VERSION ""

NS_ :

BS_:

BU_: IDC Delete_FDCA Delete_APA Delete_CMRR_FL Delete_CMRR_FR CMRR_RL CMRR_RR MRR CGW

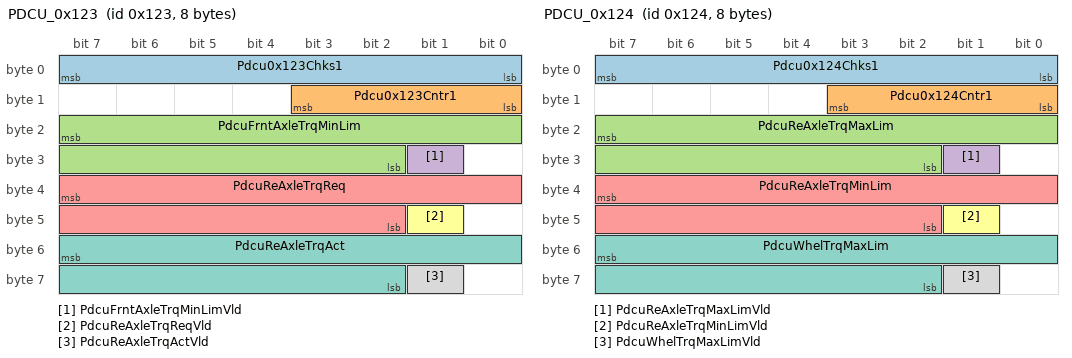
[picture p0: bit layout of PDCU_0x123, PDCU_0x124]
BO_ 291 PDCU_0x123: 8 CGW
 SG_ Pdcu0x123Chks1 : 7|8@0+ (1,0) [0|255] "" IDC,Delete_FDCA
 SG_ Pdcu0x123Cntr1 : 11|4@0+ (1,0) [0|14] "" IDC,Delete_FDCA
 SG_ PdcuFrntAxleTrqMinLim : 23|14@0+ (1,-6000) [-6000|10000] "Nm" IDC,Delete_FDCA
 SG_ PdcuFrntAxleTrqMinLimVld : 25|1@0+ (1,0) [0|1] "" IDC,Delete_FDCA
 SG_ PdcuReAxleTrqReq : 39|14@0+ (1,-6000) [-6000|10000] "Nm" IDC,Delete_FDCA
 SG_ PdcuReAxleTrqReqVld : 41|1@0+ (1,0) [0|1] "" IDC,Delete_FDCA
 SG_ PdcuReAxleTrqAct : 55|14@0+ (1,-6000) [-6000|10000] "Nm" IDC,Delete_FDCA
 SG_ PdcuReAxleTrqActVld : 57|1@0+ (1,0) [0|1] "" IDC,Delete_FDCA

BO_ 292 PDCU_0x124: 8 CGW
 SG_ Pdcu0x124Chks1 : 7|8@0+ (1,0) [0|255] "" IDC,Delete_FDCA
 SG_ Pdcu0x124Cntr1 : 11|4@0+ (1,0) [0|14] "" IDC,Delete_FDCA
 SG_ PdcuReAxleTrqMaxLim : 23|14@0+ (1,-6000) [-6000|10000] "Nm" IDC,Delete_FDCA
 SG_ PdcuReAxleTrqMaxLimVld : 25|1@0+ (1,0) [0|1] "" IDC,Delete_FDCA
 SG_ PdcuReAxleTrqMinLim : 39|14@0+ (1,-6000) [-6000|10000] "Nm" IDC,Delete_FDCA
 SG_ PdcuReAxleTrqMinLimVld : 41|1@0+ (1,0) [0|1] "" IDC,Delete_FDCA
 SG_ PdcuWhelTrqMaxLim : 55|14@0+ (1,-6000) [-6000|10000] "Nm" IDC,Delete_FDCA
 SG_ PdcuWhelTrqMaxLimVld : 57|1@0+ (1,0) [0|1] "" IDC,Delete_FDCA

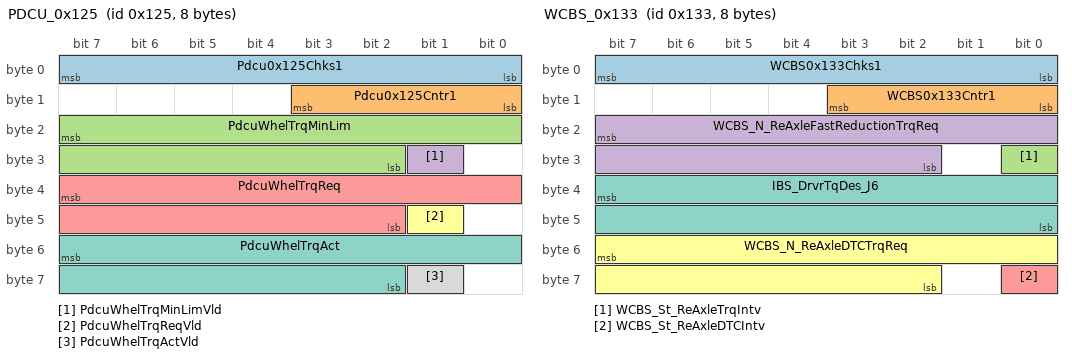
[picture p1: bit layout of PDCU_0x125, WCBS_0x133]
BO_ 293 PDCU_0x125: 8 CGW
 SG_ Pdcu0x125Chks1 : 7|8@0+ (1,0) [0|255] "" IDC,Delete_FDCA
 SG_ Pdcu0x125Cntr1 : 11|4@0+ (1,0) [0|14] "" IDC,Delete_FDCA
 SG_ PdcuWhelTrqMinLim : 23|14@0+ (1,-6000) [-6000|10000] "Nm" IDC,Delete_FDCA
 SG_ PdcuWhelTrqMinLimVld : 25|1@0+ (1,0) [0|1] "" IDC,Delete_FDCA
 SG_ PdcuWhelTrqReq : 39|14@0+ (1,-6000) [-6000|10000] "Nm" IDC,Delete_FDCA
 SG_ PdcuWhelTrqReqVld : 41|1@0+ (1,0) [0|1] "" IDC,Delete_FDCA
 SG_ PdcuWhelTrqAct : 55|14@0+ (1,-6000) [-6000|10000] "Nm" IDC,Delete_FDCA
 SG_ PdcuWhelTrqActVld : 57|1@0+ (1,0) [0|1] "" IDC,Delete_FDCA

BO_ 306 WCBS_0x132: 8 CGW
 SG_ WCBS0x132Chks1 : 7|8@0+ (1,0) [0|255] "" IDC,Delete_FDCA
 SG_ WCBS0x132Cntr1 : 11|4@0+ (1,0) [0|14] "" IDC,Delete_FDCA
 SG_ WCBS_St_FrntAxleTrqIntv : 24|1@0+ (1,0) [0|1] "" IDC,Delete_FDCA
 SG_ WCBS_N_FrntAxleFastReductionTrqReq : 23|14@0+ (1,-6000) [-6000|10000] "Nm" IDC,Delete_FDCA
 SG_ WCBS_St_FrntAxleDTCIntv : 56|1@0+ (1,0) [0|1] "" IDC,Delete_FDCA
 SG_ WCBS_N_FrntAxleDTCTrqReq : 55|14@0+ (1,-6000) [-6000|10000] "Nm" IDC,Delete_FDCA
 SG_ WCBS_RPAavailable : 32|1@0+ (1,0) [0|1] "" IDC
 SG_ WCBS_MEBavailable : 36|1@0+ (1,0) [0|1] "" IDC
 SG_ WCBS_APLCSts : 35|3@0+ (1,0) [0|7] "" IDC
 SG_ WCBS_ActvIndcn_MEB : 40|1@0+ (1,0) [0|1] "" IDC
 SG_ WCBS_APLCFailureSts : 39|3@0+ (1,0) [0|7] "" IDC
 SG_ WCBS_BrakeHld : 41|1@0+ (1,0) [0|1] "" IDC
 SG_ WCBS_ADASL12AvlSts : 44|1@0+ (1,0) [0|1] "" IDC
 SG_ WCBS_LgtReqModeACtiveSts : 43|2@0+ (1,0) [0|3] "" IDC
 SG_ WCBS_ADLCFailureSts : 47|3@0+ (1,0) [0|7] "" IDC
 SG_ WCBS_APAavailable : 25|1@0+ (1,0) [0|1] "" IDC
 SG_ WCBS_OMPavailable : 57|1@0+ (1,0) [0|1] "" IDC

BO_ 307 WCBS_0x133: 8 CGW
 SG_ WCBS0x133Chks1 : 7|8@0+ (1,0) [0|255] "" IDC,Delete_FDCA
 SG_ WCBS0x133Cntr1 : 11|4@0+ (1,0) [0|14] "" IDC,Delete_FDCA
 SG_ WCBS_St_ReAxleTrqIntv : 24|1@0+ (1,0) [0|1] "" IDC,Delete_FDCA
 SG_ WCBS_N_ReAxleFastReductionTrqReq : 23|14@0+ (1,-6000) [-6000|10000] "Nm" IDC,Delete_FDCA
 SG_ WCBS_St_ReAxleDTCIntv : 56|1@0+ (1,0) [0|1] "" IDC,Delete_FDCA
 SG_ WCBS_N_ReAxleDTCTrqReq : 55|14@0+ (1,-6000) [-6000|10000] "Nm" IDC,Delete_FDCA
 SG_ IBS_DrvrTqDes_J6 : 39|16@0+ (1,-65535) [-65535|0] "Nm" IDC

BO_ 337 MCUR0x151: 16 CGW
 SG_ TM2CrtTqVld : 15|2@0+ (1,0) [0|3] "" IDC,Delete_FDCA
 SG_ TM2CrtRotDir : 13|2@0+ (1,0) [0|3] "" IDC,Delete_FDCA
 SG_ TM2CrtSpd : 23|16@0+ (1,-32768) [-32768|32767] "rpm" IDC,Delete_FDCA
 SG_ TM2CrtTq : 39|16@0+ (0.1,-3276.8) [-3276.8|3276.7] "N·m" IDC,Delete_FDCA
 SG_ TM2CrtSpdSigVld : 50|2@0+ (1,0) [0|3] "" IDC,Delete_FDCA
 SG_ TM2ElockSt : 85|4@0+ (1,0) [0|6] "" IDC,Delete_FDCA,Delete_APA
 SG_ TM2ELockMod : 103|4@0+ (1,0) [0|8] "" IDC,Delete_FDCA,Delete_APA

BO_ 545 MCUR0x221: 32 CGW
 SG_ TM2MaxTqPeak : 87|16@0+ (0.1,-3276.8) [-3276.8|3276.7] "N·m" IDC,Delete_FDCA
 SG_ TM2MinTqPeak : 103|16@0+ (0.1,-3276.8) [-3276.8|3276.7] "N·m" IDC,Delete_FDCA
 SG_ TM2MaxTqCon : 151|16@0+ (0.1,-3276.8) [-3276.8|3276.7] "N·m" IDC,Delete_FDCA
 SG_ TM2MinTqCon : 167|16@0+ (0.1,-3276.8) [-3276.8|3276.7] "N·m" IDC,Delete_FDCA

BO_ 336 MCUF0x150: 16 CGW
 SG_ TM1CrtTqVld : 13|2@0+ (1,0) [0|3] "" IDC,Delete_FDCA
 SG_ TM1CrtRotDir : 15|2@0+ (1,0) [0|3] "" IDC,Delete_FDCA
 SG_ TM1CrtSpd : 23|16@0+ (1,-32768) [-32768|32767] "rpm" IDC,Delete_FDCA
 SG_ TM1CrtTq : 39|16@0+ (0.1,-3276.8) [-3276.8|3276.7] "N·m" IDC,Delete_FDCA
 SG_ TM1CrtSpdSigVld : 54|2@0+ (1,0) [0|3] "" IDC,Delete_FDCA

BO_ 551 MCUF0x227: 32 CGW
 SG_ TM1MaxTqPeak : 87|16@0+ (0.1,-3276.8) [-3276.8|3276.7] "N·m" IDC,Delete_FDCA
 SG_ TM1MinTqPeak : 103|16@0+ (0.1,-3276.8) [-3276.8|3276.7] "N·m" IDC,Delete_FDCA
 SG_ TM1MaxTqCon : 151|16@0+ (0.1,-3276.8) [-3276.8|3276.7] "N·m" IDC,Delete_FDCA
 SG_ TM1MinTqCon : 167|16@0+ (0.1,-3276.8) [-3276.8|3276.7] "N·m" IDC,Delete_FDCA

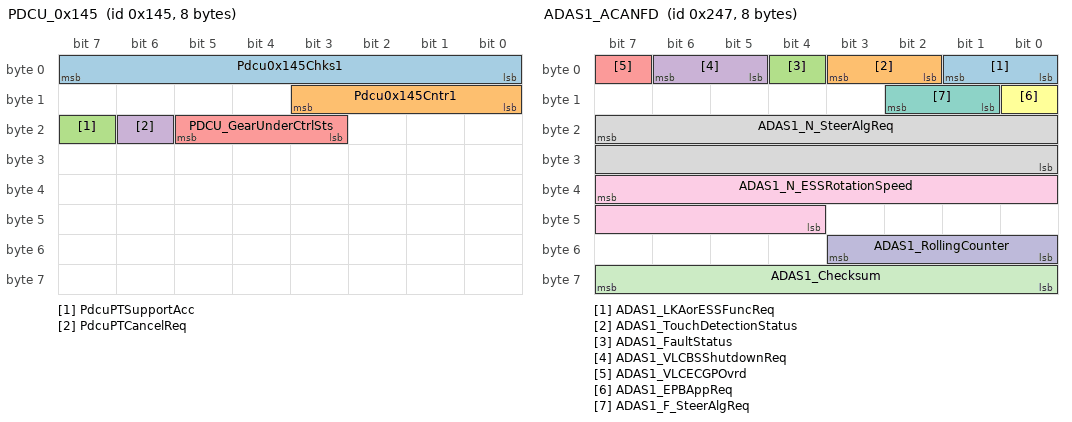
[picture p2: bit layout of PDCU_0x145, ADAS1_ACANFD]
BO_ 325 PDCU_0x145: 8 CGW
 SG_ Pdcu0x145Chks1 : 7|8@0+ (1,0) [0|255] "" IDC,Delete_FDCA,Delete_APA
 SG_ Pdcu0x145Cntr1 : 11|4@0+ (1,0) [0|14] "" IDC,Delete_FDCA,Delete_APA
 SG_ PdcuPTSupportAcc : 23|1@0+ (1,0) [0|1] "" IDC,Delete_FDCA
 SG_ PdcuPTCancelReq : 22|1@0+ (1,0) [0|1] "" IDC,Delete_FDCA
 SG_ PDCU_GearUnderCtrlSts : 21|3@0+ (1,0) [0|7] "" IDC,Delete_APA

BO_ 583 ADAS1_ACANFD: 8 IDC
 SG_ ADAS1_LKAorESSFuncReq : 1|2@0+ (1,0) [0|3] "" CGW
 SG_ ADAS1_TouchDetectionStatus : 3|2@0+ (1,0) [0|3] "" Vector__XXX
 SG_ ADAS1_FaultStatus : 4|1@0+ (1,0) [0|1] "" Vector__XXX
 SG_ ADAS1_VLCBSShutdownReq : 6|2@0+ (1,0) [0|3] "" Vector__XXX
 SG_ ADAS1_VLCECGPOvrd : 7|1@0+ (1,0) [0|1] "" Vector__XXX
 SG_ ADAS1_EPBAppReq : 8|1@0+ (1,0) [0|1] "" Vector__XXX
 SG_ ADAS1_F_SteerAlgReq : 10|2@0+ (1,0) [0|3] "" CGW
 SG_ ADAS1_N_SteerAlgReq : 23|16@0+ (0.1,-780) [-780|780] "°" CGW
 SG_ ADAS1_N_ESSRotationSpeed : 39|12@0+ (1,-2048) [-2048|2046] "degree/ sec" CGW
 SG_ ADAS1_RollingCounter : 51|4@0+ (1,0) [0|15] "" CGW
 SG_ ADAS1_Checksum : 63|8@0+ (1,0) [0|255] "" CGW

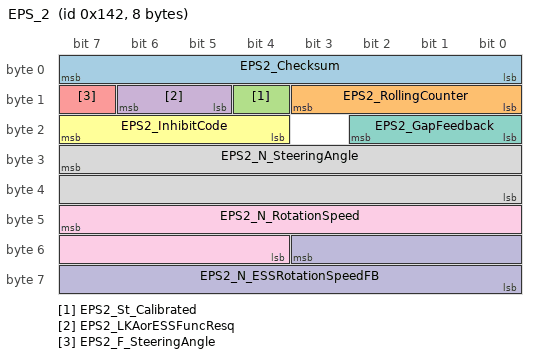
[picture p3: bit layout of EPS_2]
BO_ 322 EPS_2: 8 CGW
 SG_ EPS2_Checksum : 7|8@0+ (1,0) [0|15] "" IDC,Delete_FDCA,Delete_APA
 SG_ EPS2_RollingCounter : 11|4@0+ (1,0) [0|15] "" IDC,Delete_FDCA,Delete_APA
 SG_ EPS2_St_Calibrated : 12|1@0+ (1,0) [0|1] "" IDC,Delete_FDCA,Delete_APA
 SG_ EPS2_LKAorESSFuncResq : 14|2@0+ (1,0) [0|3] "" IDC,Delete_FDCA,Delete_APA
 SG_ EPS2_F_SteeringAngle : 15|1@0+ (1,0) [0|1] "" IDC,Delete_FDCA,Delete_APA
 SG_ EPS2_InhibitCode : 23|4@0+ (1,0) [0|15] "" IDC,Delete_FDCA,Delete_APA
 SG_ EPS2_GapFeedback : 18|3@0+ (1,0) [0|7] "" IDC,Delete_FDCA,Delete_APA
 SG_ EPS2_N_SteeringAngle : 31|16@0+ (0.1,-780) [-780|780] "degree" IDC,Delete_FDCA,Delete_APA
 SG_ EPS2_N_RotationSpeed : 47|12@0+ (4,-1016) [-1016|1016] "degree/ sec" IDC,Delete_FDCA,Delete_APA
 SG_ EPS2_N_ESSRotationSpeedFB : 51|12@0+ (1,-2048) [-2048|2046] "degree/ sec" IDC,Delete_FDCA,Delete_APA

BO_ 1508 FDCA_1: 8 IDC
 SG_ FDCA1_St_SLASpdlimit : 7|8@0+ (1,0) [0|255] "" CGW
 SG_ FDCA1_St_SLAWarning : 15|2@0+ (1,0) [0|3] "" CGW
 SG_ ADAS_FDCA1_St_SLASpeedLimitUnit : 13|2@0+ (1,0) [0|3] "" CGW
 SG_ FDCA1_St_LDWMode : 11|3@0+ (1,0) [0|7] "" CGW
 SG_ ADAS_FDCA1_ESS_SwitchSts : 8|1@0+ (1,0) [0|1] "" CGW
 SG_ FDCA1_St_AEBMode : 23|2@0+ (1,0) [0|3] "" CGW
 SG_ FDCA1_St_LKA : 21|3@0+ (1,0) [0|7] "" CGW
 SG_ FDCA1_St_TSRMode : 18|3@0+ (1,0) [0|7] "" CGW
 SG_ FDCA1_W_Handsoff : 31|2@0+ (1,0) [0|3] "" CGW
 SG_ ADAS_FDCA1_AdasSafestopAppdReq : 29|2@0+ (1,0) [0|3] "" CGW
 SG_ ADAS_FDCA1_Sts_ESS : 27|4@0+ (1,0) [0|7] "" CGW
 SG_ ADAS_FDCA1_St_FCWMode : 39|3@0+ (1,0) [0|7] "" CGW
 SG_ ADAS_FDCA1_St_TSRwarning : 35|1@0+ (1,0) [0|1] "" CGW
 SG_ ADAS_FDCA1_LDW_meter_Warning : 34|2@0+ (1,0) [0|3] "" CGW
 SG_ ADC_PrivacyAgreementSts : 42|2@0+ (1,0) [0|1] "" CGW
 SG_ FDCA1_St_VehicleMode : 40|3@0+ (1,0) [0|7] "" CGW
 SG_ ADAS_FDCA1_ESSTraj : 53|2@0+ (1,0) [0|3] "" CGW
 SG_ FDCA1_RollingCounter : 51|4@0+ (1,0) [0|15] "" CGW
 SG_ FDCA1_CheckSum : 63|8@0+ (1,0) [0|255] "" CGW

BO_ 1351 FDCA_2: 8 IDC
 SG_ FDCA2_N_vSetDisp : 7|8@0+ (1,0) [0|255] "KPH" CGW
 SG_ FDCA2_St_dxTarObj : 15|3@0+ (1,0) [0|7] "" CGW
 SG_ FDCA2_St_TauGapSet : 12|3@0+ (1,0) [0|7] "" CGW
 SG_ FDCA2_St_LateralTakeoverReq : 9|1@0+ (1,0) [0|1] "" CGW
 SG_ FDCA2_St_HighbeamReq : 8|1@0+ (1,0) [0|1] "" CGW
 SG_ FDCA2_St_HMA : 23|3@0+ (1,0) [0|7] "" CGW
 SG_ FDCA2_St_ACCMode_HMI : 20|4@0+ (1,0) [0|15] "" CGW
 SG_ ADAS_SafeStopHazardLlightReq : 16|1@0+ (1,0) [0|1] "" CGW
 SG_ FDCA2_St_TakeOverReq : 31|1@0+ (1,0) [0|1] "" CGW
 SG_ FDCA2_St_LeftVisualization : 30|2@0+ (1,0) [0|3] "" CGW
 SG_ ADAS_FDCA2_St_TauGapWinRequest : 28|1@0+ (1,0) [0|1] "" CGW
 SG_ ADAS_NOA_Right_turn_light_Req : 27|1@0+ (1,0) [0|1] "" CGW
 SG_ ADAS_NOA_left_turn_light_Req : 26|1@0+ (1,0) [0|1] "" CGW
 SG_ FDCA2_St_RightVisualization : 25|2@0+ (1,0) [0|3] "" CGW
 SG_ FDCA2_St_TJA_ICA_mode : 39|3@0+ (1,0) [0|7] "" CGW
 SG_ ADAS_FDCA2_AccObjDetd : 36|1@0+ (1,0) [0|1] "" Vector__XXX
 SG_ FDCA2_AccTxtInfo : 35|4@0+ (1,0) [0|15] "" CGW
 SG_ FDCA2_St_Camera : 47|2@0+ (1,0) [0|3] "" CGW
 SG_ FDCA2_W_Distance : 45|1@0+ (1,0) [0|1] "" CGW
 SG_ FDCA2_St_FCWSensitivity : 44|2@0+ (1,0) [0|3] "" CGW
 SG_ ADAS_SafeStopDoorUnlockReq : 42|1@0+ (1,0) [0|1] "" CGW
 SG_ FDCA2_W_FCWpreWarning : 41|2@0+ (1,0) [0|3] "" CGW
 SG_ ADAS_St_LowbeamReq : 54|1@0+ (1,0) [0|1] "" CGW
 SG_ FDCA2_St_TSR : 53|2@0+ (1,0) [0|3] "" CGW
 SG_ FDCA2_RollingCounter : 51|4@0+ (1,0) [0|15] "" CGW
 SG_ FDCA2_Checksum : 63|8@0+ (1,0) [0|255] "" CGW

BO_ 915 ADAS2_ACANFD: 64 IDC
 SG_ ADAS2_Checksum1 : 7|8@0+ (1,0) [0|255] "" CGW
 SG_ ADAS2_RollingCounter1 : 11|4@0+ (1,0) [0|15] "" CGW
 SG_ ADAS2_Radar_TextInfo : 39|4@0+ (1,0) [0|15] "" CGW
 SG_ ADAS2_AccfobjDrvAwayinfo : 40|1@0+ (1,0) [0|1] "" CGW
 SG_ ADAS2_TLA_WarnSign : 43|2@0+ (1,0) [0|3] "" CGW
 SG_ ADAS2_St_MRR : 45|2@0+ (1,0) [0|3] "" CGW
 SG_ ADAS2_Accdrivemode : 47|2@0+ (1,0) [0|3] "" CGW
 SG_ ADAS2_ASLSts : 50|3@0+ (1,0) [0|7] "" CGW
 SG_ ADAS2_ASLSpdlim : 55|5@0+ (1,0) [0|31] "" CGW
 SG_ ADAS2_St_TJA_ICA_Textinfo : 59|4@0+ (1,0) [0|15] "" CGW
 SG_ ADAS2_ASLSwtfb : 60|1@0+ (1,0) [0|1] "" CGW
 SG_ ADAS2_ALCSts : 63|3@0+ (1,0) [0|3] "" CGW
 SG_ ADAS2_Checksum2 : 71|8@0+ (1,0) [0|255] "" CGW
 SG_ ADAS1_RollingCounter2 : 75|4@0+ (1,0) [0|15] "" CGW
 SG_ ADAS2_NOASts : 79|4@0+ (1,0) [0|15] "" CGW
 SG_ ADAS2_HwaAlcSwtFb : 80|1@0+ (1,0) [0|1] "" CGW
 SG_ ADAS2_TJA_ICA__EnbSwtFb : 81|1@0+ (1,0) [0|1] "" CGW
 SG_ ADAS2_NOA_ALC_TYPE_SwtFb : 83|2@0+ (1,0) [0|3] "" CGW
 SG_ ADAS2_NOA_ALCRequest_confirm_Fb : 84|1@0+ (1,0) [0|1] "" CGW
 SG_ ADAS2_NOA_ALCSoundnotification_SwtFb : 85|1@0+ (1,0) [0|1] "" CGW
 SG_ ADAS2_IntelligentCornering_EnbSw_SwtFb : 86|1@0+ (1,0) [0|1] "" CGW
 SG_ ADAS2_NOASwtFb : 87|1@0+ (1,0) [0|1] "" CGW
 SG_ ADAS2_DrvrHandsoffRmn : 95|8@0+ (0.5,0) [0|127] "" CGW
 SG_ ADAS2_DriverHandsoff : 96|1@0+ (1,0) [0|1] "" CGW
 SG_ ADAS2_ICATJATakeoverReq : 99|3@0+ (1,0) [0|7] "" CGW
 SG_ ADAS2_ALCHmiEgoLaneChg : 103|4@0+ (1,0) [0|15] "" CGW
 SG_ ADAS2_ALCActvToTakeover : 107|4@0+ (1,0) [0|15] "" CGW
 SG_ ADAS2_NLP_FctActvRmm : 111|4@0+ (1,0) [0|15] "" CGW
 SG_ ADAS2_NLPTakeoverReq : 114|3@0+ (1,0) [0|7] "" CGW
 SG_ ADAS2_TJAICA_LINE_SOURCE : 116|2@0+ (1,0) [0|3] "" CGW
 SG_ ADAS2_ALCNotAvlReas : 119|3@0+ (1,0) [0|7] "" CGW
 SG_ ADAS2_NOAHmiDispdTxtMsgId : 125|6@0+ (1,0) [0|63] "" CGW
 SG_ ADAS2_TLA_SwitchSts : 127|2@0+ (1,0) [0|3] "" CGW
 SG_ ADAS2_Checksum3 : 135|8@0+ (1,0) [0|255] "" CGW
 SG_ ADAS2_RollingCounter3 : 139|4@0+ (1,0) [0|15] "" CGW
 SG_ ADAS2_NOAODDTyp : 143|4@0+ (1,0) [0|15] "" CGW
 SG_ ADAS2_NOADstToODD : 148|5@0+ (1,0) [0|31] "" CGW
 SG_ ADAS2_TextinfoForIntelligentCornering : 151|2@0+ (1,0) [0|3] "" CGW
 SG_ ADAS2_NotAvlReas : 155|4@0+ (1,0) [0|15] "" CGW
 SG_ ADAS2_HmiAudioNotifId : 159|4@0+ (1,0) [0|15] "" CGW
 SG_ ADAS2_ADASQuitReas : 164|5@0+ (1,0) [0|31] "" CGW
 SG_ ADAS2_Set_TJA_ICA_ACC : 166|2@0+ (1,0) [0|3] "" CGW
 SG_ ADAS2_St_left_front_Camera : 169|2@0+ (1,0) [0|3] "" CGW
 SG_ ADAS2_St_right_front_Camera : 171|2@0+ (1,0) [0|3] "" CGW
 SG_ ADAS2_St_LDWLKALCKSenFb : 173|2@0+ (1,0) [0|3] "" CGW
 SG_ ADAS2_Sw_LDWLKALCKFb : 175|2@0+ (1,0) [0|3] "" CGW
 SG_ ADAS2_St_LDWLKALCKSetFb : 178|3@0+ (1,0) [0|7] "" CGW
 SG_ ADAS2_SwFb_ELK : 180|2@0+ (1,0) [0|3] "" CGW
 SG_ ADAS2_St_LDWLKALCK : 183|3@0+ (1,0) [0|7] "" CGW
 SG_ ADAS2_St_ELK : 185|2@0+ (1,0) [0|3] "" CGW
 SG_ ADAS2_St_ELKIntvMod : 188|3@0+ (1,0) [0|7] "" CGW
 SG_ ADAS2_SwFb_HMA : 191|2@0+ (1,0) [0|3] "" CGW
 SG_ ADAS2_Checksum4 : 199|8@0+ (1,0) [0|255] "" CGW
 SG_ ADAS2_RollingCounter4 : 203|4@0+ (1,0) [0|15] "" CGW
 SG_ ADAS2_SDASts : 206|3@0+ (1,0) [0|7] "" CGW
 SG_ ADAS2_DodgeDirection_SDA : 207|1@0+ (1,0) [0|1] "" CGW
 SG_ ADAS2_TgtVehicleID_SDA : 211|4@0+ (1,0) [0|15] "" CGW
 SG_ ADAS2_ALC_HMIlaneBlock : 213|2@0+ (1,0) [0|3] "" CGW
 SG_ ADAS2_TSR_SwtFb : 215|2@0+ (1,0) [0|3] "" CGW
 SG_ ADAS2_SwFb_SDA : 217|2@0+ (1,0) [0|3] "" CGW
 SG_ ADAS_FDCA1_SLA_SwitchSts : 219|2@0+ (1,0) [0|3] "" CGW
 SG_ ADAS_FDCA1_SLA_SpdLimOffs : 223|4@0+ (1,0) [0|15] "KPH" CGW
 SG_ ADAS2_AEBTxtInfo : 227|4@0+ (1,0) [0|15] "" CGW
 SG_ ADAS2_FcwTxtInfo : 231|4@0+ (1,0) [0|15] "" CGW
 SG_ ADAS2_TsrSignMisc : 236|5@0+ (1,0) [0|32] "" CGW
 SG_ ADAS2_St_SLAMode : 239|3@0+ (1,0) [0|7] "" CGW
 SG_ ADAS2_St_SLAFault : 241|2@0+ (1,0) [0|3] "" CGW
 SG_ ADAS2_FcwSwtFb : 243|2@0+ (1,0) [0|3] "" CGW
 SG_ ADAS2_AebSwtFb : 245|2@0+ (1,0) [0|3] "" CGW
 SG_ ADAS_FDCA1_SLAWarn_SwitchSts : 247|2@0+ (1,0) [0|3] "" CGW
 SG_ ADAS2_AebReq : 250|3@0+ (1,0) [0|7] "" CGW
 SG_ ADAS2_HWASts : 255|4@0+ (1,0) [0|15] "" CGW
 SG_ ADAS2_Checksum5 : 263|8@0+ (1,0) [0|255] "" CGW
 SG_ ADAS2_RollingCounter5 : 267|4@0+ (1,0) [0|15] "" CGW
 SG_ ADAS2_BvmSetFb : 269|2@0+ (1,0) [0|3] "" CGW
 SG_ ADAS2_BvmDispReq : 271|2@0+ (1,0) [0|3] "" CGW
 SG_ ADAS2_St_left_rear_Camera : 273|2@0+ (1,0) [0|3] "" CGW
 SG_ ADAS2_St_right_rear_Camera : 275|2@0+ (1,0) [0|3] "" CGW
 SG_ ADAS2_BvmViewMod : 276|1@0+ (1,0) [0|1] "" CGW
 SG_ ADAS2_St_ELKSenFeedback : 278|2@0+ (1,0) [0|3] "" CGW
 SG_ ADC_ADASYSSTS : 279|1@0+ (1,0) [0|1] "" Vector__XXX
 SG_ ADC_enum_PrkgBuzAlrmLvlReq : 282|3@0+ (1,0) [0|7] "" Vector__XXX
 SG_ ADC_SysStartupInPro : 283|1@0+ (1,0) [0|1] "" Vector__XXX
 SG_ ADC_IMUSentiWarningSts : 286|3@0+ (1,0) [0|7] "" Vector__XXX
 SG_ MPC_SOCOffSwtFb : 295|2@0+ (1,0) [0|3] "" Vector__XXX

BO_ 547 ADAS3_ACANFD: 64 IDC
 SG_ AdasHmiNeighboringObj1ObjTyp : 7|3@0+ (1,0) [0|7] "" CGW
 SG_ Obj1Ttc : 4|5@0+ (0.1,0) [0|3.1] "" CGW
 SG_ AdasHmiNeighboringObj1XOut : 15|8@0+ (1.2,-50) [-50|250] "m" CGW
 SG_ AdasHmiNeighboringObj1YOut : 23|8@0+ (0.06,-7.5) [-7.5|7.5] "m" CGW
 SG_ Obj1VX : 31|13@0+ (0.0312,-128) [-128|126.9976] "m/s" CGW
 SG_ Obj1ObjExistProb : 47|5@0+ (0.03125,0) [0|0.96875] "" CGW
 SG_ Obj1Hei : 42|9@0+ (0.01,0) [0|5.11] "m" CGW
 SG_ Obj1Width : 49|9@0+ (0.01,0) [0|5.11] "m" CGW
 SG_ AdasHmiNeighboringObj2ObjTyp : 71|3@0+ (1,0) [0|7] "" CGW
 SG_ Obj2ObjExistProb : 68|5@0+ (0.03125,0) [0|0.96875] "" CGW
 SG_ AdasHmiNeighboringObj2XOut : 79|8@0+ (1.2,-50) [-50|250] "m" CGW
 SG_ AdasHmiNeighboringObj2YOut : 87|8@0+ (0.06,-7.5) [-7.5|7.5] "m" CGW
 SG_ Obj2VelX : 95|13@0+ (0.0312,-128) [-128|126.9976] "m/s" CGW
 SG_ AdasHmiNeighboringObj3ObjTyp : 111|3@0+ (1,0) [0|7] "-" CGW
 SG_ Obj3ObjExistProb : 108|5@0+ (0.03125,0) [0|0.96875] "" CGW
 SG_ AdasHmiNeighboringObj3XOut : 119|8@0+ (1.2,-50) [-50|250] "m" CGW

BO_TX_BU_ 583 : IDC,Delete_FDCA;

BO_TX_BU_ 1508 : IDC,Delete_FDCA;

BO_TX_BU_ 1351 : IDC,Delete_FDCA;

BO_TX_BU_ 915 : IDC,Delete_FDCA;

BO_TX_BU_ 547 : IDC,Delete_FDCA;
CM_ BO_ 583 "控制，ADAS1_F_SteerAlgReq与B41不一致";
CM_ BO_ 1508 "显示";
CM_ BO_ 1351 "显示";
CM_ BO_ 915 "显示";
CM_ BO_ 547 "HMI 目标车辆信息，12个";
CM_ SG_ 583 ADAS1_LKAorESSFuncReq "ADAS系统EPS请求类型，表示是LKA还是ESS";
CM_ SG_ 583 ADAS1_TouchDetectionStatus "驾驶员的手是否放在方向盘上";
CM_ SG_ 583 ADAS1_FaultStatus "系统失效状态，此信号表示自动ADAS系统失效状态";
CM_ SG_ 583 ADAS1_VLCBSShutdownReq "ADAS 退出VLC";
CM_ SG_ 583 ADAS1_VLCECGPOvrd "ADAS 功能是否由驾驶员踩油门接管车辆扭矩状态";
CM_ SG_ 583 ADAS1_EPBAppReq "表示请求拉起EPB 信号";
CM_ SG_ 583 ADAS1_F_SteerAlgReq "转角请求状态ADAS对EPS的补偿角度请求状态";
CM_ SG_ 583 ADAS1_N_SteerAlgReq "转角请求ADAS对EPS的补偿角度请求";
CM_ SG_ 583 ADAS1_N_ESSRotationSpeed "ESS功能请求方向盘转速";
CM_ SG_ 583 ADAS1_RollingCounter "Message counter for each message transmittedThe transmitter shall update the value of the Message Counter signal every time a frame is transmitted (even if no other data in the frame has changed value). The counter value shall be updated in the sequence 0, 1, 2, 3......15, 0, 1, 2, 3......15, etc. Upon startup,the initial value of the Message Counter signal shall be 0.";
CM_ SG_ 583 ADAS1_Checksum "Checksum = (byte0+byte1+…+byte 6）and 0xFF";
CM_ SG_ 1508 FDCA1_St_SLASpdlimit "Speed Limit速度限制；最高车速";
CM_ SG_ 1508 FDCA1_St_SLAWarning "SLA Warning";
CM_ SG_ 1508 ADAS_FDCA1_St_SLASpeedLimitUnit "SLA Speed Limit UnitSLA限速单位";
CM_ SG_ 1508 FDCA1_St_LDWMode "LDW Mode";
CM_ SG_ 1508 ADAS_FDCA1_ESS_SwitchSts "ESS开关状态反馈信号";
CM_ SG_ 1508 FDCA1_St_AEBMode "AEB Mode（预留），删除";
CM_ SG_ 1508 FDCA1_St_LKA "LKA Mode";
CM_ SG_ 1508 FDCA1_St_TSRMode "TSR Mode";
CM_ SG_ 1508 FDCA1_W_Handsoff "脱手检测报警信号";
CM_ SG_ 1508 ADAS_FDCA1_AdasSafestopAppdReq "Safe stop: Brake actuator shall be able to secure the vehicle by activating the ESP/EPB. ECALL shall be connecting by T-box";
CM_ SG_ 1508 ADAS_FDCA1_Sts_ESS "ESS功能状态，状态机";
CM_ SG_ 1508 ADAS_FDCA1_St_FCWMode "FCW Mode";
CM_ SG_ 1508 ADAS_FDCA1_St_TSRwarning "TSR失效状态";
CM_ SG_ 1508 ADAS_FDCA1_LDW_meter_Warning "LDW报警";
CM_ SG_ 1508 ADC_PrivacyAgreementSts "查询整车隐私协议开关";
CM_ SG_ 1508 FDCA1_St_VehicleMode "FDCA接收到车辆模式信号后返回的状态信号";
CM_ SG_ 1508 ADAS_FDCA1_ESSTraj "ESS规划路径状态";
CM_ SG_ 1508 FDCA1_RollingCounter "Message counter for each message transmittedThe transmitter shall update the value of the Message Counter signal every time a frame is transmitted (even if no other data in theframe has changed value). The counter value shall be updated in the sequence 0, 1, 2, 3......15, 0, 1, 2, 3......15, etc. Upon startup,theinitial value of the Message Counter signal shall be 0.";
CM_ SG_ 1508 FDCA1_CheckSum "Checksum = (byte0+byte1+…+byte 6）and 0xFF";
CM_ SG_ 1351 FDCA2_N_vSetDisp "the set speed from driver, should be available as long as ACC is active.";
CM_ SG_ 1351 FDCA2_St_dxTarObj "distance to the ahead target object in case of 'mid-end' HMI.";
CM_ SG_ 1351 FDCA2_St_TauGapSet "the set time Gap from driver, should be displayed to driver and if the set value changes.";
CM_ SG_ 1351 FDCA2_St_LateralTakeoverReq "Horizontal function takeover request";
CM_ SG_ 1351 FDCA2_St_HighbeamReq "High beam Request";
CM_ SG_ 1351 FDCA2_St_HMA "HMA Mode (light switching function) HMA状态机（远近灯光切换功能）";
CM_ SG_ 1351 FDCA2_St_ACCMode_HMI "The status of the ACC control unit.The ACC mode should be contained in every message sent by ACC.";
CM_ SG_ 1351 ADAS_SafeStopHazardLlightReq "Safe stop: need turn on the hazard light";
CM_ SG_ 1351 FDCA2_St_TakeOverReq "the limits of the ACC control reaches, driver should take over.";
CM_ SG_ 1351 FDCA2_St_LeftVisualization "LDW/LKA Left Side InterventionLDW/LKA左侧介入";
CM_ SG_ 1351 ADAS_FDCA2_St_TauGapWinRequest "TauGap Windows Request ";
CM_ SG_ 1351 ADAS_NOA_Right_turn_light_Req "NOA右变道灯请求";
CM_ SG_ 1351 ADAS_NOA_left_turn_light_Req "NOA左变道灯请求";
CM_ SG_ 1351 FDCA2_St_RightVisualization "LDW/LKA Right Side InterventionLDW/LKA右侧介入";
CM_ SG_ 1351 FDCA2_St_TJA_ICA_mode "TJA ModeTJA状态机";
CM_ SG_ 1351 ADAS_FDCA2_AccObjDetd "an ahead target object detected by ACC, to inform the driver 一般会与ACC_DIS_TO_TAROBJECT同时显示，但是当只打开ACC的主开关，但是没有激活ACC功能的话，ACC_DIS_TO_TAROBJECT不会显示，但这个信号会显示。";
CM_ SG_ 1351 FDCA2_AccTxtInfo "Textinfo for Driver which is displayed in Dashboard";
CM_ SG_ 1351 FDCA2_St_Camera "Camera status information摄像头状态信息";
CM_ SG_ 1351 FDCA2_W_Distance "DistanceWarning";
CM_ SG_ 1351 FDCA2_St_FCWSensitivity "FCW灵敏度设置反馈信号";
CM_ SG_ 1351 ADAS_SafeStopDoorUnlockReq "Safe stop: need tunlock the door when the vehicle is standstill ";
CM_ SG_ 1351 FDCA2_W_FCWpreWarning "acoustic pre warning.Used with FCW_Enable signal.";
CM_ SG_ 1351 ADAS_St_LowbeamReq "近光灯信号请求";
CM_ SG_ 1351 FDCA2_St_TSR "TSR报警模式选择";
CM_ SG_ 1351 FDCA2_RollingCounter "Message counter for each message transmittedThe transmitter shall update the value of the Message Counter signal every time a frame is transmitted (even if no other data in theframe has changed value). The counter value shall be updated in the sequence 0, 1, 2, 3......15, 0, 1, 2, 3......15, etc. Upon startup,theinitial value of the Message Counter signal shall be 0.";
CM_ SG_ 1351 FDCA2_Checksum "Checksum = (byte0+byte1+…+byte 6）and 0xFF";
CM_ SG_ 915 ADAS2_Checksum1 "Checksum = (byte1+byte2+…+byte 7）and 0xFF";
CM_ SG_ 915 ADAS2_RollingCounter1 "Message counter for each message transmittedThe transmitter shall update the value of the Message Counter signal every time a frame is transmitted (even if no other data in the frame has changed value). The counter value shall be updated in the sequence 0, 1, 2, 3......15, 0, 1, 2, 3......15, etc. Upon startup,the initial value of the Message Counter signal shall be 0.";
CM_ SG_ 915 ADAS2_Radar_TextInfo "雷达文字弹窗提醒";
CM_ SG_ 915 ADAS2_AccfobjDrvAwayinfo "Indacating front vehicle drive away or not, used for ICM reminder. When front vehicle drives away, the signal will be set to 0x1.前车驶离提示。";
CM_ SG_ 915 ADAS2_TLA_WarnSign "TLA交通灯识别信号";
CM_ SG_ 915 ADAS2_St_MRR "Mrr status information雷达状态信息";
CM_ SG_ 915 ADAS2_Accdrivemode "indicate the Status of ACC acceleration calibration line。";
CM_ SG_ 915 ADAS2_ASLSts "Adaptive Speed Limiter StatusStatus of ASL function";
CM_ SG_ 915 ADAS2_ASLSpdlim "Speed limit values for ASL function";
CM_ SG_ 915 ADAS2_St_TJA_ICA_Textinfo "TJA Status text infomationTJA状态文字";
CM_ SG_ 915 ADAS2_ASLSwtfb "ASL开关状态反馈";
CM_ SG_ 915 ADAS2_ALCSts "State Machine for ALC for HMI";
CM_ SG_ 915 ADAS2_Checksum2 "Checksum = (byte9+byte10+…+byte 15）and 0xFF";
CM_ SG_ 915 ADAS1_RollingCounter2 "Message counter for each message transmittedThe transmitter shall update the value of the Message Counter signal every time a frame is transmitted (even if no other data in the frame has changed value). The counter value shall be updated in the sequence 0, 1, 2, 3......15, 0, 1, 2, 3......15, etc. Upon startup,the initial value of the Message Counter signal shall be 0.";
CM_ SG_ 915 ADAS2_NOASts "NOA状态";
CM_ SG_ 915 ADAS2_HwaAlcSwtFb "HWA ALC switch feedback";
CM_ SG_ 915 ADAS2_TJA_ICA__EnbSwtFb "tja/ica  switch feedback";
CM_ SG_ 915 ADAS2_NOA_ALC_TYPE_SwtFb "NOA_ALC_TYPE switch feedback";
CM_ SG_ 915 ADAS2_NOA_ALCRequest_confirm_Fb "NOA_ALCRequest_confirm switch feedback";
CM_ SG_ 915 ADAS2_NOA_ALCSoundnotification_SwtFb "NOA_ALC_soundnotification switch feedback";
CM_ SG_ 915 ADAS2_IntelligentCornering_EnbSw_SwtFb "Intelligent cornering_EnbSw switch feedback";
CM_ SG_ 915 ADAS2_NOASwtFb "HWA HF switch feedback.Reserved.";
CM_ SG_ 915 ADAS2_DrvrHandsoffRmn "Instruct the driver hands off to drop the count";
CM_ SG_ 915 ADAS2_DriverHandsoff "Indicates whether the driver's hands are on the steering wheel";
CM_ SG_ 915 ADAS2_ICATJATakeoverReq "脱手报警TJA or ICA Take over request to driver";
CM_ SG_ 915 ADAS2_ALCHmiEgoLaneChg "Indicates when the ego vehicle plans or performs a lane change";
CM_ SG_ 915 ADAS2_ALCActvToTakeover "ALC active to takeover reason";
CM_ SG_ 915 ADAS2_NLP_FctActvRmm "NLP Function Active reminder";
CM_ SG_ 915 ADAS2_NLPTakeoverReq "NLP Take over request to driver";
CM_ SG_ 915 ADAS2_TJAICA_LINE_SOURCE "The line source of TJA ICA.video 视觉模式，基于video识别的车道线进行控制;DOP Drive Object Path，基于目标车辆进行控制; TIPL Traffic in Parallel Line ，基于车流轨迹算法给出的车道线进行控制.";
CM_ SG_ 915 ADAS2_ALCNotAvlReas "ADAS ALC  function not available Reason";
CM_ SG_ 915 ADAS2_NOAHmiDispdTxtMsgId "Displays visual text notfications on the cockpit ";
CM_ SG_ 915 ADAS2_TLA_SwitchSts "TLA开关状态反馈信号";
CM_ SG_ 915 ADAS2_Checksum3 "Checksum = (byte17+byte18+…+byte 23）and 0xFF";
CM_ SG_ 915 ADAS2_RollingCounter3 "Message counter for each message transmittedThe transmitter shall update the value of the Message Counter signal every time a frame is transmitted (even if no other data in the frame has changed value). The counter value shall be updated in the sequence 0, 1, 2, 3......15, 0, 1, 2, 3......15, etc. Upon startup,the initial value of the Message Counter signal shall be 0.";
CM_ SG_ 915 ADAS2_NOAODDTyp "the next ODD‘s type";
CM_ SG_ 915 ADAS2_NOADstToODD "The distance to ODD area when NOA is on";
CM_ SG_ 915 ADAS2_TextinfoForIntelligentCornering "智能过弯文字提示";
CM_ SG_ 915 ADAS2_NotAvlReas "ADAS function not available Reason";
CM_ SG_ 915 ADAS2_HmiAudioNotifId "Plays back an auditory sound notification, e.g. warning sound or speech message.";
CM_ SG_ 915 ADAS2_ADASQuitReas "ADAS function exit Reason";
CM_ SG_ 915 ADAS2_Set_TJA_ICA_ACC "TJAICA、ACC巡航状态反馈";
CM_ SG_ 915 ADAS2_St_left_front_Camera "左前侧视摄像头状态";
CM_ SG_ 915 ADAS2_St_right_front_Camera "右前侧视摄像头状态";
CM_ SG_ 915 ADAS2_St_LDWLKALCKSenFb "LDW/LKA/LCK灵敏度设置反馈信号";
CM_ SG_ 915 ADAS2_Sw_LDWLKALCKFb "LDW/LKA/LCK系统上层软开关反馈信号";
CM_ SG_ 915 ADAS2_St_LDWLKALCKSetFb "辅助类型选择开关反馈信号";
CM_ SG_ 915 ADAS2_SwFb_ELK "ELK开启关闭反馈状态信号";
CM_ SG_ 915 ADAS2_St_LDWLKALCK "LDW/LKA/LCK系统工作状态信号";
CM_ SG_ 915 ADAS2_St_ELK "ELK功能状态信号";
CM_ SG_ 915 ADAS2_St_ELKIntvMod "ELK仪表提醒信息";
CM_ SG_ 915 ADAS2_SwFb_HMA "HMA开启关闭反馈状态信号";
CM_ SG_ 915 ADAS2_Checksum4 "Checksum = (byte25+byte26+…+byte 31）and 0xFF";
CM_ SG_ 915 ADAS2_RollingCounter4 "Message counter for each message transmittedThe transmitter shall update the value of the Message Counter signal every time a frame is transmitted (even if no other data in the frame has changed value). The counter value shall be updated in the sequence 0, 1, 2, 3......15, 0, 1, 2, 3......15, etc. Upon startup,the initial value of the Message Counter signal shall be 0.";
CM_ SG_ 915 ADAS2_SDASts "智慧躲闪状态信号";
CM_ SG_ 915 ADAS2_DodgeDirection_SDA "躲闪方向信号，用于车机显示";
CM_ SG_ 915 ADAS2_TgtVehicleID_SDA "关键目标ID, 用于在SDA激活状态下，使仪表显示时将目标车高亮显示";
CM_ SG_ 915 ADAS2_ALC_HMIlaneBlock "HWA与仪表交互提示";
CM_ SG_ 915 ADAS2_TSR_SwtFb "TSR开关反馈信号";
CM_ SG_ 915 ADAS2_SwFb_SDA "智慧躲闪开关状态反馈信号";
CM_ SG_ 915 ADAS_FDCA1_SLA_SwitchSts "SLA速度限制提醒开关状态反馈信号";
CM_ SG_ 915 ADAS_FDCA1_SLA_SpdLimOffs "SLA偏差值反馈信号";
CM_ SG_ 915 ADAS2_AEBTxtInfo "Textinfo for Driver which is displayed in Dashboard";
CM_ SG_ 915 ADAS2_FcwTxtInfo "Textinfo for Driver which is displayed in Dashboard";
CM_ SG_ 915 ADAS2_TsrSignMisc "识别出的交通标志";
CM_ SG_ 915 ADAS2_St_SLAMode "SLA Mode";
CM_ SG_ 915 ADAS2_St_SLAFault "SLA Fault";
CM_ SG_ 915 ADAS2_FcwSwtFb "FCW swtich feedback, indicating FCW function is enabled or not. ";
CM_ SG_ 915 ADAS2_AebSwtFb "AEB swtich feedback, indicating AEB function is enabled or not.";
CM_ SG_ 915 ADAS_FDCA1_SLAWarn_SwitchSts "SLA超速报警开关状态反馈信号";
CM_ SG_ 915 ADAS2_AebReq "Request of the AEB/EBA/AEB-VRU deceleration control.";
CM_ SG_ 915 ADAS2_HWASts "HWA状态信号";
CM_ SG_ 915 ADAS2_Checksum5 "Checksum = (byte33+byte34+…+byte 39）and 0xFF";
CM_ SG_ 915 ADAS2_RollingCounter5 "Message counter for each message transmittedThe transmitter shall update the value of the Message Counter signal every time a frame is transmitted (even if no other data in the frame has changed value). The counter value shall be updated in the sequence 0, 1, 2, 3......15, 0, 1, 2, 3......15, etc. Upon startup,the initial value of the Message Counter signal shall be 0.";
CM_ SG_ 915 ADAS2_BvmSetFb "盲区影像开关反馈信号";
CM_ SG_ 915 ADAS2_BvmDispReq "盲区影像功能请求显示";
CM_ SG_ 915 ADAS2_St_left_rear_Camera "左后侧视摄像头故障";
CM_ SG_ 915 ADAS2_St_right_rear_Camera "右后侧视摄像头故障";
CM_ SG_ 915 ADAS2_BvmViewMod "盲区影像视图";
CM_ SG_ 915 ADAS2_St_ELKSenFeedback "ELK灵敏度设置反馈信号";
CM_ SG_ 915 ADC_ADASYSSTS "ADC行车系统故障状态";
CM_ SG_ 915 ADC_enum_PrkgBuzAlrmLvlReq "雷达报警提示音";
CM_ SG_ 915 ADC_SysStartupInPro "System startup in progress系统启动状态标志位";
CM_ SG_ 915 ADC_IMUSentiWarningSts "IMU报警信号";
CM_ SG_ 915 MPC_SOCOffSwtFb "智驾节能模式开关反馈";
CM_ SG_ 547 AdasHmiNeighboringObj1ObjTyp "Provides the type of the neihboring Object no. 1";
CM_ SG_ 547 Obj1Ttc "Time to Collision with target Object";
CM_ SG_ 547 AdasHmiNeighboringObj1XOut "Provides the location of the neighboring Object no.1 as a longitudinal distance from ego center";
CM_ SG_ 547 AdasHmiNeighboringObj1YOut "Provides the location of the neighboring Object no.1 as a lateral distance from ego center";
CM_ SG_ 547 Obj1VX "Relative target object velocity in x-direction";
CM_ SG_ 547 Obj1ObjExistProb "The probability of an object to exist in reality";
CM_ SG_ 547 Obj1Hei "Height of the object";
CM_ SG_ 547 Obj1Width "Width of the object";
CM_ SG_ 547 AdasHmiNeighboringObj2ObjTyp "Provides the type of the neihboring Object no. 2";
CM_ SG_ 547 Obj2ObjExistProb "The probability of an object to exist in reality";
CM_ SG_ 547 AdasHmiNeighboringObj2XOut "Provides the location of the neighboring Object no.1 as a longitudinal distance from ego center";
CM_ SG_ 547 AdasHmiNeighboringObj2YOut "Provides the location of the neighboring Object no.1 as a lateral distance from ego center";
CM_ SG_ 547 Obj2VelX "Relative target object velocity in x-direction";
CM_ SG_ 547 AdasHmiNeighboringObj3ObjTyp "Provides the type of the neihboring Object no. 3";
CM_ SG_ 547 Obj3ObjExistProb "The probability of an object to exist in reality";
CM_ SG_ 547 AdasHmiNeighboringObj3XOut "Provides the location of the neighboring Object no.1 as a longitudinal distance from ego center";
CM_ SG_ 291 Pdcu0x123Chks1 "CRC checksum. DataID and the following 7 bytes are included in CRC checksum calculation. Refer to E2E Spec.（Profile：1A，DataID=0x002C）";
CM_ SG_ 291 Pdcu0x123Cntr1 "Rolling counter. Refer to E2E Spec.";
CM_ SG_ 291 PdcuFrntAxleTrqMinLim "前轴最小可用扭矩";
CM_ SG_ 291 PdcuFrntAxleTrqMinLimVld "前轴最小可用扭矩有效位";
CM_ SG_ 291 PdcuReAxleTrqReq "后轴需求扭矩";
CM_ SG_ 291 PdcuReAxleTrqReqVld "后轴需求扭矩有效位";
CM_ SG_ 291 PdcuReAxleTrqAct "后轴实际扭矩";
CM_ SG_ 291 PdcuReAxleTrqActVld "后轴实际扭矩有效位";
CM_ SG_ 292 Pdcu0x124Chks1 "CRC checksum. DataID and the following 7 bytes are included in CRC checksum calculation. Refer to E2E Spec.（Profile：1A，DataID=0x002D）";
CM_ SG_ 292 Pdcu0x124Cntr1 "Rolling counter. Refer to E2E Spec.";
CM_ SG_ 292 PdcuReAxleTrqMaxLim "后轴最大可用扭矩";
CM_ SG_ 292 PdcuReAxleTrqMaxLimVld "后轴最大可用扭矩有效位";
CM_ SG_ 292 PdcuReAxleTrqMinLim "后轴最小可用扭矩";
CM_ SG_ 292 PdcuReAxleTrqMinLimVld "后轴最小可用扭矩有效位";
CM_ SG_ 292 PdcuWhelTrqMaxLim "轮端最大可用扭矩";
CM_ SG_ 292 PdcuWhelTrqMaxLimVld "轮端最大可用扭矩有效位";
CM_ SG_ 293 Pdcu0x125Chks1 "CRC checksum. DataID and the following 7 bytes are included in CRC checksum calculation. Refer to E2E Spec.（Profile：1A，DataID=0x002E）";
CM_ SG_ 293 Pdcu0x125Cntr1 "Rolling counter. Refer to E2E Spec.";
CM_ SG_ 293 PdcuWhelTrqMinLim "轮端最小可用扭矩";
CM_ SG_ 293 PdcuWhelTrqMinLimVld "轮端最小可用扭矩有效位";
CM_ SG_ 293 PdcuWhelTrqReq "轮端驾驶员需求扭矩";
CM_ SG_ 293 PdcuWhelTrqReqVld "轮端驾驶员需求扭矩有效位";
CM_ SG_ 293 PdcuWhelTrqAct "轮端实际扭矩";
CM_ SG_ 293 PdcuWhelTrqActVld "轮端实际扭矩有效位";
CM_ SG_ 306 WCBS0x132Chks1 "CRC checksum. DataID and the following 7 bytes are included in CRC checksum calculation. Refer to E2E Spec.（Profile：1A，DataID=0x002F）";
CM_ SG_ 306 WCBS0x132Cntr1 "Rolling counter. Refer to E2E Spec.";
CM_ SG_ 306 WCBS_St_FrntAxleTrqIntv "前轴扭矩降扭干预请求";
CM_ SG_ 306 WCBS_N_FrntAxleFastReductionTrqReq "前轴快扭降扭干预";
CM_ SG_ 306 WCBS_St_FrntAxleDTCIntv "前轴升扭矩请求标志位";
CM_ SG_ 306 WCBS_N_FrntAxleDTCTrqReq "前轴升扭矩请求";
CM_ SG_ 306 WCBS_RPAavailable "RPA可用";
CM_ SG_ 306 WCBS_MEBavailable "MEB可用";
CM_ SG_ 306 WCBS_APLCSts "WCBS响应APA状态";
CM_ SG_ 306 WCBS_ActvIndcn_MEB "MEB是否激活";
CM_ SG_ 306 WCBS_APLCFailureSts "WCBS退出APA握手原因";
CM_ SG_ 306 WCBS_BrakeHld "WCBS保压标志位";
CM_ SG_ 306 WCBS_ADASL12AvlSts "WCBS纵向控制可用状态";
CM_ SG_ 306 WCBS_LgtReqModeACtiveSts "WCBS纵向控制请求模式激活状态";
CM_ SG_ 306 WCBS_ADLCFailureSts "WCBS退出握手的原因信号";
CM_ SG_ 306 WCBS_APAavailable "APA可用";
CM_ SG_ 306 WCBS_OMPavailable "WCBS是否支持APA功能信号";
CM_ SG_ 307 WCBS0x133Chks1 "CRC checksum. DataID and the following 7 bytes are included in CRC checksum calculation. Refer to E2E Spec.（Profile：1A，DataID=0x0030）";
CM_ SG_ 307 WCBS0x133Cntr1 "Rolling counter. Refer to E2E Spec.";
CM_ SG_ 307 WCBS_St_ReAxleTrqIntv "后轴扭矩降扭干预请求";
CM_ SG_ 307 WCBS_N_ReAxleFastReductionTrqReq "后轴快扭降扭干预";
CM_ SG_ 307 WCBS_St_ReAxleDTCIntv "后轴升扭矩请求标志位";
CM_ SG_ 307 WCBS_N_ReAxleDTCTrqReq "后轴升扭矩请求";
CM_ SG_ 307 IBS_DrvrTqDes_J6 "驾驶员需求制动力矩";
CM_ SG_ 337 TM2CrtTqVld "后驱动电机当前转矩有效位";
CM_ SG_ 337 TM2CrtRotDir "后驱动电机当前旋转方向";
CM_ SG_ 337 TM2CrtSpd "后驱动电机当前转速";
CM_ SG_ 337 TM2CrtTq "后驱动电机当前转矩";
CM_ SG_ 337 TM2CrtSpdSigVld "后驱动电机当前转速信号有效位";
CM_ SG_ 337 TM2ElockSt "e-Lock执行状态";
CM_ SG_ 337 TM2ELockMod "e-Lock工作状态";
CM_ SG_ 545 TM2MaxTqPeak "后电机最大峰值扭矩";
CM_ SG_ 545 TM2MinTqPeak "后电机最小峰值扭矩";
CM_ SG_ 545 TM2MaxTqCon "后电机最大持续扭矩";
CM_ SG_ 545 TM2MinTqCon "后电机最小持续扭矩";
CM_ SG_ 336 TM1CrtTqVld "前驱动电机当前转矩有效位（默认发0x1）";
CM_ SG_ 336 TM1CrtRotDir "前驱动电机当前旋转方向";
CM_ SG_ 336 TM1CrtSpd "前驱动电机当前转速";
CM_ SG_ 336 TM1CrtTq "前驱动电机当前转矩";
CM_ SG_ 336 TM1CrtSpdSigVld "前驱动电机当前转速信号有效位（发默认值0x1）";
CM_ SG_ 551 TM1MaxTqPeak "前电机最大峰值扭矩";
CM_ SG_ 551 TM1MinTqPeak "前电机最小峰值扭矩";
CM_ SG_ 551 TM1MaxTqCon "前电机最大持续扭矩（按峰值扭矩的一半反馈）";
CM_ SG_ 551 TM1MinTqCon "前电机最小持续扭矩（按峰值扭矩的一半反馈）";
CM_ SG_ 325 Pdcu0x145Chks1 "CRC checksum. DataID and the following 7 bytes are included in CRC checksum calculation. Refer to E2E Spec.（Profile：1A，DataID=0x0036）";
CM_ SG_ 325 Pdcu0x145Cntr1 "Rolling counter. Refer to E2E Spec.";
CM_ SG_ 325 PdcuPTSupportAcc "Indicate the error state of electronic engine control 动力系统故障不支持标志";
CM_ SG_ 325 PdcuPTCancelReq "请求退出ACC功能标志位";
CM_ SG_ 325 PDCU_GearUnderCtrlSts "PDCU状态";
CM_ SG_ 322 EPS2_Checksum "Checksum = (byte1+byte2+…+byte 7）and 0xFF";
CM_ SG_ 322 EPS2_RollingCounter "Information for the ECU to know if messages are lost between the reception of two messages.(E=N) ";
CM_ SG_ 322 EPS2_St_Calibrated "The SAS has been Calibrated or not（预留）";
CM_ SG_ 322 EPS2_LKAorESSFuncResq "Response LKA Or ESS";
CM_ SG_ 322 EPS2_F_SteeringAngle "The valid of steeringangle（预留）";
CM_ SG_ 322 EPS2_InhibitCode "EPS反馈泊车控制或行车控制中断原因（预留）L2.9使用";
CM_ SG_ 322 EPS2_GapFeedback "EPS判断角度请求的帧间差值状态（预留）L2.9使用";
CM_ SG_ 322 EPS2_N_SteeringAngle "The value of steeringangle（预留）";
CM_ SG_ 322 EPS2_N_RotationSpeed "The value of rotationspeed（预留）";
CM_ SG_ 322 EPS2_N_ESSRotationSpeedFB "方向盘转角速度反馈";

BA_DEF_ BO_  "NmMessage" ENUM "No","Yes";
BA_DEF_ BO_  "DiagState" ENUM  "No","Yes";
BA_DEF_ BO_  "DiagResponse" ENUM  "No","Yes";
BA_DEF_ BO_  "GenMsgSendType" ENUM  "cyclic","NoMsgSendType","IfActive","Event","CA","CE";
BA_DEF_ BO_  "GenMsgCycleTime" INT 0 0;
BA_DEF_ SG_  "GenSigSendType" ENUM  "cyclic","OnChange","OnWrite","IfActive","OnChangeWithRepetition","OnWriteWithRepetition","IfActiveWithRepetition","CA","CE","Event";
BA_DEF_ SG_  "GenSigStartValue" INT 0 0;
BA_DEF_ BO_  "GenMsgCycleTimeFast" INT 0 0;
BA_DEF_ BO_  "GenMsgNrOfRepetition" INT 0 0;
BA_DEF_ BO_  "CANFD_BRS" ENUM  "0","1";
BA_DEF_ BO_  "VFrameFormat" ENUM  "StandardCAN","ExtendedCAN","reserved","reserved","reserved","reserved","reserved","reserved","reserved","reserved","reserved","reserved","reserved","reserved","StandardCAN_FD","ExtendedCAN_FD";
BA_DEF_ BO_  "GenMsgILSupport" ENUM  "No","Yes";
BA_DEF_ SG_ "sigDespEng" STRING;
BA_DEF_ SG_ "sigSecLevel" STRING;
BA_DEF_ SG_ "sigConfig" STRING;
BA_DEF_ SG_ "sigExplanation" STRING;

BA_DEF_DEF_  "NmMessage" "No";
BA_DEF_DEF_  "DiagState" "No";
BA_DEF_DEF_  "DiagResponse" "No";
BA_DEF_DEF_  "GenMsgSendType" "cyclic";
BA_DEF_DEF_  "GenMsgCycleTime" 0;
BA_DEF_DEF_  "GenSigSendType" "cyclic";
BA_DEF_DEF_  "GenSigStartValue" 0;
BA_DEF_DEF_  "GenMsgCycleTimeFast" 0;
BA_DEF_DEF_  "GenMsgNrOfRepetition" 0;
BA_DEF_DEF_  "CANFD_BRS" "1";
BA_DEF_DEF_  "VFrameFormat" "StandardCAN";
BA_DEF_DEF_  "GenMsgILSupport" "Yes";
BA_DEF_DEF_ "sigDespEng" "" ;
BA_DEF_DEF_ "sigSecLevel" "QM" ;
BA_DEF_DEF_ "sigConfig" "" ;
BA_DEF_DEF_ "sigExplanation" "" ;
BA_ "GenMsgCycleTime" BO_ 291 10;
BA_ "VFrameFormat" BO_ 291 14;
BA_ "sigSecLevel"  SG_ 291 Pdcu0x123Chks1 "";
BA_ "sigConfig"  SG_ 291 Pdcu0x123Chks1 "B60VS";
BA_ "sigExplanation"  SG_ 291 Pdcu0x123Chks1 "wcbs";
BA_ "sigSecLevel"  SG_ 291 Pdcu0x123Cntr1 "";
BA_ "sigConfig"  SG_ 291 Pdcu0x123Cntr1 "B60VS";
BA_ "sigExplanation"  SG_ 291 Pdcu0x123Cntr1 "wcbs";
BA_ "sigSecLevel"  SG_ 291 PdcuFrntAxleTrqMinLim "";
BA_ "sigConfig"  SG_ 291 PdcuFrntAxleTrqMinLim "B60VS";
BA_ "sigExplanation"  SG_ 291 PdcuFrntAxleTrqMinLim "wcbs";
BA_ "sigSecLevel"  SG_ 291 PdcuFrntAxleTrqMinLimVld "";
BA_ "sigConfig"  SG_ 291 PdcuFrntAxleTrqMinLimVld "B60VS";
BA_ "sigExplanation"  SG_ 291 PdcuFrntAxleTrqMinLimVld "wcbs";
BA_ "sigSecLevel"  SG_ 291 PdcuReAxleTrqReq "";
BA_ "sigConfig"  SG_ 291 PdcuReAxleTrqReq "B60VS";
BA_ "sigExplanation"  SG_ 291 PdcuReAxleTrqReq "wcbs";
BA_ "sigSecLevel"  SG_ 291 PdcuReAxleTrqReqVld "";
BA_ "sigConfig"  SG_ 291 PdcuReAxleTrqReqVld "B60VS";
BA_ "sigExplanation"  SG_ 291 PdcuReAxleTrqReqVld "wcbs";
BA_ "sigSecLevel"  SG_ 291 PdcuReAxleTrqAct "";
BA_ "sigConfig"  SG_ 291 PdcuReAxleTrqAct "B60VS";
BA_ "sigExplanation"  SG_ 291 PdcuReAxleTrqAct "wcbs";
BA_ "sigSecLevel"  SG_ 291 PdcuReAxleTrqActVld "";
BA_ "sigConfig"  SG_ 291 PdcuReAxleTrqActVld "B60VS";
BA_ "sigExplanation"  SG_ 291 PdcuReAxleTrqActVld "wcbs";
BA_ "GenMsgCycleTime" BO_ 292 10;
BA_ "VFrameFormat" BO_ 292 14;
BA_ "sigSecLevel"  SG_ 292 Pdcu0x124Chks1 "";
BA_ "sigConfig"  SG_ 292 Pdcu0x124Chks1 "B60VS";
BA_ "sigExplanation"  SG_ 292 Pdcu0x124Chks1 "wcbs";
BA_ "sigSecLevel"  SG_ 292 Pdcu0x124Cntr1 "";
BA_ "sigConfig"  SG_ 292 Pdcu0x124Cntr1 "B60VS";
BA_ "sigExplanation"  SG_ 292 Pdcu0x124Cntr1 "wcbs";
BA_ "sigSecLevel"  SG_ 292 PdcuReAxleTrqMaxLim "";
BA_ "sigConfig"  SG_ 292 PdcuReAxleTrqMaxLim "B60VS";
BA_ "sigExplanation"  SG_ 292 PdcuReAxleTrqMaxLim "wcbs";
BA_ "sigSecLevel"  SG_ 292 PdcuReAxleTrqMaxLimVld "";
BA_ "sigConfig"  SG_ 292 PdcuReAxleTrqMaxLimVld "B60VS";
BA_ "sigExplanation"  SG_ 292 PdcuReAxleTrqMaxLimVld "wcbs";
BA_ "sigSecLevel"  SG_ 292 PdcuReAxleTrqMinLim "";
BA_ "sigConfig"  SG_ 292 PdcuReAxleTrqMinLim "B60VS";
BA_ "sigExplanation"  SG_ 292 PdcuReAxleTrqMinLim "wcbs";
BA_ "sigSecLevel"  SG_ 292 PdcuReAxleTrqMinLimVld "";
BA_ "sigConfig"  SG_ 292 PdcuReAxleTrqMinLimVld "B60VS";
BA_ "sigExplanation"  SG_ 292 PdcuReAxleTrqMinLimVld "wcbs";
BA_ "sigSecLevel"  SG_ 292 PdcuWhelTrqMaxLim "";
BA_ "sigConfig"  SG_ 292 PdcuWhelTrqMaxLim "B60VS";
BA_ "sigExplanation"  SG_ 292 PdcuWhelTrqMaxLim "wcbs";
BA_ "sigSecLevel"  SG_ 292 PdcuWhelTrqMaxLimVld "";
BA_ "sigConfig"  SG_ 292 PdcuWhelTrqMaxLimVld "B60VS";
BA_ "sigExplanation"  SG_ 292 PdcuWhelTrqMaxLimVld "wcbs";
BA_ "GenMsgCycleTime" BO_ 293 10;
BA_ "VFrameFormat" BO_ 293 14;
BA_ "sigSecLevel"  SG_ 293 Pdcu0x125Chks1 "";
BA_ "sigConfig"  SG_ 293 Pdcu0x125Chks1 "B60VS";
BA_ "sigExplanation"  SG_ 293 Pdcu0x125Chks1 "wcbs";
BA_ "sigSecLevel"  SG_ 293 Pdcu0x125Cntr1 "";
BA_ "sigConfig"  SG_ 293 Pdcu0x125Cntr1 "B60VS";
BA_ "sigExplanation"  SG_ 293 Pdcu0x125Cntr1 "wcbs";
BA_ "sigSecLevel"  SG_ 293 PdcuWhelTrqMinLim "";
BA_ "sigConfig"  SG_ 293 PdcuWhelTrqMinLim "B60VS";
BA_ "sigExplanation"  SG_ 293 PdcuWhelTrqMinLim "wcbs";
BA_ "sigSecLevel"  SG_ 293 PdcuWhelTrqMinLimVld "";
BA_ "sigConfig"  SG_ 293 PdcuWhelTrqMinLimVld "B60VS";
BA_ "sigExplanation"  SG_ 293 PdcuWhelTrqMinLimVld "wcbs";
BA_ "sigSecLevel"  SG_ 293 PdcuWhelTrqReq "";
BA_ "sigConfig"  SG_ 293 PdcuWhelTrqReq "B60VS";
BA_ "sigExplanation"  SG_ 293 PdcuWhelTrqReq "wcbs";
BA_ "sigSecLevel"  SG_ 293 PdcuWhelTrqReqVld "";
BA_ "sigConfig"  SG_ 293 PdcuWhelTrqReqVld "B60VS";
BA_ "sigExplanation"  SG_ 293 PdcuWhelTrqReqVld "wcbs";
BA_ "sigSecLevel"  SG_ 293 PdcuWhelTrqAct "";
BA_ "sigConfig"  SG_ 293 PdcuWhelTrqAct "B60VS";
BA_ "sigExplanation"  SG_ 293 PdcuWhelTrqAct "wcbs";
BA_ "sigSecLevel"  SG_ 293 PdcuWhelTrqActVld "";
BA_ "sigConfig"  SG_ 293 PdcuWhelTrqActVld "B60VS";
BA_ "sigExplanation"  SG_ 293 PdcuWhelTrqActVld "wcbs";
BA_ "GenMsgCycleTime" BO_ 306 10;
BA_ "VFrameFormat" BO_ 306 14;
BA_ "sigSecLevel"  SG_ 306 WCBS0x132Chks1 "";
BA_ "sigConfig"  SG_ 306 WCBS0x132Chks1 "B60VS";
BA_ "sigExplanation"  SG_ 306 WCBS0x132Chks1 "pdcu";
BA_ "sigSecLevel"  SG_ 306 WCBS0x132Cntr1 "";
BA_ "sigConfig"  SG_ 306 WCBS0x132Cntr1 "B60VS";
BA_ "sigExplanation"  SG_ 306 WCBS0x132Cntr1 "pdcu";
BA_ "sigDespEng"  SG_ 306 WCBS_St_FrntAxleTrqIntv "TCS扭矩接口";
BA_ "sigSecLevel"  SG_ 306 WCBS_St_FrntAxleTrqIntv "";
BA_ "sigConfig"  SG_ 306 WCBS_St_FrntAxleTrqIntv "B60VS";
BA_ "sigExplanation"  SG_ 306 WCBS_St_FrntAxleTrqIntv "pdcu";
BA_ "sigDespEng"  SG_ 306 WCBS_N_FrntAxleFastReductionTrqReq "TCS扭矩接口";
BA_ "sigSecLevel"  SG_ 306 WCBS_N_FrntAxleFastReductionTrqReq "";
BA_ "sigConfig"  SG_ 306 WCBS_N_FrntAxleFastReductionTrqReq "B60VS";
BA_ "sigExplanation"  SG_ 306 WCBS_N_FrntAxleFastReductionTrqReq "pdcu,FDCA";
BA_ "sigDespEng"  SG_ 306 WCBS_St_FrntAxleDTCIntv "DTC扭矩接口";
BA_ "sigSecLevel"  SG_ 306 WCBS_St_FrntAxleDTCIntv "";
BA_ "sigConfig"  SG_ 306 WCBS_St_FrntAxleDTCIntv "B60VS";
BA_ "sigExplanation"  SG_ 306 WCBS_St_FrntAxleDTCIntv "pdcu";
BA_ "sigDespEng"  SG_ 306 WCBS_N_FrntAxleDTCTrqReq "DTC扭矩接口";
BA_ "sigSecLevel"  SG_ 306 WCBS_N_FrntAxleDTCTrqReq "";
BA_ "sigConfig"  SG_ 306 WCBS_N_FrntAxleDTCTrqReq "B60VS";
BA_ "sigExplanation"  SG_ 306 WCBS_N_FrntAxleDTCTrqReq "pdcu,FDCA";
BA_ "sigDespEng"  SG_ 306 WCBS_RPAavailable "WCBS是否支持RPA功能信号";
BA_ "sigSecLevel"  SG_ 306 WCBS_RPAavailable "";
BA_ "sigConfig"  SG_ 306 WCBS_RPAavailable "B81";
BA_ "sigDespEng"  SG_ 306 WCBS_MEBavailable "WCBS是否支持MEB功能信号";
BA_ "sigSecLevel"  SG_ 306 WCBS_MEBavailable "";
BA_ "sigConfig"  SG_ 306 WCBS_MEBavailable "B81";
BA_ "sigDespEng"  SG_ 306 WCBS_APLCSts "WCBS响应APA状态位";
BA_ "sigSecLevel"  SG_ 306 WCBS_APLCSts "";
BA_ "sigConfig"  SG_ 306 WCBS_APLCSts "B81";
BA_ "sigDespEng"  SG_ 306 WCBS_ActvIndcn_MEB "WCBS响应MEB状态位";
BA_ "sigSecLevel"  SG_ 306 WCBS_ActvIndcn_MEB "";
BA_ "sigConfig"  SG_ 306 WCBS_ActvIndcn_MEB "B81";
BA_ "sigDespEng"  SG_ 306 WCBS_APLCFailureSts "WCBS退出APA握手原因状态";
BA_ "sigSecLevel"  SG_ 306 WCBS_APLCFailureSts "";
BA_ "sigConfig"  SG_ 306 WCBS_APLCFailureSts "B81";
BA_ "sigDespEng"  SG_ 306 WCBS_BrakeHld "WCBS保压标志位";
BA_ "sigSecLevel"  SG_ 306 WCBS_BrakeHld "";
BA_ "sigConfig"  SG_ 306 WCBS_BrakeHld "B81";
BA_ "sigDespEng"  SG_ 306 WCBS_ADASL12AvlSts "WCBS是否支持ADAS功能信号";
BA_ "sigSecLevel"  SG_ 306 WCBS_ADASL12AvlSts "";
BA_ "sigConfig"  SG_ 306 WCBS_ADASL12AvlSts "B81";
BA_ "sigDespEng"  SG_ 306 WCBS_LgtReqModeACtiveSts "WCBS纵向控制请求模式激活状态";
BA_ "sigSecLevel"  SG_ 306 WCBS_LgtReqModeACtiveSts "";
BA_ "sigConfig"  SG_ 306 WCBS_LgtReqModeACtiveSts "B81";
BA_ "sigDespEng"  SG_ 306 WCBS_ADLCFailureSts "WCBS退出握手的原因信号";
BA_ "sigSecLevel"  SG_ 306 WCBS_ADLCFailureSts "";
BA_ "sigConfig"  SG_ 306 WCBS_ADLCFailureSts "B81";
BA_ "sigDespEng"  SG_ 306 WCBS_APAavailable "WCBS是否支持APA功能信号";
BA_ "sigSecLevel"  SG_ 306 WCBS_APAavailable "";
BA_ "sigConfig"  SG_ 306 WCBS_APAavailable "B81";
BA_ "sigSecLevel"  SG_ 306 WCBS_OMPavailable "";
BA_ "sigConfig"  SG_ 306 WCBS_OMPavailable "B81";
BA_ "GenMsgCycleTime" BO_ 307 10;
BA_ "VFrameFormat" BO_ 307 14;
BA_ "sigSecLevel"  SG_ 307 WCBS0x133Chks1 "";
BA_ "sigConfig"  SG_ 307 WCBS0x133Chks1 "B60VS";
BA_ "sigExplanation"  SG_ 307 WCBS0x133Chks1 "pdcu";
BA_ "sigSecLevel"  SG_ 307 WCBS0x133Cntr1 "";
BA_ "sigConfig"  SG_ 307 WCBS0x133Cntr1 "B60VS";
BA_ "sigExplanation"  SG_ 307 WCBS0x133Cntr1 "pdcu";
BA_ "sigDespEng"  SG_ 307 WCBS_St_ReAxleTrqIntv "TCS扭矩接口";
BA_ "sigSecLevel"  SG_ 307 WCBS_St_ReAxleTrqIntv "";
BA_ "sigConfig"  SG_ 307 WCBS_St_ReAxleTrqIntv "B60VS";
BA_ "sigExplanation"  SG_ 307 WCBS_St_ReAxleTrqIntv "pdcu";
BA_ "sigDespEng"  SG_ 307 WCBS_N_ReAxleFastReductionTrqReq "TCS扭矩接口";
BA_ "sigSecLevel"  SG_ 307 WCBS_N_ReAxleFastReductionTrqReq "";
BA_ "sigConfig"  SG_ 307 WCBS_N_ReAxleFastReductionTrqReq "B60VS";
BA_ "sigExplanation"  SG_ 307 WCBS_N_ReAxleFastReductionTrqReq "pdcu,FDCA";
BA_ "sigDespEng"  SG_ 307 WCBS_St_ReAxleDTCIntv "DTC扭矩接口";
BA_ "sigSecLevel"  SG_ 307 WCBS_St_ReAxleDTCIntv "";
BA_ "sigConfig"  SG_ 307 WCBS_St_ReAxleDTCIntv "B60VS";
BA_ "sigExplanation"  SG_ 307 WCBS_St_ReAxleDTCIntv "pdcu";
BA_ "sigDespEng"  SG_ 307 WCBS_N_ReAxleDTCTrqReq "DTC扭矩接口";
BA_ "sigSecLevel"  SG_ 307 WCBS_N_ReAxleDTCTrqReq "";
BA_ "sigConfig"  SG_ 307 WCBS_N_ReAxleDTCTrqReq "B60VS";
BA_ "sigExplanation"  SG_ 307 WCBS_N_ReAxleDTCTrqReq "pdcu,FDCA";
BA_ "GenSigStartValue" SG_ 307 IBS_DrvrTqDes_J6 65535;
BA_ "sigSecLevel"  SG_ 307 IBS_DrvrTqDes_J6 "";
BA_ "sigConfig"  SG_ 307 IBS_DrvrTqDes_J6 "B81";
BA_ "GenMsgCycleTime" BO_ 337 10;
BA_ "VFrameFormat" BO_ 337 14;
BA_ "sigSecLevel"  SG_ 337 TM2CrtTqVld "";
BA_ "sigExplanation"  SG_ 337 TM2CrtTqVld "FDCA";
BA_ "sigSecLevel"  SG_ 337 TM2CrtRotDir "";
BA_ "sigExplanation"  SG_ 337 TM2CrtRotDir "FDCA";
BA_ "GenSigStartValue" SG_ 337 TM2CrtSpd 32768;
BA_ "sigSecLevel"  SG_ 337 TM2CrtSpd "";
BA_ "sigExplanation"  SG_ 337 TM2CrtSpd "FDCA";
BA_ "GenSigStartValue" SG_ 337 TM2CrtTq 32768;
BA_ "sigSecLevel"  SG_ 337 TM2CrtTq "";
BA_ "sigExplanation"  SG_ 337 TM2CrtTq "FDCA";
BA_ "sigSecLevel"  SG_ 337 TM2CrtSpdSigVld "";
BA_ "sigExplanation"  SG_ 337 TM2CrtSpdSigVld "FDCA";
BA_ "sigSecLevel"  SG_ 337 TM2ElockSt "";
BA_ "sigExplanation"  SG_ 337 TM2ElockSt "FDCA";
BA_ "sigSecLevel"  SG_ 337 TM2ELockMod "";
BA_ "sigExplanation"  SG_ 337 TM2ELockMod "FDCA";
BA_ "GenMsgCycleTime" BO_ 545 20;
BA_ "VFrameFormat" BO_ 545 14;
BA_ "GenSigStartValue" SG_ 545 TM2MaxTqPeak 32768;
BA_ "sigSecLevel"  SG_ 545 TM2MaxTqPeak "";
BA_ "sigExplanation"  SG_ 545 TM2MaxTqPeak "FDCA";
BA_ "GenSigStartValue" SG_ 545 TM2MinTqPeak 32768;
BA_ "sigSecLevel"  SG_ 545 TM2MinTqPeak "";
BA_ "sigExplanation"  SG_ 545 TM2MinTqPeak "FDCA";
BA_ "GenSigStartValue" SG_ 545 TM2MaxTqCon 32768;
BA_ "sigSecLevel"  SG_ 545 TM2MaxTqCon "";
BA_ "sigExplanation"  SG_ 545 TM2MaxTqCon "FDCA";
BA_ "GenSigStartValue" SG_ 545 TM2MinTqCon 32768;
BA_ "sigSecLevel"  SG_ 545 TM2MinTqCon "";
BA_ "sigExplanation"  SG_ 545 TM2MinTqCon "FDCA";
BA_ "GenMsgCycleTime" BO_ 336 10;
BA_ "VFrameFormat" BO_ 336 14;
BA_ "sigSecLevel"  SG_ 336 TM1CrtTqVld "";
BA_ "sigExplanation"  SG_ 336 TM1CrtTqVld "FDCA";
BA_ "sigSecLevel"  SG_ 336 TM1CrtRotDir "";
BA_ "sigExplanation"  SG_ 336 TM1CrtRotDir "FDCA";
BA_ "GenSigStartValue" SG_ 336 TM1CrtSpd 32768;
BA_ "sigSecLevel"  SG_ 336 TM1CrtSpd "";
BA_ "sigExplanation"  SG_ 336 TM1CrtSpd "FDCA";
BA_ "GenSigStartValue" SG_ 336 TM1CrtTq 32768;
BA_ "sigSecLevel"  SG_ 336 TM1CrtTq "";
BA_ "sigExplanation"  SG_ 336 TM1CrtTq "FDCA";
BA_ "sigSecLevel"  SG_ 336 TM1CrtSpdSigVld "";
BA_ "sigExplanation"  SG_ 336 TM1CrtSpdSigVld "FDCA";
BA_ "GenMsgCycleTime" BO_ 551 20;
BA_ "VFrameFormat" BO_ 551 14;
BA_ "GenSigStartValue" SG_ 551 TM1MaxTqPeak 32768;
BA_ "sigSecLevel"  SG_ 551 TM1MaxTqPeak "";
BA_ "sigExplanation"  SG_ 551 TM1MaxTqPeak "FDCA";
BA_ "GenSigStartValue" SG_ 551 TM1MinTqPeak 32768;
BA_ "sigSecLevel"  SG_ 551 TM1MinTqPeak "";
BA_ "sigExplanation"  SG_ 551 TM1MinTqPeak "FDCA";
BA_ "GenSigStartValue" SG_ 551 TM1MaxTqCon 32768;
BA_ "sigSecLevel"  SG_ 551 TM1MaxTqCon "";
BA_ "sigExplanation"  SG_ 551 TM1MaxTqCon "FDCA";
BA_ "GenSigStartValue" SG_ 551 TM1MinTqCon 32768;
BA_ "sigSecLevel"  SG_ 551 TM1MinTqCon "";
BA_ "sigExplanation"  SG_ 551 TM1MinTqCon "FDCA";
BA_ "GenMsgCycleTime" BO_ 325 100;
BA_ "VFrameFormat" BO_ 325 14;
BA_ "sigSecLevel"  SG_ 325 Pdcu0x145Chks1 "";
BA_ "sigExplanation"  SG_ 325 Pdcu0x145Chks1 "fdca，apa";
BA_ "sigSecLevel"  SG_ 325 Pdcu0x145Cntr1 "";
BA_ "sigExplanation"  SG_ 325 Pdcu0x145Cntr1 "fdca，apa";
BA_ "sigSecLevel"  SG_ 325 PdcuPTSupportAcc "";
BA_ "sigExplanation"  SG_ 325 PdcuPTSupportAcc "fdca";
BA_ "sigSecLevel"  SG_ 325 PdcuPTCancelReq "";
BA_ "sigExplanation"  SG_ 325 PdcuPTCancelReq "fdca";
BA_ "sigSecLevel"  SG_ 325 PDCU_GearUnderCtrlSts "";
BA_ "sigExplanation"  SG_ 325 PDCU_GearUnderCtrlSts "apa";
BA_ "GenMsgCycleTime" BO_ 583 20;
BA_ "VFrameFormat" BO_ 583 14;
BA_ "sigDespEng"  SG_ 583 ADAS1_LKAorESSFuncReq "L2.5";
BA_ "sigSecLevel"  SG_ 583 ADAS1_LKAorESSFuncReq "";
BA_ "sigExplanation"  SG_ 583 ADAS1_LKAorESSFuncReq "eps";
BA_ "sigDespEng"  SG_ 583 ADAS1_TouchDetectionStatus "L2.5";
BA_ "sigSecLevel"  SG_ 583 ADAS1_TouchDetectionStatus "";
BA_ "sigDespEng"  SG_ 583 ADAS1_FaultStatus "L2.5";
BA_ "sigSecLevel"  SG_ 583 ADAS1_FaultStatus "";
BA_ "sigDespEng"  SG_ 583 ADAS1_VLCBSShutdownReq "L2.5";
BA_ "sigSecLevel"  SG_ 583 ADAS1_VLCBSShutdownReq "";
BA_ "sigDespEng"  SG_ 583 ADAS1_VLCECGPOvrd "L2.5";
BA_ "sigSecLevel"  SG_ 583 ADAS1_VLCECGPOvrd "";
BA_ "sigDespEng"  SG_ 583 ADAS1_EPBAppReq "L2.5";
BA_ "sigSecLevel"  SG_ 583 ADAS1_EPBAppReq "";
BA_ "sigDespEng"  SG_ 583 ADAS1_F_SteerAlgReq "ADAS SteerAlg Req Status";
BA_ "sigSecLevel"  SG_ 583 ADAS1_F_SteerAlgReq "";
BA_ "sigConfig"  SG_ 583 ADAS1_F_SteerAlgReq "tsp";
BA_ "sigExplanation"  SG_ 583 ADAS1_F_SteerAlgReq "eps";
BA_ "sigDespEng"  SG_ 583 ADAS1_N_SteerAlgReq "ADAS SteerAlg Req";
BA_ "sigSecLevel"  SG_ 583 ADAS1_N_SteerAlgReq "";
BA_ "sigConfig"  SG_ 583 ADAS1_N_SteerAlgReq "tsp";
BA_ "sigExplanation"  SG_ 583 ADAS1_N_SteerAlgReq "eps";
BA_ "sigDespEng"  SG_ 583 ADAS1_N_ESSRotationSpeed "L2.5";
BA_ "sigSecLevel"  SG_ 583 ADAS1_N_ESSRotationSpeed "";
BA_ "sigExplanation"  SG_ 583 ADAS1_N_ESSRotationSpeed "eps";
BA_ "sigDespEng"  SG_ 583 ADAS1_RollingCounter "L2.5";
BA_ "sigSecLevel"  SG_ 583 ADAS1_RollingCounter "";
BA_ "sigExplanation"  SG_ 583 ADAS1_RollingCounter "eps";
BA_ "sigDespEng"  SG_ 583 ADAS1_Checksum "L2.5";
BA_ "sigSecLevel"  SG_ 583 ADAS1_Checksum "";
BA_ "sigExplanation"  SG_ 583 ADAS1_Checksum "eps";
BA_ "GenMsgCycleTime" BO_ 322 10;
BA_ "VFrameFormat" BO_ 322 14;
BA_ "sigDespEng"  SG_ 322 EPS2_Checksum "L2.5";
BA_ "sigSecLevel"  SG_ 322 EPS2_Checksum "";
BA_ "sigExplanation"  SG_ 322 EPS2_Checksum "fdca";
BA_ "sigDespEng"  SG_ 322 EPS2_RollingCounter "L2.5";
BA_ "sigSecLevel"  SG_ 322 EPS2_RollingCounter "";
BA_ "sigExplanation"  SG_ 322 EPS2_RollingCounter "fdca";
BA_ "sigDespEng"  SG_ 322 EPS2_St_Calibrated "L2.5与180重复";
BA_ "sigSecLevel"  SG_ 322 EPS2_St_Calibrated "";
BA_ "sigDespEng"  SG_ 322 EPS2_LKAorESSFuncResq "L2.5新增，需要开发";
BA_ "sigSecLevel"  SG_ 322 EPS2_LKAorESSFuncResq "";
BA_ "sigExplanation"  SG_ 322 EPS2_LKAorESSFuncResq "fdca";
BA_ "sigDespEng"  SG_ 322 EPS2_F_SteeringAngle "L2.5";
BA_ "sigSecLevel"  SG_ 322 EPS2_F_SteeringAngle "";
BA_ "sigDespEng"  SG_ 322 EPS2_InhibitCode "L2.9";
BA_ "sigSecLevel"  SG_ 322 EPS2_InhibitCode "";
BA_ "sigDespEng"  SG_ 322 EPS2_GapFeedback "L2.9";
BA_ "sigSecLevel"  SG_ 322 EPS2_GapFeedback "";
BA_ "GenSigStartValue" SG_ 322 EPS2_N_SteeringAngle 7800;
BA_ "sigDespEng"  SG_ 322 EPS2_N_SteeringAngle "L2.5与180重复";
BA_ "sigSecLevel"  SG_ 322 EPS2_N_SteeringAngle "";
BA_ "sigDespEng"  SG_ 322 EPS2_N_RotationSpeed "L2.5与180重复，但范围调整";
BA_ "sigSecLevel"  SG_ 322 EPS2_N_RotationSpeed "";
BA_ "sigDespEng"  SG_ 322 EPS2_N_ESSRotationSpeedFB "L2.5新增，需要开发";
BA_ "sigSecLevel"  SG_ 322 EPS2_N_ESSRotationSpeedFB "";
BA_ "sigExplanation"  SG_ 322 EPS2_N_ESSRotationSpeedFB "fdca";
BA_ "GenMsgCycleTime" BO_ 1508 100;
BA_ "VFrameFormat" BO_ 1508 14;
BA_ "sigSecLevel"  SG_ 1508 FDCA1_St_SLASpdlimit "";
BA_ "sigExplanation"  SG_ 1508 FDCA1_St_SLASpdlimit "hud,cdcipc";
BA_ "sigDespEng"  SG_ 1508 FDCA1_St_SLAWarning "较B60V变动";
BA_ "sigSecLevel"  SG_ 1508 FDCA1_St_SLAWarning "";
BA_ "sigExplanation"  SG_ 1508 FDCA1_St_SLAWarning "hud,cdcipc,alc";
BA_ "sigDespEng"  SG_ 1508 ADAS_FDCA1_St_SLASpeedLimitUnit "变化原来是FDCA1_St_FCWMode，改了位置";
BA_ "sigSecLevel"  SG_ 1508 ADAS_FDCA1_St_SLASpeedLimitUnit "";
BA_ "sigExplanation"  SG_ 1508 ADAS_FDCA1_St_SLASpeedLimitUnit "cdc";
BA_ "sigSecLevel"  SG_ 1508 FDCA1_St_LDWMode "";
BA_ "sigExplanation"  SG_ 1508 FDCA1_St_LDWMode "hud,cdcipc,cdcehc,tbox";
BA_ "sigDespEng"  SG_ 1508 ADAS_FDCA1_ESS_SwitchSts "较B60V变动";
BA_ "sigSecLevel"  SG_ 1508 ADAS_FDCA1_ESS_SwitchSts "";
BA_ "sigExplanation"  SG_ 1508 ADAS_FDCA1_ESS_SwitchSts "cdc";
BA_ "sigDespEng"  SG_ 1508 FDCA1_St_AEBMode "删除";
BA_ "sigSecLevel"  SG_ 1508 FDCA1_St_AEBMode "";
BA_ "sigExplanation"  SG_ 1508 FDCA1_St_AEBMode "sdm,hud,ipc,ehc,apa，tbox";
BA_ "sigSecLevel"  SG_ 1508 FDCA1_St_LKA "";
BA_ "sigExplanation"  SG_ 1508 FDCA1_St_LKA "hud,cdcipc,cdcehc,tbox";
BA_ "sigSecLevel"  SG_ 1508 FDCA1_St_TSRMode "";
BA_ "sigExplanation"  SG_ 1508 FDCA1_St_TSRMode "cdcipc";
BA_ "sigDespEng"  SG_ 1508 FDCA1_W_Handsoff "较B60V变动";
BA_ "sigSecLevel"  SG_ 1508 FDCA1_W_Handsoff "";
BA_ "sigExplanation"  SG_ 1508 FDCA1_W_Handsoff "cdcipc,hud,tbox";
BA_ "sigDespEng"  SG_ 1508 ADAS_FDCA1_AdasSafestopAppdReq "较B60V变动";
BA_ "sigSecLevel"  SG_ 1508 ADAS_FDCA1_AdasSafestopAppdReq "";
BA_ "sigExplanation"  SG_ 1508 ADAS_FDCA1_AdasSafestopAppdReq "cdcipc（tbd）";
BA_ "sigDespEng"  SG_ 1508 ADAS_FDCA1_Sts_ESS "改值";
BA_ "sigSecLevel"  SG_ 1508 ADAS_FDCA1_Sts_ESS "";
BA_ "sigExplanation"  SG_ 1508 ADAS_FDCA1_Sts_ESS "cdcipc";
BA_ "sigDespEng"  SG_ 1508 ADAS_FDCA1_St_FCWMode "更换位置，长度，增加coding值";
BA_ "sigSecLevel"  SG_ 1508 ADAS_FDCA1_St_FCWMode "";
BA_ "sigExplanation"  SG_ 1508 ADAS_FDCA1_St_FCWMode "hud,cdcipc,cdcehc,tbox";
BA_ "sigDespEng"  SG_ 1508 ADAS_FDCA1_St_TSRwarning "变化原来是ADAS_FDCA1_LKA_SwitchSts";
BA_ "sigSecLevel"  SG_ 1508 ADAS_FDCA1_St_TSRwarning "";
BA_ "sigExplanation"  SG_ 1508 ADAS_FDCA1_St_TSRwarning "cdc";
BA_ "sigDespEng"  SG_ 1508 ADAS_FDCA1_LDW_meter_Warning "较B60V变动";
BA_ "sigSecLevel"  SG_ 1508 ADAS_FDCA1_LDW_meter_Warning "";
BA_ "sigExplanation"  SG_ 1508 ADAS_FDCA1_LDW_meter_Warning "cdcipc";
BA_ "sigDespEng"  SG_ 1508 ADC_PrivacyAgreementSts "查询整车隐私协议开关";
BA_ "sigSecLevel"  SG_ 1508 ADC_PrivacyAgreementSts "";
BA_ "sigConfig"  SG_ 1508 ADC_PrivacyAgreementSts "B81";
BA_ "sigExplanation"  SG_ 1508 ADC_PrivacyAgreementSts "ICC";
BA_ "sigDespEng"  SG_ 1508 FDCA1_St_VehicleMode "待定";
BA_ "sigSecLevel"  SG_ 1508 FDCA1_St_VehicleMode "";
BA_ "sigConfig"  SG_ 1508 FDCA1_St_VehicleMode "车辆模式,TSP";
BA_ "sigExplanation"  SG_ 1508 FDCA1_St_VehicleMode "tbox";
BA_ "sigDespEng"  SG_ 1508 ADAS_FDCA1_ESSTraj "增加";
BA_ "sigSecLevel"  SG_ 1508 ADAS_FDCA1_ESSTraj "";
BA_ "sigExplanation"  SG_ 1508 ADAS_FDCA1_ESSTraj "cdc";
BA_ "sigSecLevel"  SG_ 1508 FDCA1_RollingCounter "";
BA_ "sigSecLevel"  SG_ 1508 FDCA1_CheckSum "";
BA_ "GenMsgCycleTime" BO_ 1351 100;
BA_ "VFrameFormat" BO_ 1351 14;
BA_ "sigSecLevel"  SG_ 1351 FDCA2_N_vSetDisp "";
BA_ "sigExplanation"  SG_ 1351 FDCA2_N_vSetDisp "hud,cdcipc,tbox";
BA_ "sigSecLevel"  SG_ 1351 FDCA2_St_dxTarObj "";
BA_ "sigExplanation"  SG_ 1351 FDCA2_St_dxTarObj "hud,cdcipc,tbox";
BA_ "sigSecLevel"  SG_ 1351 FDCA2_St_TauGapSet "";
BA_ "sigExplanation"  SG_ 1351 FDCA2_St_TauGapSet "cdcipc";
BA_ "sigSecLevel"  SG_ 1351 FDCA2_St_LateralTakeoverReq "";
BA_ "sigExplanation"  SG_ 1351 FDCA2_St_LateralTakeoverReq "hud,cdcipc";
BA_ "sigSecLevel"  SG_ 1351 FDCA2_St_HighbeamReq "";
BA_ "sigExplanation"  SG_ 1351 FDCA2_St_HighbeamReq "bdcbcm";
BA_ "sigDespEng"  SG_ 1351 FDCA2_St_HMA "较B60V变动";
BA_ "sigSecLevel"  SG_ 1351 FDCA2_St_HMA "";
BA_ "sigExplanation"  SG_ 1351 FDCA2_St_HMA "cdcpc,tbox";
BA_ "sigDespEng"  SG_ 1351 FDCA2_St_ACCMode_HMI "较B60V变动";
BA_ "sigSecLevel"  SG_ 1351 FDCA2_St_ACCMode_HMI "";
BA_ "sigExplanation"  SG_ 1351 FDCA2_St_ACCMode_HMI "sdm,hud,cdcipc,tbox";
BA_ "sigDespEng"  SG_ 1351 ADAS_SafeStopHazardLlightReq "变化原FDCA2_W_FCWpreWarning";
BA_ "sigSecLevel"  SG_ 1351 ADAS_SafeStopHazardLlightReq "";
BA_ "sigExplanation"  SG_ 1351 ADAS_SafeStopHazardLlightReq "bdc";
BA_ "sigSecLevel"  SG_ 1351 FDCA2_St_TakeOverReq "";
BA_ "sigExplanation"  SG_ 1351 FDCA2_St_TakeOverReq "hud,cdcipc,tbox";
BA_ "sigSecLevel"  SG_ 1351 FDCA2_St_LeftVisualization "";
BA_ "sigExplanation"  SG_ 1351 FDCA2_St_LeftVisualization "hud,cdcipc,tbox";
BA_ "sigDespEng"  SG_ 1351 ADAS_FDCA2_St_TauGapWinRequest "较B60V变动";
BA_ "sigSecLevel"  SG_ 1351 ADAS_FDCA2_St_TauGapWinRequest "";
BA_ "sigExplanation"  SG_ 1351 ADAS_FDCA2_St_TauGapWinRequest "cdcipc";
BA_ "sigDespEng"  SG_ 1351 ADAS_NOA_Right_turn_light_Req "较B60V变动";
BA_ "sigSecLevel"  SG_ 1351 ADAS_NOA_Right_turn_light_Req "";
BA_ "sigConfig"  SG_ 1351 ADAS_NOA_Right_turn_light_Req "L2.9";
BA_ "sigExplanation"  SG_ 1351 ADAS_NOA_Right_turn_light_Req "CDC，bdc";
BA_ "sigDespEng"  SG_ 1351 ADAS_NOA_left_turn_light_Req "较B60V变动";
BA_ "sigSecLevel"  SG_ 1351 ADAS_NOA_left_turn_light_Req "";
BA_ "sigConfig"  SG_ 1351 ADAS_NOA_left_turn_light_Req "L2.9";
BA_ "sigExplanation"  SG_ 1351 ADAS_NOA_left_turn_light_Req "CDC,bdc";
BA_ "sigSecLevel"  SG_ 1351 FDCA2_St_RightVisualization "";
BA_ "sigExplanation"  SG_ 1351 FDCA2_St_RightVisualization "hud,cdcipc,tbox";
BA_ "sigDespEng"  SG_ 1351 FDCA2_St_TJA_ICA_mode "较B60V变动";
BA_ "sigSecLevel"  SG_ 1351 FDCA2_St_TJA_ICA_mode "";
BA_ "sigExplanation"  SG_ 1351 FDCA2_St_TJA_ICA_mode "hud,cdcipc,tbox";
BA_ "sigDespEng"  SG_ 1351 ADAS_FDCA2_AccObjDetd "较B60V变动";
BA_ "sigSecLevel"  SG_ 1351 ADAS_FDCA2_AccObjDetd "";
BA_ "sigExplanation"  SG_ 1351 ADAS_FDCA2_AccObjDetd "cdcIPC";
BA_ "sigDespEng"  SG_ 1351 FDCA2_AccTxtInfo "较B60V变动，与B41一致";
BA_ "sigSecLevel"  SG_ 1351 FDCA2_AccTxtInfo "";
BA_ "sigExplanation"  SG_ 1351 FDCA2_AccTxtInfo "cdcipc";
BA_ "sigSecLevel"  SG_ 1351 FDCA2_St_Camera "";
BA_ "sigExplanation"  SG_ 1351 FDCA2_St_Camera "cdcipc,tbox";
BA_ "sigSecLevel"  SG_ 1351 FDCA2_W_Distance "";
BA_ "sigExplanation"  SG_ 1351 FDCA2_W_Distance "hud,cdcipc";
BA_ "sigSecLevel"  SG_ 1351 FDCA2_St_FCWSensitivity "";
BA_ "sigExplanation"  SG_ 1351 FDCA2_St_FCWSensitivity "cdcehc";
BA_ "sigDespEng"  SG_ 1351 ADAS_SafeStopDoorUnlockReq "41新增2.9";
BA_ "sigSecLevel"  SG_ 1351 ADAS_SafeStopDoorUnlockReq "";
BA_ "sigExplanation"  SG_ 1351 ADAS_SafeStopDoorUnlockReq "bdc";
BA_ "sigDespEng"  SG_ 1351 FDCA2_W_FCWpreWarning "位置调整，增加长度";
BA_ "sigSecLevel"  SG_ 1351 FDCA2_W_FCWpreWarning "";
BA_ "sigExplanation"  SG_ 1351 FDCA2_W_FCWpreWarning "cdc";
BA_ "sigDespEng"  SG_ 1351 ADAS_St_LowbeamReq "41新增2.9";
BA_ "sigSecLevel"  SG_ 1351 ADAS_St_LowbeamReq "";
BA_ "sigExplanation"  SG_ 1351 ADAS_St_LowbeamReq "bdc";
BA_ "sigSecLevel"  SG_ 1351 FDCA2_St_TSR "";
BA_ "sigExplanation"  SG_ 1351 FDCA2_St_TSR "cdcehc";
BA_ "sigSecLevel"  SG_ 1351 FDCA2_RollingCounter "";
BA_ "sigExplanation"  SG_ 1351 FDCA2_RollingCounter "cdc,bdc";
BA_ "sigSecLevel"  SG_ 1351 FDCA2_Checksum "";
BA_ "sigExplanation"  SG_ 1351 FDCA2_Checksum "cdc,bdc";
BA_ "GenMsgCycleTime" BO_ 915 100;
BA_ "VFrameFormat" BO_ 915 14;
BA_ "sigSecLevel"  SG_ 915 ADAS2_Checksum1 "";
BA_ "sigSecLevel"  SG_ 915 ADAS2_RollingCounter1 "";
BA_ "sigSecLevel"  SG_ 915 ADAS2_Radar_TextInfo "";
BA_ "sigExplanation"  SG_ 915 ADAS2_Radar_TextInfo "IPC";
BA_ "sigSecLevel"  SG_ 915 ADAS2_AccfobjDrvAwayinfo "";
BA_ "sigExplanation"  SG_ 915 ADAS2_AccfobjDrvAwayinfo "IPC";
BA_ "sigSecLevel"  SG_ 915 ADAS2_TLA_WarnSign "";
BA_ "sigSecLevel"  SG_ 915 ADAS2_St_MRR "";
BA_ "sigConfig"  SG_ 915 ADAS2_St_MRR "L2.9";
BA_ "sigExplanation"  SG_ 915 ADAS2_St_MRR "IPC";
BA_ "sigSecLevel"  SG_ 915 ADAS2_Accdrivemode "";
BA_ "sigExplanation"  SG_ 915 ADAS2_Accdrivemode "EHC,IPC";
BA_ "sigSecLevel"  SG_ 915 ADAS2_ASLSts "";
BA_ "sigExplanation"  SG_ 915 ADAS2_ASLSts "IPC";
BA_ "sigSecLevel"  SG_ 915 ADAS2_ASLSpdlim "";
BA_ "sigExplanation"  SG_ 915 ADAS2_ASLSpdlim "IPC";
BA_ "GenSigStartValue" SG_ 915 ADAS2_St_TJA_ICA_Textinfo 7;
BA_ "sigSecLevel"  SG_ 915 ADAS2_St_TJA_ICA_Textinfo "";
BA_ "sigExplanation"  SG_ 915 ADAS2_St_TJA_ICA_Textinfo "IPC";
BA_ "sigSecLevel"  SG_ 915 ADAS2_ASLSwtfb "";
BA_ "sigExplanation"  SG_ 915 ADAS2_ASLSwtfb "EHC,IPC";
BA_ "sigSecLevel"  SG_ 915 ADAS2_ALCSts "";
BA_ "sigExplanation"  SG_ 915 ADAS2_ALCSts "IPC";
BA_ "sigSecLevel"  SG_ 915 ADAS2_Checksum2 "";
BA_ "sigSecLevel"  SG_ 915 ADAS1_RollingCounter2 "";
BA_ "sigSecLevel"  SG_ 915 ADAS2_NOASts "";
BA_ "sigConfig"  SG_ 915 ADAS2_NOASts "L2.9";
BA_ "sigSecLevel"  SG_ 915 ADAS2_HwaAlcSwtFb "";
BA_ "sigExplanation"  SG_ 915 ADAS2_HwaAlcSwtFb "EHC,IPC";
BA_ "sigSecLevel"  SG_ 915 ADAS2_TJA_ICA__EnbSwtFb "";
BA_ "sigExplanation"  SG_ 915 ADAS2_TJA_ICA__EnbSwtFb "EHC,IPC";
BA_ "sigSecLevel"  SG_ 915 ADAS2_NOA_ALC_TYPE_SwtFb "";
BA_ "sigConfig"  SG_ 915 ADAS2_NOA_ALC_TYPE_SwtFb "L2.9";
BA_ "sigExplanation"  SG_ 915 ADAS2_NOA_ALC_TYPE_SwtFb "EHC";
BA_ "sigSecLevel"  SG_ 915 ADAS2_NOA_ALCRequest_confirm_Fb "";
BA_ "sigConfig"  SG_ 915 ADAS2_NOA_ALCRequest_confirm_Fb "L2.9";
BA_ "sigExplanation"  SG_ 915 ADAS2_NOA_ALCRequest_confirm_Fb "EHC,IPC";
BA_ "sigSecLevel"  SG_ 915 ADAS2_NOA_ALCSoundnotification_SwtFb "";
BA_ "sigConfig"  SG_ 915 ADAS2_NOA_ALCSoundnotification_SwtFb "L2.9";
BA_ "sigExplanation"  SG_ 915 ADAS2_NOA_ALCSoundnotification_SwtFb "EHC,IPC";
BA_ "sigSecLevel"  SG_ 915 ADAS2_IntelligentCornering_EnbSw_SwtFb "";
BA_ "sigConfig"  SG_ 915 ADAS2_IntelligentCornering_EnbSw_SwtFb "L2.9";
BA_ "sigExplanation"  SG_ 915 ADAS2_IntelligentCornering_EnbSw_SwtFb "EHC,IPC";
BA_ "sigSecLevel"  SG_ 915 ADAS2_NOASwtFb "";
BA_ "sigConfig"  SG_ 915 ADAS2_NOASwtFb "L2.9";
BA_ "sigSecLevel"  SG_ 915 ADAS2_DrvrHandsoffRmn "";
BA_ "sigConfig"  SG_ 915 ADAS2_DrvrHandsoffRmn "L2.9";
BA_ "sigSecLevel"  SG_ 915 ADAS2_DriverHandsoff "";
BA_ "sigConfig"  SG_ 915 ADAS2_DriverHandsoff "L2.9";
BA_ "sigSecLevel"  SG_ 915 ADAS2_ICATJATakeoverReq "";
BA_ "sigConfig"  SG_ 915 ADAS2_ICATJATakeoverReq "tsp";
BA_ "sigExplanation"  SG_ 915 ADAS2_ICATJATakeoverReq "IPC";
BA_ "sigSecLevel"  SG_ 915 ADAS2_ALCHmiEgoLaneChg "";
BA_ "sigExplanation"  SG_ 915 ADAS2_ALCHmiEgoLaneChg "IPC";
BA_ "sigSecLevel"  SG_ 915 ADAS2_ALCActvToTakeover "";
BA_ "sigExplanation"  SG_ 915 ADAS2_ALCActvToTakeover "IPC";
BA_ "sigSecLevel"  SG_ 915 ADAS2_NLP_FctActvRmm "";
BA_ "sigConfig"  SG_ 915 ADAS2_NLP_FctActvRmm "L2.9";
BA_ "sigSecLevel"  SG_ 915 ADAS2_NLPTakeoverReq "";
BA_ "sigConfig"  SG_ 915 ADAS2_NLPTakeoverReq "L2.9";
BA_ "sigSecLevel"  SG_ 915 ADAS2_TJAICA_LINE_SOURCE "";
BA_ "sigExplanation"  SG_ 915 ADAS2_TJAICA_LINE_SOURCE "IPC";
BA_ "sigSecLevel"  SG_ 915 ADAS2_ALCNotAvlReas "";
BA_ "sigExplanation"  SG_ 915 ADAS2_ALCNotAvlReas "IPC";
BA_ "sigSecLevel"  SG_ 915 ADAS2_NOAHmiDispdTxtMsgId "";
BA_ "sigConfig"  SG_ 915 ADAS2_NOAHmiDispdTxtMsgId "L2.9";
BA_ "sigSecLevel"  SG_ 915 ADAS2_TLA_SwitchSts "";
BA_ "sigSecLevel"  SG_ 915 ADAS2_Checksum3 "";
BA_ "sigSecLevel"  SG_ 915 ADAS2_RollingCounter3 "";
BA_ "sigSecLevel"  SG_ 915 ADAS2_NOAODDTyp "";
BA_ "sigConfig"  SG_ 915 ADAS2_NOAODDTyp "L2.9";
BA_ "sigSecLevel"  SG_ 915 ADAS2_NOADstToODD "";
BA_ "sigConfig"  SG_ 915 ADAS2_NOADstToODD "L2.9";
BA_ "sigSecLevel"  SG_ 915 ADAS2_TextinfoForIntelligentCornering "";
BA_ "sigConfig"  SG_ 915 ADAS2_TextinfoForIntelligentCornering "L2.9";
BA_ "sigSecLevel"  SG_ 915 ADAS2_NotAvlReas "";
BA_ "sigConfig"  SG_ 915 ADAS2_NotAvlReas "L2.9";
BA_ "sigExplanation"  SG_ 915 ADAS2_NotAvlReas "IPC";
BA_ "sigSecLevel"  SG_ 915 ADAS2_HmiAudioNotifId "";
BA_ "sigExplanation"  SG_ 915 ADAS2_HmiAudioNotifId "IPC";
BA_ "sigSecLevel"  SG_ 915 ADAS2_ADASQuitReas "";
BA_ "sigExplanation"  SG_ 915 ADAS2_ADASQuitReas "IPC";
BA_ "sigSecLevel"  SG_ 915 ADAS2_Set_TJA_ICA_ACC "";
BA_ "sigExplanation"  SG_ 915 ADAS2_Set_TJA_ICA_ACC "EHC,IPC";
BA_ "sigSecLevel"  SG_ 915 ADAS2_St_left_front_Camera "";
BA_ "sigConfig"  SG_ 915 ADAS2_St_left_front_Camera "L2.9";
BA_ "sigSecLevel"  SG_ 915 ADAS2_St_right_front_Camera "";
BA_ "sigConfig"  SG_ 915 ADAS2_St_right_front_Camera "L2.9";
BA_ "sigSecLevel"  SG_ 915 ADAS2_St_LDWLKALCKSenFb "";
BA_ "sigSecLevel"  SG_ 915 ADAS2_Sw_LDWLKALCKFb "";
BA_ "sigSecLevel"  SG_ 915 ADAS2_St_LDWLKALCKSetFb "";
BA_ "sigSecLevel"  SG_ 915 ADAS2_SwFb_ELK "";
BA_ "sigSecLevel"  SG_ 915 ADAS2_St_LDWLKALCK "";
BA_ "sigSecLevel"  SG_ 915 ADAS2_St_ELK "";
BA_ "sigSecLevel"  SG_ 915 ADAS2_St_ELKIntvMod "";
BA_ "sigSecLevel"  SG_ 915 ADAS2_SwFb_HMA "";
BA_ "sigSecLevel"  SG_ 915 ADAS2_Checksum4 "";
BA_ "sigSecLevel"  SG_ 915 ADAS2_RollingCounter4 "";
BA_ "sigSecLevel"  SG_ 915 ADAS2_SDASts "";
BA_ "sigSecLevel"  SG_ 915 ADAS2_DodgeDirection_SDA "";
BA_ "sigSecLevel"  SG_ 915 ADAS2_TgtVehicleID_SDA "";
BA_ "sigSecLevel"  SG_ 915 ADAS2_ALC_HMIlaneBlock "";
BA_ "sigSecLevel"  SG_ 915 ADAS2_TSR_SwtFb "";
BA_ "sigSecLevel"  SG_ 915 ADAS2_SwFb_SDA "";
BA_ "sigSecLevel"  SG_ 915 ADAS_FDCA1_SLA_SwitchSts "";
BA_ "sigSecLevel"  SG_ 915 ADAS_FDCA1_SLA_SpdLimOffs "";
BA_ "sigSecLevel"  SG_ 915 ADAS2_AEBTxtInfo "";
BA_ "sigSecLevel"  SG_ 915 ADAS2_FcwTxtInfo "";
BA_ "sigSecLevel"  SG_ 915 ADAS2_TsrSignMisc "";
BA_ "sigSecLevel"  SG_ 915 ADAS2_St_SLAMode "";
BA_ "sigSecLevel"  SG_ 915 ADAS2_St_SLAFault "";
BA_ "sigSecLevel"  SG_ 915 ADAS2_FcwSwtFb "";
BA_ "sigSecLevel"  SG_ 915 ADAS2_AebSwtFb "";
BA_ "sigSecLevel"  SG_ 915 ADAS_FDCA1_SLAWarn_SwitchSts "";
BA_ "sigSecLevel"  SG_ 915 ADAS2_AebReq "";
BA_ "sigSecLevel"  SG_ 915 ADAS2_HWASts "";
BA_ "sigSecLevel"  SG_ 915 ADAS2_Checksum5 "";
BA_ "sigSecLevel"  SG_ 915 ADAS2_RollingCounter5 "";
BA_ "sigSecLevel"  SG_ 915 ADAS2_BvmSetFb "";
BA_ "sigSecLevel"  SG_ 915 ADAS2_BvmDispReq "";
BA_ "sigSecLevel"  SG_ 915 ADAS2_St_left_rear_Camera "";
BA_ "sigConfig"  SG_ 915 ADAS2_St_left_rear_Camera "L2.9";
BA_ "sigSecLevel"  SG_ 915 ADAS2_St_right_rear_Camera "";
BA_ "sigConfig"  SG_ 915 ADAS2_St_right_rear_Camera "L2.9";
BA_ "sigSecLevel"  SG_ 915 ADAS2_BvmViewMod "";
BA_ "sigSecLevel"  SG_ 915 ADAS2_St_ELKSenFeedback "";
BA_ "sigExplanation"  SG_ 915 ADAS2_St_ELKSenFeedback "cdc";
BA_ "sigDespEng"  SG_ 915 ADC_ADASYSSTS "没有故障发0x0,有故障发0x1";
BA_ "sigSecLevel"  SG_ 915 ADC_ADASYSSTS "";
BA_ "sigConfig"  SG_ 915 ADC_ADASYSSTS "B81";
BA_ "sigDespEng"  SG_ 915 ADC_enum_PrkgBuzAlrmLvlReq "全速启动时雷达报警音";
BA_ "sigSecLevel"  SG_ 915 ADC_enum_PrkgBuzAlrmLvlReq "";
BA_ "sigConfig"  SG_ 915 ADC_enum_PrkgBuzAlrmLvlReq "B81";
BA_ "sigDespEng"  SG_ 915 ADC_SysStartupInPro "表示智驾模块处于启动中";
BA_ "sigSecLevel"  SG_ 915 ADC_SysStartupInPro "";
BA_ "sigConfig"  SG_ 915 ADC_SysStartupInPro "B81";
BA_ "sigDespEng"  SG_ 915 ADC_IMUSentiWarningSts "IMU哨兵警示状态,0x1或0x2时进入视频录制并保存状态";
BA_ "sigSecLevel"  SG_ 915 ADC_IMUSentiWarningSts "";
BA_ "sigConfig"  SG_ 915 ADC_IMUSentiWarningSts "B81";
BA_ "sigSecLevel"  SG_ 915 MPC_SOCOffSwtFb "";
BA_ "sigConfig"  SG_ 915 MPC_SOCOffSwtFb "B81";
BA_ "GenMsgCycleTime" BO_ 547 100;
BA_ "VFrameFormat" BO_ 547 14;
BA_ "sigSecLevel"  SG_ 547 AdasHmiNeighboringObj1ObjTyp "";
BA_ "sigExplanation"  SG_ 547 AdasHmiNeighboringObj1ObjTyp "CDCIPC";
BA_ "sigSecLevel"  SG_ 547 Obj1Ttc "";
BA_ "sigExplanation"  SG_ 547 Obj1Ttc "CDCIPC";
BA_ "sigSecLevel"  SG_ 547 AdasHmiNeighboringObj1XOut "";
BA_ "sigConfig"  SG_ 547 AdasHmiNeighboringObj1XOut "预测";
BA_ "sigExplanation"  SG_ 547 AdasHmiNeighboringObj1XOut "CDCIPC，pdcu";
BA_ "sigSecLevel"  SG_ 547 AdasHmiNeighboringObj1YOut "";
BA_ "sigExplanation"  SG_ 547 AdasHmiNeighboringObj1YOut "CDCIPC";
BA_ "sigSecLevel"  SG_ 547 Obj1VX "";
BA_ "sigConfig"  SG_ 547 Obj1VX "预测";
BA_ "sigExplanation"  SG_ 547 Obj1VX "CDCIPC，pdcu";
BA_ "sigSecLevel"  SG_ 547 Obj1ObjExistProb "";
BA_ "sigExplanation"  SG_ 547 Obj1ObjExistProb "CDCIPC";
BA_ "sigSecLevel"  SG_ 547 Obj1Hei "";
BA_ "sigExplanation"  SG_ 547 Obj1Hei "CDCIPC";
BA_ "sigSecLevel"  SG_ 547 Obj1Width "";
BA_ "sigExplanation"  SG_ 547 Obj1Width "CDCIPC";
BA_ "sigSecLevel"  SG_ 547 AdasHmiNeighboringObj2ObjTyp "";
BA_ "sigExplanation"  SG_ 547 AdasHmiNeighboringObj2ObjTyp "CDCIPC";
BA_ "sigSecLevel"  SG_ 547 Obj2ObjExistProb "";
BA_ "sigExplanation"  SG_ 547 Obj2ObjExistProb "CDCIPC";
BA_ "sigSecLevel"  SG_ 547 AdasHmiNeighboringObj2XOut "";
BA_ "sigExplanation"  SG_ 547 AdasHmiNeighboringObj2XOut "CDCIPC";
BA_ "sigSecLevel"  SG_ 547 AdasHmiNeighboringObj2YOut "";
BA_ "sigExplanation"  SG_ 547 AdasHmiNeighboringObj2YOut "CDCIPC";
BA_ "sigSecLevel"  SG_ 547 Obj2VelX "";
BA_ "sigExplanation"  SG_ 547 Obj2VelX "CDCIPC";
BA_ "sigSecLevel"  SG_ 547 AdasHmiNeighboringObj3ObjTyp "";
BA_ "sigExplanation"  SG_ 547 AdasHmiNeighboringObj3ObjTyp "CDCIPC";
BA_ "sigSecLevel"  SG_ 547 Obj3ObjExistProb "";
BA_ "sigExplanation"  SG_ 547 Obj3ObjExistProb "CDCIPC";
BA_ "sigSecLevel"  SG_ 547 AdasHmiNeighboringObj3XOut "";
BA_ "sigExplanation"  SG_ 547 AdasHmiNeighboringObj3XOut "CDCIPC";
VAL_ 583 ADAS1_LKAorESSFuncReq 3 "Reserved" 2 "ESSFunctionRequest" 1 "LKAFunctionRequest" 0 "NoRequest" ;
VAL_ 583 ADAS1_TouchDetectionStatus 3 "Invalid" 2 "Active" 1 "Inactive" 0 "DefaultStatus" ;
VAL_ 583 ADAS1_FaultStatus 1 "Failure" 0 "Normal" ;
VAL_ 583 ADAS1_VLCBSShutdownReq 3 "NoRequest" 2 "ImmediateOFF" 1 "FastOFF" 0 "SoftOFF" ;
VAL_ 583 ADAS1_VLCECGPOvrd 1 "DriverOverride" 0 "NoOverride" ;
VAL_ 583 ADAS1_EPBAppReq 1 "Request" 0 "No request" ;
VAL_ 583 ADAS1_F_SteerAlgReq 3 "reserved" 2 "ldsAngleActive" 1 "ldsAngleReady" 0 "ldsAngleInhibited" ;
VAL_ 583 ADAS1_N_SteerAlgReq 65535 "Invalid" ;
VAL_ 583 ADAS1_N_ESSRotationSpeed 4095 "Invalid" ;
VAL_ 1508 FDCA1_St_SLASpdlimit 255 "Reserved" 254 "Reserved" 253 "Reserved" 252 "Reserved" 251 "Reserved" 250 "Reserved" 249 "Reserved" 248 "Reserved" 247 "Reserved" 246 "Reserved" 245 "Reserved" 244 "Reserved" 243 "Reserved" 242 "Reserved" 241 "Reserved" 240 "Reserved" 239 "Reserved" 238 "Reserved" 237 "Reserved" 236 "Reserved" 235 "Reserved" 234 "Reserved" 233 "Reserved" 232 "Reserved" 231 "Reserved" 230 "Reserved" 229 "Reserved" 228 "Reserved" 227 "Reserved" 226 "Reserved" 225 "Reserved" 224 "Reserved" 223 "Reserved" 222 "Reserved" 221 "Reserved" 220 "Reserved" 219 "Reserved" 218 "Reserved" 217 "Reserved" 216 "Reserved" 215 "Reserved" 214 "Reserved" 213 "Reserved" 212 "Reserved" 211 "Reserved" 210 "Reserved" 209 "Reserved" 208 "Reserved" 207 "Reserved" 206 "Reserved" 205 "Reserved" 204 "Reserved" 203 "Reserved" 202 "Reserved" 201 "Reserved" 200 "Reserved" 199 "Reserved" 198 "Reserved" 197 "Reserved" 196 "Reserved" 195 "Reserved" 194 "Reserved" 193 "Reserved" 192 "Reserved" 191 "Reserved" 190 "Reserved" 189 "Reserved" 188 "Reserved" 187 "Reserved" 186 "Reserved" 185 "Reserved" 184 "Reserved" 183 "Reserved" 182 "Reserved" 181 "Reserved" 180 "Reserved" 179 "Reserved" 178 "Reserved" 177 "Reserved" 176 "Reserved" 175 "Reserved" 174 "Reserved" 173 "Reserved" 172 "Reserved" 171 "Reserved" 170 "Reserved" 169 "Reserved" 168 "Reserved" 167 "Reserved" 166 "Reserved" 165 "Reserved" 164 "Reserved" 163 "Reserved" 162 "Reserved" 161 "Reserved" 160 "Reserved" 159 "Reserved" 158 "Reserved" 157 "Reserved" 156 "Reserved" 155 "Reserved" 154 "Reserved" 153 "Reserved" 152 "Reserved" 151 "Reserved" 150 "Reserved" 149 "Reserved" 148 "Reserved" 147 "Reserved" 146 "Reserved" 145 "Reserved" 144 "Reserved" 143 "Reserved" 142 "Reserved" 141 "Reserved" 140 "Reserved" 139 "Reserved" 138 "Reserved" 137 "Reserved" 136 "Reserved" 135 "Reserved" 134 "Reserved" 133 "Reserved" 132 "Reserved" 131 "Reserved" 130 "Reserved" 129 "Reserved" 128 "Reserved" 127 "Reserved" 126 "Reserved" 125 "Reserved" 124 "Reserved" 123 "Reserved" 122 "Reserved" 121 "Reserved" 120 "Reserved" 119 "Reserved" 118 "Reserved" 117 "Reserved" 116 "Reserved" 115 "Reserved" 114 "Reserved" 113 "Reserved" 112 "Reserved" 111 "Reserved" 110 "Reserved" 109 "Reserved" 108 "Reserved" 107 "Reserved" 106 "Reserved" 105 "Reserved" 104 "Reserved" 103 "Reserved" 102 "Reserved" 101 "Reserved" 100 "Reserved" 99 "Reserved" 98 "Reserved" 97 "Reserved" 96 "Reserved" 95 "Reserved" 94 "Reserved" 93 "Reserved" 92 "Reserved" 91 "Reserved" 90 "Reserved" 89 "Reserved" 88 "Reserved" 87 "Reserved" 86 "Reserved" 85 "Reserved" 84 "Reserved" 83 "Reserved" 82 "Reserved" 81 "Reserved" 80 "Reserved" 79 "Reserved" 78 "Reserved" 77 "Reserved" 76 "Reserved" 75 "Reserved" 74 "Reserved" 73 "Reserved" 72 "Reserved" 71 "Reserved" 70 "Reserved" 69 "Reserved" 68 "Reserved" 67 "Reserved" 66 "Reserved" 65 "Reserved" 64 "Reserved" 63 "Reserved" 62 "Reserved" 61 "Reserved" 60 "Reserved" 59 "Reserved" 58 "Reserved" 57 "Reserved" 56 "Reserved" 55 "Reserved" 54 "Reserved" 53 "Reserved" 52 "Reserved" 51 "Reserved" 50 "Reserved" 49 "Reserved" 48 "Reserved" 47 "Reserved" 46 "Reserved" 45 "Reserved" 44 "Reserved" 43 "Reserved" 42 "Reserved" 41 "Reserved" 40 "Reserved" 39 "Reserved" 38 "Reserved" 37 "Reserved" 36 "Reserved" 35 "Reserved" 34 "Reserved" 33 "Reserved" 32 "Reserved" 31 "Reserved" 30 "Reserved" 29 "Reserved" 28 "Reserved" 27 "SPL 130" 26 "SPL 125" 25 "SPL 120" 24 "SPL 115" 23 "SPL 110" 22 "SPL 105" 21 "SPL 100" 20 "SPL 95" 19 "SPL 90" 18 "SPL 85" 17 "SPL 80" 16 "SPL 75" 15 "SPL 70" 14 "SPL 65" 13 "SPL 60" 12 "SPL 55" 11 "SPL 50" 10 "SPL 45" 9 "SPL 40" 8 "SPL 35" 7 "SPL 30" 6 "SPL 25" 5 "SPL 20" 4 "SPL 15" 3 "SPL10" 2 "SPL 5" 1 "SPL Cancelled" 0 "No Display" ;
VAL_ 1508 FDCA1_St_SLAWarning 3 "Reserved" 2 "Reserved" 1 "Warning display" 0 "No warning" ;
VAL_ 1508 ADAS_FDCA1_St_SLASpeedLimitUnit 3 "Reserved" 2 "miles/h" 1 "km/h" 0 "Unknown" ;
VAL_ 1508 FDCA1_St_LDWMode 7 "Reserved" 6 "Reserved" 5 "Reserved" 4 "Reserved" 3 "Fault" 2 "Active" 1 "Standby" 0 "Off" ;
VAL_ 1508 ADAS_FDCA1_ESS_SwitchSts 1 "OFF" 0 "ON" ;
VAL_ 1508 FDCA1_St_AEBMode 3 "Failure mode" 2 "Active mode" 1 "On mode" 0 "OFF mode" ;
VAL_ 1508 FDCA1_St_LKA 7 "Reserved" 6 "Reserved" 5 "Reserved" 4 "Reserved" 3 "Fault" 2 "Active" 1 "Standby" 0 "Off" ;
VAL_ 1508 FDCA1_St_TSRMode 7 "Reserved" 6 "Reserved" 5 "Reserved" 4 "Defect" 3 "Navigation only mode" 2 "Vision mode" 1 "Fusion mode" 0 "Off" ;
VAL_ 1508 FDCA1_W_Handsoff 3 "Level3(optical&sound2)function exit" 2 "Level2(optical&sound)" 1 "Level1(optical)" 0 "No Request" ;
VAL_ 1508 ADAS_FDCA1_AdasSafestopAppdReq 3 "Rerserved" 2 "Rerserved" 1 "Request" 0 "No request" ;
VAL_ 1508 ADAS_FDCA1_Sts_ESS 15 "Reserved" 14 "Reserved" 13 "Reserved" 12 "Reserved" 11 "Reserved" 10 "Reserved" 9 "Reserved" 8 "Reserved" 7 "Reserved" 6 "Reserved" 5 "Failure" 4 "Override" 3 "Active" 2 "Standby" 1 "Inhibit" 0 "Off" ;
VAL_ 1508 ADAS_FDCA1_St_FCWMode 4 "Failure mode" 3 "standby" 2 "Active mode" 1 "On mode" 0 "OFF mode" ;
VAL_ 1508 ADAS_FDCA1_St_TSRwarning 1 "Fault" 0 "No Fault" ;
VAL_ 1508 ADAS_FDCA1_LDW_meter_Warning 2 "level2 warning" 1 "level1 warning" 0 "no warning" ;
VAL_ 1508 ADC_PrivacyAgreementSts 3 "reserve" 2 "同意" 1 "拒绝" 0 "default" ;
VAL_ 1508 FDCA1_St_VehicleMode 7 "Rerserved" 6 "Gallery Mode" 5 "Test Mode（预留）" 4 "Crash Mode（预留）" 3 "Transport Mode" 2 "Factory Mode（default）" 1 "Normal Mode" 0 "initialization" ;
VAL_ 1508 ADAS_FDCA1_ESSTraj 3 "Reserved" 2 "Right" 1 "Left" 0 "Neither" ;
VAL_ 1351 FDCA2_N_vSetDisp 255 "Invalid" ;
VAL_ 1351 FDCA2_St_dxTarObj 7 "Reserved" 6 "Reserved" 5 "Reserved" 4 "Distance_4" 3 "Distance_3" 2 "Distance_2" 1 "Distance_1" 0 "No Display" ;
VAL_ 1351 FDCA2_St_TauGapSet 7 "Reserved" 6 "Reserved" 5 "Reserved" 4 "TauGap_4" 3 "TauGap_3" 2 "TauGap_2" 1 "TauGap_1" 0 "No Display" ;
VAL_ 1351 FDCA2_St_LateralTakeoverReq 1 "Active" 0 "Inactive" ;
VAL_ 1351 FDCA2_St_HighbeamReq 1 "Request" 0 "No Request" ;
VAL_ 1351 FDCA2_St_HMA 7 "Reserved" 6 "Reserved" 5 "Reserved" 4 "Reserved" 3 "Fault" 2 "Active" 1 "Standby" 0 "Off" ;
VAL_ 1351 FDCA2_St_ACCMode_HMI 15 "reserved" 14 "reserved" 13 "reserved" 12 "reserved" 11 "reserved" 10 "reserved" 9 "reserved" 8 "Failure mode" 7 "Stand-wait" 6 "Stand-active" 5 "Override" 4 "Brake-Only mode" 3 "Active-Control mode" 2 "Stand-By mode" 1 "Passive mode" 0 "OFF mode" ;
VAL_ 1351 ADAS_SafeStopHazardLlightReq 1 "Request" 0 "No request" ;
VAL_ 1351 FDCA2_St_TakeOverReq 1 "valid TakeOver request" 0 "no TakeOver request" ;
VAL_ 1351 FDCA2_St_LeftVisualization 3 "Warning" 2 "Intervention" 1 "Line tracking" 0 "No display" ;
VAL_ 1351 ADAS_FDCA2_St_TauGapWinRequest 1 "Request" 0 "No Request" ;
VAL_ 1351 ADAS_NOA_Right_turn_light_Req 1 "Request" 0 "No request" ;
VAL_ 1351 ADAS_NOA_left_turn_light_Req 1 "Request" 0 "No request" ;
VAL_ 1351 FDCA2_St_RightVisualization 3 "Warning" 2 "Intervention" 1 "Line tracking" 0 "No display" ;
VAL_ 1351 FDCA2_St_TJA_ICA_mode 6 "Failure" 5 "Exit" 4 "Pause" 3 "Active" 2 "standby" 1 "Initialization" 0 "Off" ;
VAL_ 1351 ADAS_FDCA2_AccObjDetd 1 "target object detected" 0 "No object" ;
VAL_ 1351 FDCA2_AccTxtInfo 15 "INF8: Check trunk 请关闭行李箱盖" 14 "INF7: Check hood请关闭发动机舱盖" 13 "INF6: Check engine请启动发动机" 12 "INF5:Check ESP swtich请打开ESP" 11 "INF4:Check handbrake请松手刹" 10 "INF3:Check door请关车门" 9 "INF2:check gear请挂前进挡" 8 "INF1:check belt请系安全带" 7 "Radar is covered" 6 "check Tire pressure" 5 "check APA" 4 "Camera blocked" 3 "Camera over-temperature protection" 2 "ACC is cancelled" 1 "unable to active ACC" 0 "No display" ;
VAL_ 1351 FDCA2_St_Camera 3 "Cmaera not calibrated" 2 "Camera blocked" 1 "Camera failure" 0 "Camera normal" ;
VAL_ 1351 FDCA2_W_Distance 1 "warning" 0 "no warning" ;
VAL_ 1351 FDCA2_St_FCWSensitivity 3 "HighSensitivity" 2 "MiddleSensitivity" 1 "LowSensitivity" 0 "Not Selected" ;
VAL_ 1351 ADAS_SafeStopDoorUnlockReq 1 "Request" 0 "No request" ;
VAL_ 1351 FDCA2_W_FCWpreWarning 3 "FCW forward warning" 2 "FCW VRU warning" 1 "Latent warning" 0 "no waning" ;
VAL_ 1351 ADAS_St_LowbeamReq 1 "Request" 0 "No Request" ;
VAL_ 1351 FDCA2_St_TSR 3 "Reseved" 2 "Display and Sound" 1 "Only Display" 0 "Not Selected" ;
VAL_ 915 ADAS2_Radar_TextInfo 15 "unable to active JA  无法激活，故障状态" 14 "JA  is biocked         遮挡指示" 13 "JA  is wanrning       报警指示" 12 "JA is switched off  开关关闭指示" 11 "JA is switched on  开关打开指示" 10 "unable to active FCTB  无法激活，故障状态" 9 "FCTB  is biocked         遮挡指示" 8 "FCTB  is wanrning       报警指示" 7 "FCTB is switched off  开关关闭指示" 6 "FCTB is switched on  开关打开指示" 5 "unable to active FCTA  无法激活，故障状态" 4 "FCTA is biocked         遮挡指示" 3 "FCTA is wanrning       报警指示" 2 "FCTA is switched off  开关关闭指示" 1 "FCTA is switched on  开关打开指示" 0 "No display  没有操作，原始状态" ;
VAL_ 915 ADAS2_AccfobjDrvAwayinfo 1 "Active" 0 "Inactive" ;
VAL_ 915 ADAS2_TLA_WarnSign 3 "Red" 2 "Yellow" 1 "Green" 0 "No Display" ;
VAL_ 915 ADAS2_St_MRR 3 "reserved" 2 "blindness" 1 "failure" 0 "normal" ;
VAL_ 915 ADAS2_Accdrivemode 3 "Reserved" 2 "eco" 1 "sport" 0 "normal" ;
VAL_ 915 ADAS2_ASLSts 7 "Reserved" 6 "ASL request" 5 "Failure" 4 "Override" 3 "Active" 2 "Stanby" 1 "Passive" 0 "OFF" ;
VAL_ 915 ADAS2_ASLSpdlim 31 "150" 30 "145" 29 "140" 28 "135" 27 "130" 26 "125" 25 "120" 24 "115" 23 "110" 22 "105" 21 "100" 20 "95" 19 "90" 18 "85" 17 "80" 16 "75" 15 "70" 14 "65" 13 "60" 12 "55" 11 "50" 10 "45" 9 "40" 8 "35" 7 "30" 6 "25" 5 "20" 4 "15" 3 "10" 2 "5" 1 "Cancelled" 0 "No display" ;
VAL_ 915 ADAS2_St_TJA_ICA_Textinfo 15 "Reserved" 14 "Reserved" 13 "Reserved" 12 "Reserved" 11 "Reserved" 10 "Invalid" 9 "IACCswitch off" 8 "Driveroverrides steering；" 7 "speed exceed；" 6 "EPS not available；" 5 "Longitudinal control not available；" 4 "Lane boundary not available；" 3 "Unable to activate TJA\ICA；" 2 "TJA\ICA deactivate；" 1 "TJA\ICA active；" 0 "no display；" ;
VAL_ 915 ADAS2_ASLSwtfb 1 "ON" 0 "OFF" ;
VAL_ 915 ADAS2_ALCSts 6 "Invalid" 5 "Failure" 4 "Take Over Request" 3 "Active Request" 2 "Active Control" 1 "Passive" 0 "Init" ;
VAL_ 915 ADAS2_NOASts 15 "reserved" 14 "reserved" 13 "reserved" 12 "reserved" 11 "Permanent failure" 10 "Temporary failure" 9 "safestop" 8 "TOR" 7 "override" 6 "active" 5 "available" 4 "SW off" 3 "passive" 2 "standy" 1 "init" 0 "OFF" ;
VAL_ 915 ADAS2_HwaAlcSwtFb 1 "ON" 0 "OFF" ;
VAL_ 915 ADAS2_TJA_ICA__EnbSwtFb 1 "ON" 0 "OFF" ;
VAL_ 915 ADAS2_NOA_ALC_TYPE_SwtFb 2 "sport" 1 "normal" 0 "comfort" ;
VAL_ 915 ADAS2_NOA_ALCRequest_confirm_Fb 1 "need" 0 "not need" ;
VAL_ 915 ADAS2_NOA_ALCSoundnotification_SwtFb 1 "sound" 0 "no sound" ;
VAL_ 915 ADAS2_IntelligentCornering_EnbSw_SwtFb 1 "ON" 0 "OFF" ;
VAL_ 915 ADAS2_NOASwtFb 1 "ON" 0 "OFF" ;
VAL_ 915 ADAS2_DrvrHandsoffRmn 255 "Reserved" ;
VAL_ 915 ADAS2_DriverHandsoff 1 "hands off" 0 "hands on" ;
VAL_ 915 ADAS2_ICATJATakeoverReq 7 "Reserved" 6 "Reserved" 5 "Standstill TOR" 4 "safestop（stage4）" 3 "no take over exit(optical&sound2)" 2 "take over Request(optical&sound)" 1 "hands off warning(optical)" 0 "inactive" ;
VAL_ 915 ADAS2_ALCHmiEgoLaneChg 15 "User Cancelled" 14 "take over" 13 "return to the ego lane from right side" 12 "return to the ego lane from left side" 11 "lane change to the right failed" 10 "lane change to the left failed" 9 "Left and Right Lane Change Available" 8 "Right Lane Change Avaiable" 7 "Left Lane Change Avaiable" 6 "lane change to the right completed" 5 "lane change to the right in progress" 4 "lane change intention to the right" 3 "lane change to the left completed" 2 "lane change to the left in progress" 1 "lane change intention to the left" 0 "normal driving" ;
VAL_ 915 ADAS2_ALCActvToTakeover 15 "Reserved" 14 "Reserved" 13 "Reserved" 12 "Reserved" 11 "Reserved" 10 "Reserved" 9 "Reserved" 8 "Reserved" 7 "Reserved" 6 "Reserved" 5 "Not Allowed Lane Marking Type" 4 "Potential Collision" 3 "Vehicle Speed too low" 2 "Turn signal reset" 1 "Big Curvature" 0 "no command" ;
VAL_ 915 ADAS2_NLP_FctActvRmm 15 "Reserved" 14 "Reserved" 13 "Reserved" 12 "Reserved" 11 "Reserved" 10 "Reserved" 9 "Reserved" 8 "Reserved" 7 "NLP override预留" 6 "recommended to change lanes to the right预留" 5 "recommended to change lanes to the left预留" 4 "NLP self recovery" 3 "NLP enable request预留" 2 "NLP  will  exit预留" 1 "NLP Auto Active Reminder预留" 0 "no command 预留" ;
VAL_ 915 ADAS2_NLPTakeoverReq 7 "Reserved" 6 "Reserved" 5 "Reserved" 4 "Brake deceleration safe stop" 3 "take over Request hard（optical&sound&haptic）" 2 "take over Request（optical&sound）" 1 "hands off warning（optical）" 0 "inactive" ;
VAL_ 915 ADAS2_TJAICA_LINE_SOURCE 3 "TIPL" 2 "DOP" 1 "Video" 0 "None" ;
VAL_ 915 ADAS2_ALCNotAvlReas 7 "Reserved" 6 "Reserved" 5 "Reserved" 4 "blind bend" 3 "No lane line" 2 "solid lines" 1 "Potential Collision" 0 "No Object" ;
VAL_ 915 ADAS2_NOAHmiDispdTxtMsgId 63 "reserved" 62 "reserved" 61 "reserved" 60 "reserved" 59 "reserved" 58 "reserved" 57 "reserved" 56 "reserved" 55 "reserved" 54 "reserved" 53 "reserved" 52 "reserved" 51 "reserved" 50 "reserved" 49 "reserved" 48 "reserved" 47 "reserved" 46 "reserved" 45 "reserved" 44 "reserved" 43 "reserved" 42 "reserved" 41 "reserved" 40 "reserved" 39 "reserved" 38 "reserved" 37 "reserved" 36 "reserved" 35 "reserved" 34 "reserved" 33 "reserved" 32 "reserved" 31 "reserved" 30 "reserved" 29 "reserved" 28 "reserved" 27 "reserved" 26 "reserved" 25 "reserved" 24 "reserved" 23 "reserved" 22 "reserved" 21 "reserved" 20 "Approaching the main road即将汇入主路" 19 "Approaching  on-ramp 即将驶入匝道" 18 "Approaching unreleased highway section in 200 m" 17 "Approaching unreleased highway section in 500 m" 16 "Road Radius is too small 预留" 15 "Behave according to the intended system usage预留" 14 "Wrong gear selected  预留" 13 "Please take a break / Drowsiness detected" 12 "Can’t get to the on-ramp请立即接管路况复杂，无法进入匝道" 11 "Near the end of the road请立即接管临近汇入尽头" 10 "Neighbouring vehicle too close预留" 9 "Outside speed range" 8 "please hands on 预留" 7 "location no tready" 6 "ESP not available 预留" 5 "ESP intervention 预留" 4 "Lane markings not present" 3 "Road condition insufficient" 2 "Unreleased highway section" 1 "NOA not available" 0 "no display" ;
VAL_ 915 ADAS2_TLA_SwitchSts 3 "Fault" 2 "Default" 1 "OFF" 0 "ON" ;
VAL_ 915 ADAS2_NOAODDTyp 15 "Reserved" 14 "Reserved" 13 "Reserved" 12 "Reserved" 11 "Reserved" 10 "Reserved" 8 "No HDMap data" 7 "Broken road" 6 "parking area" 5 "Service area" 4 "Ramp entrance" 3 "Ramp exit" 2 "Construction area" 1 "Tunnel" 0 "None" ;
VAL_ 915 ADAS2_NOADstToODD 31 "reserved" 30 "reserved" 29 "reserved" 28 "reserved" 27 "reserved" 26 "reserved" 25 "250m" 2 "20m" 1 "10m" 0 "none" ;
VAL_ 915 ADAS2_TextinfoForIntelligentCornering 2 "Reserved" 1 "Intelligent cornering" 0 "no display" ;
VAL_ 915 ADAS2_NotAvlReas 15 "Reserved" 14 "Reserved" 13 "Reserved" 12 "Reserved" 11 "Reserved" 10 "Reserved" 8 "Steering wheel angle out of range" 7 "ACC Unable Speed too high" 6 "APA Active" 5 "ADAS error" 4 "Related ECU failure" 3 "No forward gear" 2 "Driver seat belt unfastened" 1 "Door open" 0 "No text" ;
VAL_ 915 ADAS2_HmiAudioNotifId 15 "reserved" 14 "reserved" 13 "reserved" 12 "reserved" 11 "reserved" 10 "reserved" 9 "reserved" 8 "reserved" 7 "reserved" 6 "reserved" 5 "reserved" 4 "prohibition" 3 "minimal risk maneuver (safe-stop)" 2 "warning" 1 "notification" 0 "no sound notification" ;
VAL_ 915 ADAS2_ADASQuitReas 12 "~0x1F:Reserved" 11 "Steering wheel angle out of range" 10 "Speed out of range not by driver" 9 "User Cancelled" 8 "Speed out of range override" 7 "Override over 15 Minutes" 6 "Related ECU failure" 5 "No forward gear" 4 "Driver seat belt unfastened" 3 "Door open" 2 "Brake pedal depressed" 1 "Vehicle Rolling backward" 0 "No text" ;
VAL_ 915 ADAS2_Set_TJA_ICA_ACC 3 "reserved" 2 "ACC_TJA_ICA on" 1 "ACC_TJA_ICA off" 0 "Not Selected" ;
VAL_ 915 ADAS2_St_left_front_Camera 3 "Cmaera not calibrated" 2 "Camera blocked" 1 "Camera failure" 0 "Camera normal" ;
VAL_ 915 ADAS2_St_right_front_Camera 3 "Cmaera not calibrated" 2 "Camera blocked" 1 "Camera failure" 0 "Camera normal" ;
VAL_ 915 ADAS2_St_LDWLKALCKSenFb 3 "HighSensitivity" 2 "MiddleSensitivity" 1 "LowSensitivity" 0 "Not Selected" ;
VAL_ 915 ADAS2_Sw_LDWLKALCKFb 3 "Invalid；（无效，维持上一个点火周期）" 2 "Off；" 1 "On；" 0 "Inactive；（上电默认状态，维持上一个点火周期）" ;
VAL_ 915 ADAS2_St_LDWLKALCKSetFb 4 "LCK Enable(预留)；" 3 "reserved(预留)；" 2 "LKA Enable；" 1 "LDW Enable；" 0 "Inacitve；" ;
VAL_ 915 ADAS2_SwFb_ELK 3 "Fault" 2 "Switch On" 1 "Switch Off" 0 "Default 初始值" ;
VAL_ 915 ADAS2_St_LDWLKALCK 5 "Camera blocked（摄像头遮挡）；" 4 "Fault；（系统故障）" 3 "Active（系统开启）；" 2 "Standby（系统待机）；" 1 "Off（系统关闭）；" 0 "no information；" ;
VAL_ 915 ADAS2_St_ELK 3 "Fault" 2 "Active" 1 "Standby" 0 "Off" ;
VAL_ 915 ADAS2_St_ELKIntvMod 6 "Oncoming right.---对应方向前侧方区域红色显示" 5 "Oncoming left.---对应方向前侧方区域红色显示" 4 "Overtaking right；---对应方向后侧方区域红色显示" 3 "Overtaking left；---对应方向后侧方区域红色显示" 2 "Road edge right；---对应方向路沿红色显示" 1 "Road edge left；---对应方向路沿红色显示" 0 "off；--不显示" ;
VAL_ 915 ADAS2_SwFb_HMA 3 "Fault" 2 "Switch On" 1 "Switch Off" 0 "Default 初始值" ;
VAL_ 915 ADAS2_SDASts 6 "Reserved" 5 "Failure" 4 "Active" 3 "Passive" 2 "Standby" 1 "INIT" 0 "OFF" ;
VAL_ 915 ADAS2_DodgeDirection_SDA 1 "Right" 0 "Left" ;
VAL_ 915 ADAS2_TgtVehicleID_SDA 15 "Reserved" 14 "Reserved" 13 "Reserved" 12 "Obj12" 11 "Obj11" 10 "Obj10" 9 "Obj9" 8 "Obj8" 7 "Obj7" 6 "Obj6" 5 "Obj5" 4 "Obj4" 3 "Obj3" 2 "Obj2" 1 "Obj1" 0 "No Obj" ;
VAL_ 915 ADAS2_ALC_HMIlaneBlock 2 "right target lane blocked" 1 "left target lane blocked" 0 "no display" ;
VAL_ 915 ADAS2_TSR_SwtFb 3 "reserved" 2 "default" 1 "off" 0 "on" ;
VAL_ 915 ADAS2_SwFb_SDA 3 "Fault" 2 "Switch On 开关打开" 1 "Switch Off 开关关闭" 0 "Default 初始值" ;
VAL_ 915 ADAS_FDCA1_SLA_SwitchSts 3 "Reserved" 2 "Default" 1 "OFF" 0 "ON" ;
VAL_ 915 ADAS2_AEBTxtInfo 15 "Reserved" 14 "Reserved" 13 "Reserved" 12 "Reserved" 11 "Reserved" 10 "Reserved" 9 "Reserved" 8 "Reserved" 7 "Radar Blindness" 6 "AEB is switched off" 5 "AEB is switched on" 4 "AEB  is in error mode" 3 "Active" 2 "AEB is cancelled" 1 "unable to active AEB" 0 "No display" ;
VAL_ 915 ADAS2_FcwTxtInfo 15 "Reserved" 14 "Reserved" 13 "Reserved" 12 "Reserved" 11 "Reserved" 10 "Reserved" 9 "Reserved" 8 "Reserved" 7 "Radar Blindness" 6 "FCW is switched off" 5 "FCW is switched on" 4 "FCW  is in error mode" 3 "Active" 2 "FCW is cancelled" 1 "unable to active FCW" 0 "No display" ;
VAL_ 915 ADAS2_TsrSignMisc 31 "reserved" 30 "reserved" 29 "reserved" 28 "reserved" 27 "reserved" 26 "reserved" 25 "reserved" 24 "reserved" 23 "reserved" 22 "reserved" 21 "reserved" 20 "Warn Merger右侧车辆汇入" 19 "Warn Workers前方道路施 工" 18 "Warn Kids注意儿童" 17 "Warn Pedestrian Cross注意行人通过" 16 "One way street" 15 "Prohibit parking" 14 "Motorway end高速出口（reserved）" 13 "Motorway start高速入口（reserved）" 12 "yield sign让行标志" 11 "stop sign停车瞭望标志" 10 "prohibiting long parking禁止长时停车" 9 "prohibiting standing and parking禁止临时及长时停车" 8 "prohibiting motor vehicle entering禁止机动车通行(reserved)" 7 "No passing禁止通行（reserved）" 6 "No entry禁止驶入" 5 "prohibiting U-turning禁止掉头" 4 "prohibiting turning right禁止右转" 3 "prohibiting turning left禁止左转" 2 "end of no overtaking解除禁止超车" 1 "no overtaking禁止超车" 0 "default（No display）" ;
VAL_ 915 ADAS2_St_SLAMode 7 "Reserved" 6 "Reserved" 5 "Reserved" 4 "Defect" 3 "Navigation only mode" 2 "Vision mode" 1 "Fusion mode" 0 "Off" ;
VAL_ 915 ADAS2_St_SLAFault 3 "Reserved" 2 "Navigation fault" 1 "Camera fault" 0 "Normal" ;
VAL_ 915 ADAS2_FcwSwtFb 3 "Reserved" 2 "Reserved" 1 "On" 0 "Off" ;
VAL_ 915 ADAS2_AebSwtFb 3 "Reserved" 2 "Reserved" 1 "On" 0 "Off" ;
VAL_ 915 ADAS_FDCA1_SLAWarn_SwitchSts 3 "Reserved" 2 "Default" 1 "OFF" 0 "ON" ;
VAL_ 915 ADAS2_AebReq 7 "reserved" 6 "reserved" 5 "FCTB" 4 "EBA" 3 "AEB~cyclist" 2 "AEB~VRU" 1 "AEB" 0 "No demand" ;
VAL_ 915 ADAS2_HWASts 8 "Reserve" 7 "Failure" 6 "TOR" 5 "Active" 4 "Active Request" 3 "Enable" 2 "Passive" 1 "Init" 0 "OFF" ;
VAL_ 915 ADAS2_BvmSetFb 3 "Fault" 2 "OFF" 1 "ON" 0 "Default" ;
VAL_ 915 ADAS2_BvmDispReq 3 "Request to display error view" 2 "Request to display single Right side view" 1 "Request to display single  Left side view" 0 "Initial" ;
VAL_ 915 ADAS2_St_left_rear_Camera 3 "Cmaera not calibrated" 2 "Camera blocked" 1 "Camera failure" 0 "Camera normal" ;
VAL_ 915 ADAS2_St_right_rear_Camera 3 "Cmaera not calibrated" 2 "Camera blocked" 1 "Camera failure" 0 "Camera normal" ;
VAL_ 915 ADAS2_BvmViewMod 1 "Single Right side view" 0 "Single  Left side view" ;
VAL_ 915 ADAS2_St_ELKSenFeedback 2 "High Sensitivity" 1 "Low Sensitivity" 0 "Not Selected" ;
VAL_ 915 ADC_ADASYSSTS 1 "FAILURE" 0 "NO FAILURE" ;
VAL_ 915 ADC_enum_PrkgBuzAlrmLvlReq 7 "reserved" 6 "reserved" 5 "reserved" 4 "Buzzer4" 3 "Buzzer3" 2 "Buzzer2" 1 "Buzzer1" 0 "No Request" ;
VAL_ 915 ADC_SysStartupInPro 1 "Active" 0 "None" ;
VAL_ 915 ADC_IMUSentiWarningSts 7 "Invalid" 6 "reserved" 5 "reserved" 4 "reserved" 3 "reserved" 2 "shaking" 1 "normal" 0 "Initialize" ;
VAL_ 915 MPC_SOCOffSwtFb 3 "reserved" 2 "Initialization" 1 "On" 0 "Off" ;
VAL_ 547 AdasHmiNeighboringObj1ObjTyp 7 "reserved" 6 "three-wheeler 三轮车" 5 "bus 公共汽车" 4 "pedestrian 行人" 3 "motorbike/Bicycle 二轮车" 2 "truck 卡车" 1 "passenger car 小轿车" 0 "Object not present" ;
VAL_ 547 AdasHmiNeighboringObj1XOut 255 "distance (positive values are front, negative values rear from ego center)" 254 "distance (positive values are front, negative values rear from ego center)" 253 "distance (positive values are front, negative values rear from ego center)" 252 "distance (positive values are front, negative values rear from ego center)" 251 "distance (positive values are front, negative values rear from ego center)" 250 "distance (positive values are front, negative values rear from ego center)" 249 "distance (positive values are front, negative values rear from ego center)" 248 "distance (positive values are front, negative values rear from ego center)" 247 "distance (positive values are front, negative values rear from ego center)" 246 "distance (positive values are front, negative values rear from ego center)" 245 "distance (positive values are front, negative values rear from ego center)" 244 "distance (positive values are front, negative values rear from ego center)" 243 "distance (positive values are front, negative values rear from ego center)" 242 "distance (positive values are front, negative values rear from ego center)" 241 "distance (positive values are front, negative values rear from ego center)" 240 "distance (positive values are front, negative values rear from ego center)" 239 "distance (positive values are front, negative values rear from ego center)" 238 "distance (positive values are front, negative values rear from ego center)" 237 "distance (positive values are front, negative values rear from ego center)" 236 "distance (positive values are front, negative values rear from ego center)" 235 "distance (positive values are front, negative values rear from ego center)" 234 "distance (positive values are front, negative values rear from ego center)" 233 "distance (positive values are front, negative values rear from ego center)" 232 "distance (positive values are front, negative values rear from ego center)" 231 "distance (positive values are front, negative values rear from ego center)" 230 "distance (positive values are front, negative values rear from ego center)" 229 "distance (positive values are front, negative values rear from ego center)" 228 "distance (positive values are front, negative values rear from ego center)" 227 "distance (positive values are front, negative values rear from ego center)" 226 "distance (positive values are front, negative values rear from ego center)" 225 "distance (positive values are front, negative values rear from ego center)" 224 "distance (positive values are front, negative values rear from ego center)" 223 "distance (positive values are front, negative values rear from ego center)" 222 "distance (positive values are front, negative values rear from ego center)" 221 "distance (positive values are front, negative values rear from ego center)" 220 "distance (positive values are front, negative values rear from ego center)" 219 "distance (positive values are front, negative values rear from ego center)" 218 "distance (positive values are front, negative values rear from ego center)" 217 "distance (positive values are front, negative values rear from ego center)" 216 "distance (positive values are front, negative values rear from ego center)" 215 "distance (positive values are front, negative values rear from ego center)" 214 "distance (positive values are front, negative values rear from ego center)" 213 "distance (positive values are front, negative values rear from ego center)" 212 "distance (positive values are front, negative values rear from ego center)" 211 "distance (positive values are front, negative values rear from ego center)" 210 "distance (positive values are front, negative values rear from ego center)" 209 "distance (positive values are front, negative values rear from ego center)" 208 "distance (positive values are front, negative values rear from ego center)" 207 "distance (positive values are front, negative values rear from ego center)" 206 "distance (positive values are front, negative values rear from ego center)" 205 "distance (positive values are front, negative values rear from ego center)" 204 "distance (positive values are front, negative values rear from ego center)" 203 "distance (positive values are front, negative values rear from ego center)" 202 "distance (positive values are front, negative values rear from ego center)" 201 "distance (positive values are front, negative values rear from ego center)" 200 "distance (positive values are front, negative values rear from ego center)" 199 "distance (positive values are front, negative values rear from ego center)" 198 "distance (positive values are front, negative values rear from ego center)" 197 "distance (positive values are front, negative values rear from ego center)" 196 "distance (positive values are front, negative values rear from ego center)" 195 "distance (positive values are front, negative values rear from ego center)" 194 "distance (positive values are front, negative values rear from ego center)" 193 "distance (positive values are front, negative values rear from ego center)" 192 "distance (positive values are front, negative values rear from ego center)" 191 "distance (positive values are front, negative values rear from ego center)" 190 "distance (positive values are front, negative values rear from ego center)" 189 "distance (positive values are front, negative values rear from ego center)" 188 "distance (positive values are front, negative values rear from ego center)" 187 "distance (positive values are front, negative values rear from ego center)" 186 "distance (positive values are front, negative values rear from ego center)" 185 "distance (positive values are front, negative values rear from ego center)" 184 "distance (positive values are front, negative values rear from ego center)" 183 "distance (positive values are front, negative values rear from ego center)" 182 "distance (positive values are front, negative values rear from ego center)" 181 "distance (positive values are front, negative values rear from ego center)" 180 "distance (positive values are front, negative values rear from ego center)" 179 "distance (positive values are front, negative values rear from ego center)" 178 "distance (positive values are front, negative values rear from ego center)" 177 "distance (positive values are front, negative values rear from ego center)" 176 "distance (positive values are front, negative values rear from ego center)" 175 "distance (positive values are front, negative values rear from ego center)" 174 "distance (positive values are front, negative values rear from ego center)" 173 "distance (positive values are front, negative values rear from ego center)" 172 "distance (positive values are front, negative values rear from ego center)" 171 "distance (positive values are front, negative values rear from ego center)" 170 "distance (positive values are front, negative values rear from ego center)" 169 "distance (positive values are front, negative values rear from ego center)" 168 "distance (positive values are front, negative values rear from ego center)" 167 "distance (positive values are front, negative values rear from ego center)" 166 "distance (positive values are front, negative values rear from ego center)" 165 "distance (positive values are front, negative values rear from ego center)" 164 "distance (positive values are front, negative values rear from ego center)" 163 "distance (positive values are front, negative values rear from ego center)" 162 "distance (positive values are front, negative values rear from ego center)" 161 "distance (positive values are front, negative values rear from ego center)" 160 "distance (positive values are front, negative values rear from ego center)" 159 "distance (positive values are front, negative values rear from ego center)" 158 "distance (positive values are front, negative values rear from ego center)" 157 "distance (positive values are front, negative values rear from ego center)" 156 "distance (positive values are front, negative values rear from ego center)" 155 "distance (positive values are front, negative values rear from ego center)" 154 "distance (positive values are front, negative values rear from ego center)" 153 "distance (positive values are front, negative values rear from ego center)" 152 "distance (positive values are front, negative values rear from ego center)" 151 "distance (positive values are front, negative values rear from ego center)" 150 "distance (positive values are front, negative values rear from ego center)" 149 "distance (positive values are front, negative values rear from ego center)" 148 "distance (positive values are front, negative values rear from ego center)" 147 "distance (positive values are front, negative values rear from ego center)" 146 "distance (positive values are front, negative values rear from ego center)" 145 "distance (positive values are front, negative values rear from ego center)" 144 "distance (positive values are front, negative values rear from ego center)" 143 "distance (positive values are front, negative values rear from ego center)" 142 "distance (positive values are front, negative values rear from ego center)" 141 "distance (positive values are front, negative values rear from ego center)" 140 "distance (positive values are front, negative values rear from ego center)" 139 "distance (positive values are front, negative values rear from ego center)" 138 "distance (positive values are front, negative values rear from ego center)" 137 "distance (positive values are front, negative values rear from ego center)" 136 "distance (positive values are front, negative values rear from ego center)" 135 "distance (positive values are front, negative values rear from ego center)" 134 "distance (positive values are front, negative values rear from ego center)" 133 "distance (positive values are front, negative values rear from ego center)" 132 "distance (positive values are front, negative values rear from ego center)" 131 "distance (positive values are front, negative values rear from ego center)" 130 "distance (positive values are front, negative values rear from ego center)" 129 "distance (positive values are front, negative values rear from ego center)" 128 "distance (positive values are front, negative values rear from ego center)" 127 "distance (positive values are front, negative values rear from ego center)" 126 "distance (positive values are front, negative values rear from ego center)" 125 "distance (positive values are front, negative values rear from ego center)" 124 "distance (positive values are front, negative values rear from ego center)" 123 "distance (positive values are front, negative values rear from ego center)" 122 "distance (positive values are front, negative values rear from ego center)" 121 "distance (positive values are front, negative values rear from ego center)" 120 "distance (positive values are front, negative values rear from ego center)" 119 "distance (positive values are front, negative values rear from ego center)" 118 "distance (positive values are front, negative values rear from ego center)" 117 "distance (positive values are front, negative values rear from ego center)" 116 "distance (positive values are front, negative values rear from ego center)" 115 "distance (positive values are front, negative values rear from ego center)" 114 "distance (positive values are front, negative values rear from ego center)" 113 "distance (positive values are front, negative values rear from ego center)" 112 "distance (positive values are front, negative values rear from ego center)" 111 "distance (positive values are front, negative values rear from ego center)" 110 "distance (positive values are front, negative values rear from ego center)" 109 "distance (positive values are front, negative values rear from ego center)" 108 "distance (positive values are front, negative values rear from ego center)" 107 "distance (positive values are front, negative values rear from ego center)" 106 "distance (positive values are front, negative values rear from ego center)" 105 "distance (positive values are front, negative values rear from ego center)" 104 "distance (positive values are front, negative values rear from ego center)" 103 "distance (positive values are front, negative values rear from ego center)" 102 "distance (positive values are front, negative values rear from ego center)" 101 "distance (positive values are front, negative values rear from ego center)" 100 "distance (positive values are front, negative values rear from ego center)" 99 "distance (positive values are front, negative values rear from ego center)" 98 "distance (positive values are front, negative values rear from ego center)" 97 "distance (positive values are front, negative values rear from ego center)" 96 "distance (positive values are front, negative values rear from ego center)" 95 "distance (positive values are front, negative values rear from ego center)" 94 "distance (positive values are front, negative values rear from ego center)" 93 "distance (positive values are front, negative values rear from ego center)" 92 "distance (positive values are front, negative values rear from ego center)" 91 "distance (positive values are front, negative values rear from ego center)" 90 "distance (positive values are front, negative values rear from ego center)" 89 "distance (positive values are front, negative values rear from ego center)" 88 "distance (positive values are front, negative values rear from ego center)" 87 "distance (positive values are front, negative values rear from ego center)" 86 "distance (positive values are front, negative values rear from ego center)" 85 "distance (positive values are front, negative values rear from ego center)" 84 "distance (positive values are front, negative values rear from ego center)" 83 "distance (positive values are front, negative values rear from ego center)" 82 "distance (positive values are front, negative values rear from ego center)" 81 "distance (positive values are front, negative values rear from ego center)" 80 "distance (positive values are front, negative values rear from ego center)" 79 "distance (positive values are front, negative values rear from ego center)" 78 "distance (positive values are front, negative values rear from ego center)" 77 "distance (positive values are front, negative values rear from ego center)" 76 "distance (positive values are front, negative values rear from ego center)" 75 "distance (positive values are front, negative values rear from ego center)" 74 "distance (positive values are front, negative values rear from ego center)" 73 "distance (positive values are front, negative values rear from ego center)" 72 "distance (positive values are front, negative values rear from ego center)" 71 "distance (positive values are front, negative values rear from ego center)" 70 "distance (positive values are front, negative values rear from ego center)" 69 "distance (positive values are front, negative values rear from ego center)" 68 "distance (positive values are front, negative values rear from ego center)" 67 "distance (positive values are front, negative values rear from ego center)" 66 "distance (positive values are front, negative values rear from ego center)" 65 "distance (positive values are front, negative values rear from ego center)" 64 "distance (positive values are front, negative values rear from ego center)" 63 "distance (positive values are front, negative values rear from ego center)" 62 "distance (positive values are front, negative values rear from ego center)" 61 "distance (positive values are front, negative values rear from ego center)" 60 "distance (positive values are front, negative values rear from ego center)" 59 "distance (positive values are front, negative values rear from ego center)" 58 "distance (positive values are front, negative values rear from ego center)" 57 "distance (positive values are front, negative values rear from ego center)" 56 "distance (positive values are front, negative values rear from ego center)" 55 "distance (positive values are front, negative values rear from ego center)" 54 "distance (positive values are front, negative values rear from ego center)" 53 "distance (positive values are front, negative values rear from ego center)" 52 "distance (positive values are front, negative values rear from ego center)" 51 "distance (positive values are front, negative values rear from ego center)" 50 "distance (positive values are front, negative values rear from ego center)" 49 "distance (positive values are front, negative values rear from ego center)" 48 "distance (positive values are front, negative values rear from ego center)" 47 "distance (positive values are front, negative values rear from ego center)" 46 "distance (positive values are front, negative values rear from ego center)" 45 "distance (positive values are front, negative values rear from ego center)" 44 "distance (positive values are front, negative values rear from ego center)" 43 "distance (positive values are front, negative values rear from ego center)" 42 "distance (positive values are front, negative values rear from ego center)" 41 "distance (positive values are front, negative values rear from ego center)" 40 "distance (positive values are front, negative values rear from ego center)" 39 "distance (positive values are front, negative values rear from ego center)" 38 "distance (positive values are front, negative values rear from ego center)" 37 "distance (positive values are front, negative values rear from ego center)" 36 "distance (positive values are front, negative values rear from ego center)" 35 "distance (positive values are front, negative values rear from ego center)" 34 "distance (positive values are front, negative values rear from ego center)" 33 "distance (positive values are front, negative values rear from ego center)" 32 "distance (positive values are front, negative values rear from ego center)" 31 "distance (positive values are front, negative values rear from ego center)" 30 "distance (positive values are front, negative values rear from ego center)" 29 "distance (positive values are front, negative values rear from ego center)" 28 "distance (positive values are front, negative values rear from ego center)" 27 "distance (positive values are front, negative values rear from ego center)" 26 "distance (positive values are front, negative values rear from ego center)" 25 "distance (positive values are front, negative values rear from ego center)" 24 "distance (positive values are front, negative values rear from ego center)" 23 "distance (positive values are front, negative values rear from ego center)" 22 "distance (positive values are front, negative values rear from ego center)" 21 "distance (positive values are front, negative values rear from ego center)" 20 "distance (positive values are front, negative values rear from ego center)" 19 "distance (positive values are front, negative values rear from ego center)" 18 "distance (positive values are front, negative values rear from ego center)" 17 "distance (positive values are front, negative values rear from ego center)" 16 "distance (positive values are front, negative values rear from ego center)" 15 "distance (positive values are front, negative values rear from ego center)" 14 "distance (positive values are front, negative values rear from ego center)" 13 "distance (positive values are front, negative values rear from ego center)" 12 "distance (positive values are front, negative values rear from ego center)" 11 "distance (positive values are front, negative values rear from ego center)" 10 "distance (positive values are front, negative values rear from ego center)" 9 "distance (positive values are front, negative values rear from ego center)" 8 "distance (positive values are front, negative values rear from ego center)" 7 "distance (positive values are front, negative values rear from ego center)" 6 "distance (positive values are front, negative values rear from ego center)" 5 "distance (positive values are front, negative values rear from ego center)" 4 "distance (positive values are front, negative values rear from ego center)" 3 "distance (positive values are front, negative values rear from ego center)" 2 "distance (positive values are front, negative values rear from ego center)" 1 "distance (positive values are front, negative values rear from ego center)" 0 "distance (positive values are front, negative values rear from ego center)" ;
VAL_ 547 AdasHmiNeighboringObj1YOut 255 "distance right from ego center" 254 "distance right from ego center" 253 "distance right from ego center" 252 "distance right from ego center" 251 "distance right from ego center" 250 "distance right from ego center" 249 "distance right from ego center" 248 "distance right from ego center" 247 "distance right from ego center" 246 "distance right from ego center" 245 "distance right from ego center" 244 "distance right from ego center" 243 "distance right from ego center" 242 "distance right from ego center" 241 "distance right from ego center" 240 "distance right from ego center" 239 "distance right from ego center" 238 "distance right from ego center" 237 "distance right from ego center" 236 "distance right from ego center" 235 "distance right from ego center" 234 "distance right from ego center" 233 "distance right from ego center" 232 "distance right from ego center" 231 "distance right from ego center" 230 "distance right from ego center" 229 "distance right from ego center" 228 "distance right from ego center" 227 "distance right from ego center" 226 "distance right from ego center" 225 "distance right from ego center" 224 "distance right from ego center" 223 "distance right from ego center" 222 "distance right from ego center" 221 "distance right from ego center" 220 "distance right from ego center" 219 "distance right from ego center" 218 "distance right from ego center" 217 "distance right from ego center" 216 "distance right from ego center" 215 "distance right from ego center" 214 "distance right from ego center" 213 "distance right from ego center" 212 "distance right from ego center" 211 "distance right from ego center" 210 "distance right from ego center" 209 "distance right from ego center" 208 "distance right from ego center" 207 "distance right from ego center" 206 "distance right from ego center" 205 "distance right from ego center" 204 "distance right from ego center" 203 "distance right from ego center" 202 "distance right from ego center" 201 "distance right from ego center" 200 "distance right from ego center" 199 "distance right from ego center" 198 "distance right from ego center" 197 "distance right from ego center" 196 "distance right from ego center" 195 "distance right from ego center" 194 "distance right from ego center" 193 "distance right from ego center" 192 "distance right from ego center" 191 "distance right from ego center" 190 "distance right from ego center" 189 "distance right from ego center" 188 "distance right from ego center" 187 "distance right from ego center" 186 "distance right from ego center" 185 "distance right from ego center" 184 "distance right from ego center" 183 "distance right from ego center" 182 "distance right from ego center" 181 "distance right from ego center" 180 "distance right from ego center" 179 "distance right from ego center" 178 "distance right from ego center" 177 "distance right from ego center" 176 "distance right from ego center" 175 "distance right from ego center" 174 "distance right from ego center" 173 "distance right from ego center" 172 "distance right from ego center" 171 "distance right from ego center" 170 "distance right from ego center" 169 "distance right from ego center" 168 "distance right from ego center" 167 "distance right from ego center" 166 "distance right from ego center" 165 "distance right from ego center" 164 "distance right from ego center" 163 "distance right from ego center" 162 "distance right from ego center" 161 "distance right from ego center" 160 "distance right from ego center" 159 "distance right from ego center" 158 "distance right from ego center" 157 "distance right from ego center" 156 "distance right from ego center" 155 "distance right from ego center" 154 "distance right from ego center" 153 "distance right from ego center" 152 "distance right from ego center" 151 "distance right from ego center" 150 "distance right from ego center" 149 "distance right from ego center" 148 "distance right from ego center" 147 "distance right from ego center" 146 "distance right from ego center" 145 "distance right from ego center" 144 "distance right from ego center" 143 "distance right from ego center" 142 "distance right from ego center" 141 "distance right from ego center" 140 "distance right from ego center" 139 "distance right from ego center" 138 "distance right from ego center" 137 "distance right from ego center" 136 "distance right from ego center" 135 "distance right from ego center" 134 "distance right from ego center" 133 "distance right from ego center" 132 "distance right from ego center" 131 "distance right from ego center" 130 "distance right from ego center" 129 "distance right from ego center" 128 "distance right from ego center" 127 "distance left from ego center" 126 "distance left from ego center" 125 "distance left from ego center" 124 "distance left from ego center" 123 "distance left from ego center" 122 "distance left from ego center" 121 "distance left from ego center" 120 "distance left from ego center" 119 "distance left from ego center" 118 "distance left from ego center" 117 "distance left from ego center" 116 "distance left from ego center" 115 "distance left from ego center" 114 "distance left from ego center" 113 "distance left from ego center" 112 "distance left from ego center" 111 "distance left from ego center" 110 "distance left from ego center" 109 "distance left from ego center" 108 "distance left from ego center" 107 "distance left from ego center" 106 "distance left from ego center" 105 "distance left from ego center" 104 "distance left from ego center" 103 "distance left from ego center" 102 "distance left from ego center" 101 "distance left from ego center" 100 "distance left from ego center" 99 "distance left from ego center" 98 "distance left from ego center" 97 "distance left from ego center" 96 "distance left from ego center" 95 "distance left from ego center" 94 "distance left from ego center" 93 "distance left from ego center" 92 "distance left from ego center" 91 "distance left from ego center" 90 "distance left from ego center" 89 "distance left from ego center" 88 "distance left from ego center" 87 "distance left from ego center" 86 "distance left from ego center" 85 "distance left from ego center" 84 "distance left from ego center" 83 "distance left from ego center" 82 "distance left from ego center" 81 "distance left from ego center" 80 "distance left from ego center" 79 "distance left from ego center" 78 "distance left from ego center" 77 "distance left from ego center" 76 "distance left from ego center" 75 "distance left from ego center" 74 "distance left from ego center" 73 "distance left from ego center" 72 "distance left from ego center" 71 "distance left from ego center" 70 "distance left from ego center" 69 "distance left from ego center" 68 "distance left from ego center" 67 "distance left from ego center" 66 "distance left from ego center" 65 "distance left from ego center" 64 "distance left from ego center" 63 "distance left from ego center" 62 "distance left from ego center" 61 "distance left from ego center" 60 "distance left from ego center" 59 "distance left from ego center" 58 "distance left from ego center" 57 "distance left from ego center" 56 "distance left from ego center" 55 "distance left from ego center" 54 "distance left from ego center" 53 "distance left from ego center" 52 "distance left from ego center" 51 "distance left from ego center" 50 "distance left from ego center" 49 "distance left from ego center" 48 "distance left from ego center" 47 "distance left from ego center" 46 "distance left from ego center" 45 "distance left from ego center" 44 "distance left from ego center" 43 "distance left from ego center" 42 "distance left from ego center" 41 "distance left from ego center" 40 "distance left from ego center" 39 "distance left from ego center" 38 "distance left from ego center" 37 "distance left from ego center" 36 "distance left from ego center" 35 "distance left from ego center" 34 "distance left from ego center" 33 "distance left from ego center" 32 "distance left from ego center" 31 "distance left from ego center" 30 "distance left from ego center" 29 "distance left from ego center" 28 "distance left from ego center" 27 "distance left from ego center" 26 "distance left from ego center" 25 "distance left from ego center" 24 "distance left from ego center" 23 "distance left from ego center" 22 "distance left from ego center" 21 "distance left from ego center" 20 "distance left from ego center" 19 "distance left from ego center" 18 "distance left from ego center" 17 "distance left from ego center" 16 "distance left from ego center" 15 "distance left from ego center" 14 "distance left from ego center" 13 "distance left from ego center" 12 "distance left from ego center" 11 "distance left from ego center" 10 "distance left from ego center" 9 "distance left from ego center" 8 "distance left from ego center" 7 "distance left from ego center" 6 "distance left from ego center" 5 "distance left from ego center" 4 "distance left from ego center" 3 "distance left from ego center" 2 "distance left from ego center" 1 "distance left from ego center" 0 "distance left from ego center" ;
VAL_ 547 AdasHmiNeighboringObj2ObjTyp 7 "reserved" 6 "three-wheeler 三轮车" 5 "bus 公共汽车" 4 "pedestrian 行人" 3 "motorbike/Bicycle 二轮车" 2 "truck 卡车" 1 "passenger car 小轿车" 0 "Object not present" ;
VAL_ 547 AdasHmiNeighboringObj2XOut 255 "distance (positive values are front, negative values rear from ego center)" 254 "distance (positive values are front, negative values rear from ego center)" 253 "distance (positive values are front, negative values rear from ego center)" 252 "distance (positive values are front, negative values rear from ego center)" 251 "distance (positive values are front, negative values rear from ego center)" 250 "distance (positive values are front, negative values rear from ego center)" 249 "distance (positive values are front, negative values rear from ego center)" 248 "distance (positive values are front, negative values rear from ego center)" 247 "distance (positive values are front, negative values rear from ego center)" 246 "distance (positive values are front, negative values rear from ego center)" 245 "distance (positive values are front, negative values rear from ego center)" 244 "distance (positive values are front, negative values rear from ego center)" 243 "distance (positive values are front, negative values rear from ego center)" 242 "distance (positive values are front, negative values rear from ego center)" 241 "distance (positive values are front, negative values rear from ego center)" 240 "distance (positive values are front, negative values rear from ego center)" 239 "distance (positive values are front, negative values rear from ego center)" 238 "distance (positive values are front, negative values rear from ego center)" 237 "distance (positive values are front, negative values rear from ego center)" 236 "distance (positive values are front, negative values rear from ego center)" 235 "distance (positive values are front, negative values rear from ego center)" 234 "distance (positive values are front, negative values rear from ego center)" 233 "distance (positive values are front, negative values rear from ego center)" 232 "distance (positive values are front, negative values rear from ego center)" 231 "distance (positive values are front, negative values rear from ego center)" 230 "distance (positive values are front, negative values rear from ego center)" 229 "distance (positive values are front, negative values rear from ego center)" 228 "distance (positive values are front, negative values rear from ego center)" 227 "distance (positive values are front, negative values rear from ego center)" 226 "distance (positive values are front, negative values rear from ego center)" 225 "distance (positive values are front, negative values rear from ego center)" 224 "distance (positive values are front, negative values rear from ego center)" 223 "distance (positive values are front, negative values rear from ego center)" 222 "distance (positive values are front, negative values rear from ego center)" 221 "distance (positive values are front, negative values rear from ego center)" 220 "distance (positive values are front, negative values rear from ego center)" 219 "distance (positive values are front, negative values rear from ego center)" 218 "distance (positive values are front, negative values rear from ego center)" 217 "distance (positive values are front, negative values rear from ego center)" 216 "distance (positive values are front, negative values rear from ego center)" 215 "distance (positive values are front, negative values rear from ego center)" 214 "distance (positive values are front, negative values rear from ego center)" 213 "distance (positive values are front, negative values rear from ego center)" 212 "distance (positive values are front, negative values rear from ego center)" 211 "distance (positive values are front, negative values rear from ego center)" 210 "distance (positive values are front, negative values rear from ego center)" 209 "distance (positive values are front, negative values rear from ego center)" 208 "distance (positive values are front, negative values rear from ego center)" 207 "distance (positive values are front, negative values rear from ego center)" 206 "distance (positive values are front, negative values rear from ego center)" 205 "distance (positive values are front, negative values rear from ego center)" 204 "distance (positive values are front, negative values rear from ego center)" 203 "distance (positive values are front, negative values rear from ego center)" 202 "distance (positive values are front, negative values rear from ego center)" 201 "distance (positive values are front, negative values rear from ego center)" 200 "distance (positive values are front, negative values rear from ego center)" 199 "distance (positive values are front, negative values rear from ego center)" 198 "distance (positive values are front, negative values rear from ego center)" 197 "distance (positive values are front, negative values rear from ego center)" 196 "distance (positive values are front, negative values rear from ego center)" 195 "distance (positive values are front, negative values rear from ego center)" 194 "distance (positive values are front, negative values rear from ego center)" 193 "distance (positive values are front, negative values rear from ego center)" 192 "distance (positive values are front, negative values rear from ego center)" 191 "distance (positive values are front, negative values rear from ego center)" 190 "distance (positive values are front, negative values rear from ego center)" 189 "distance (positive values are front, negative values rear from ego center)" 188 "distance (positive values are front, negative values rear from ego center)" 187 "distance (positive values are front, negative values rear from ego center)" 186 "distance (positive values are front, negative values rear from ego center)" 185 "distance (positive values are front, negative values rear from ego center)" 184 "distance (positive values are front, negative values rear from ego center)" 183 "distance (positive values are front, negative values rear from ego center)" 182 "distance (positive values are front, negative values rear from ego center)" 181 "distance (positive values are front, negative values rear from ego center)" 180 "distance (positive values are front, negative values rear from ego center)" 179 "distance (positive values are front, negative values rear from ego center)" 178 "distance (positive values are front, negative values rear from ego center)" 177 "distance (positive values are front, negative values rear from ego center)" 176 "distance (positive values are front, negative values rear from ego center)" 175 "distance (positive values are front, negative values rear from ego center)" 174 "distance (positive values are front, negative values rear from ego center)" 173 "distance (positive values are front, negative values rear from ego center)" 172 "distance (positive values are front, negative values rear from ego center)" 171 "distance (positive values are front, negative values rear from ego center)" 170 "distance (positive values are front, negative values rear from ego center)" 169 "distance (positive values are front, negative values rear from ego center)" 168 "distance (positive values are front, negative values rear from ego center)" 167 "distance (positive values are front, negative values rear from ego center)" 166 "distance (positive values are front, negative values rear from ego center)" 165 "distance (positive values are front, negative values rear from ego center)" 164 "distance (positive values are front, negative values rear from ego center)" 163 "distance (positive values are front, negative values rear from ego center)" 162 "distance (positive values are front, negative values rear from ego center)" 161 "distance (positive values are front, negative values rear from ego center)" 160 "distance (positive values are front, negative values rear from ego center)" 159 "distance (positive values are front, negative values rear from ego center)" 158 "distance (positive values are front, negative values rear from ego center)" 157 "distance (positive values are front, negative values rear from ego center)" 156 "distance (positive values are front, negative values rear from ego center)" 155 "distance (positive values are front, negative values rear from ego center)" 154 "distance (positive values are front, negative values rear from ego center)" 153 "distance (positive values are front, negative values rear from ego center)" 152 "distance (positive values are front, negative values rear from ego center)" 151 "distance (positive values are front, negative values rear from ego center)" 150 "distance (positive values are front, negative values rear from ego center)" 149 "distance (positive values are front, negative values rear from ego center)" 148 "distance (positive values are front, negative values rear from ego center)" 147 "distance (positive values are front, negative values rear from ego center)" 146 "distance (positive values are front, negative values rear from ego center)" 145 "distance (positive values are front, negative values rear from ego center)" 144 "distance (positive values are front, negative values rear from ego center)" 143 "distance (positive values are front, negative values rear from ego center)" 142 "distance (positive values are front, negative values rear from ego center)" 141 "distance (positive values are front, negative values rear from ego center)" 140 "distance (positive values are front, negative values rear from ego center)" 139 "distance (positive values are front, negative values rear from ego center)" 138 "distance (positive values are front, negative values rear from ego center)" 137 "distance (positive values are front, negative values rear from ego center)" 136 "distance (positive values are front, negative values rear from ego center)" 135 "distance (positive values are front, negative values rear from ego center)" 134 "distance (positive values are front, negative values rear from ego center)" 133 "distance (positive values are front, negative values rear from ego center)" 132 "distance (positive values are front, negative values rear from ego center)" 131 "distance (positive values are front, negative values rear from ego center)" 130 "distance (positive values are front, negative values rear from ego center)" 129 "distance (positive values are front, negative values rear from ego center)" 128 "distance (positive values are front, negative values rear from ego center)" 127 "distance (positive values are front, negative values rear from ego center)" 126 "distance (positive values are front, negative values rear from ego center)" 125 "distance (positive values are front, negative values rear from ego center)" 124 "distance (positive values are front, negative values rear from ego center)" 123 "distance (positive values are front, negative values rear from ego center)" 122 "distance (positive values are front, negative values rear from ego center)" 121 "distance (positive values are front, negative values rear from ego center)" 120 "distance (positive values are front, negative values rear from ego center)" 119 "distance (positive values are front, negative values rear from ego center)" 118 "distance (positive values are front, negative values rear from ego center)" 117 "distance (positive values are front, negative values rear from ego center)" 116 "distance (positive values are front, negative values rear from ego center)" 115 "distance (positive values are front, negative values rear from ego center)" 114 "distance (positive values are front, negative values rear from ego center)" 113 "distance (positive values are front, negative values rear from ego center)" 112 "distance (positive values are front, negative values rear from ego center)" 111 "distance (positive values are front, negative values rear from ego center)" 110 "distance (positive values are front, negative values rear from ego center)" 109 "distance (positive values are front, negative values rear from ego center)" 108 "distance (positive values are front, negative values rear from ego center)" 107 "distance (positive values are front, negative values rear from ego center)" 106 "distance (positive values are front, negative values rear from ego center)" 105 "distance (positive values are front, negative values rear from ego center)" 104 "distance (positive values are front, negative values rear from ego center)" 103 "distance (positive values are front, negative values rear from ego center)" 102 "distance (positive values are front, negative values rear from ego center)" 101 "distance (positive values are front, negative values rear from ego center)" 100 "distance (positive values are front, negative values rear from ego center)" 99 "distance (positive values are front, negative values rear from ego center)" 98 "distance (positive values are front, negative values rear from ego center)" 97 "distance (positive values are front, negative values rear from ego center)" 96 "distance (positive values are front, negative values rear from ego center)" 95 "distance (positive values are front, negative values rear from ego center)" 94 "distance (positive values are front, negative values rear from ego center)" 93 "distance (positive values are front, negative values rear from ego center)" 92 "distance (positive values are front, negative values rear from ego center)" 91 "distance (positive values are front, negative values rear from ego center)" 90 "distance (positive values are front, negative values rear from ego center)" 89 "distance (positive values are front, negative values rear from ego center)" 88 "distance (positive values are front, negative values rear from ego center)" 87 "distance (positive values are front, negative values rear from ego center)" 86 "distance (positive values are front, negative values rear from ego center)" 85 "distance (positive values are front, negative values rear from ego center)" 84 "distance (positive values are front, negative values rear from ego center)" 83 "distance (positive values are front, negative values rear from ego center)" 82 "distance (positive values are front, negative values rear from ego center)" 81 "distance (positive values are front, negative values rear from ego center)" 80 "distance (positive values are front, negative values rear from ego center)" 79 "distance (positive values are front, negative values rear from ego center)" 78 "distance (positive values are front, negative values rear from ego center)" 77 "distance (positive values are front, negative values rear from ego center)" 76 "distance (positive values are front, negative values rear from ego center)" 75 "distance (positive values are front, negative values rear from ego center)" 74 "distance (positive values are front, negative values rear from ego center)" 73 "distance (positive values are front, negative values rear from ego center)" 72 "distance (positive values are front, negative values rear from ego center)" 71 "distance (positive values are front, negative values rear from ego center)" 70 "distance (positive values are front, negative values rear from ego center)" 69 "distance (positive values are front, negative values rear from ego center)" 68 "distance (positive values are front, negative values rear from ego center)" 67 "distance (positive values are front, negative values rear from ego center)" 66 "distance (positive values are front, negative values rear from ego center)" 65 "distance (positive values are front, negative values rear from ego center)" 64 "distance (positive values are front, negative values rear from ego center)" 63 "distance (positive values are front, negative values rear from ego center)" 62 "distance (positive values are front, negative values rear from ego center)" 61 "distance (positive values are front, negative values rear from ego center)" 60 "distance (positive values are front, negative values rear from ego center)" 59 "distance (positive values are front, negative values rear from ego center)" 58 "distance (positive values are front, negative values rear from ego center)" 57 "distance (positive values are front, negative values rear from ego center)" 56 "distance (positive values are front, negative values rear from ego center)" 55 "distance (positive values are front, negative values rear from ego center)" 54 "distance (positive values are front, negative values rear from ego center)" 53 "distance (positive values are front, negative values rear from ego center)" 52 "distance (positive values are front, negative values rear from ego center)" 51 "distance (positive values are front, negative values rear from ego center)" 50 "distance (positive values are front, negative values rear from ego center)" 49 "distance (positive values are front, negative values rear from ego center)" 48 "distance (positive values are front, negative values rear from ego center)" 47 "distance (positive values are front, negative values rear from ego center)" 46 "distance (positive values are front, negative values rear from ego center)" 45 "distance (positive values are front, negative values rear from ego center)" 44 "distance (positive values are front, negative values rear from ego center)" 43 "distance (positive values are front, negative values rear from ego center)" 42 "distance (positive values are front, negative values rear from ego center)" 41 "distance (positive values are front, negative values rear from ego center)" 40 "distance (positive values are front, negative values rear from ego center)" 39 "distance (positive values are front, negative values rear from ego center)" 38 "distance (positive values are front, negative values rear from ego center)" 37 "distance (positive values are front, negative values rear from ego center)" 36 "distance (positive values are front, negative values rear from ego center)" 35 "distance (positive values are front, negative values rear from ego center)" 34 "distance (positive values are front, negative values rear from ego center)" 33 "distance (positive values are front, negative values rear from ego center)" 32 "distance (positive values are front, negative values rear from ego center)" 31 "distance (positive values are front, negative values rear from ego center)" 30 "distance (positive values are front, negative values rear from ego center)" 29 "distance (positive values are front, negative values rear from ego center)" 28 "distance (positive values are front, negative values rear from ego center)" 27 "distance (positive values are front, negative values rear from ego center)" 26 "distance (positive values are front, negative values rear from ego center)" 25 "distance (positive values are front, negative values rear from ego center)" 24 "distance (positive values are front, negative values rear from ego center)" 23 "distance (positive values are front, negative values rear from ego center)" 22 "distance (positive values are front, negative values rear from ego center)" 21 "distance (positive values are front, negative values rear from ego center)" 20 "distance (positive values are front, negative values rear from ego center)" 19 "distance (positive values are front, negative values rear from ego center)" 18 "distance (positive values are front, negative values rear from ego center)" 17 "distance (positive values are front, negative values rear from ego center)" 16 "distance (positive values are front, negative values rear from ego center)" 15 "distance (positive values are front, negative values rear from ego center)" 14 "distance (positive values are front, negative values rear from ego center)" 13 "distance (positive values are front, negative values rear from ego center)" 12 "distance (positive values are front, negative values rear from ego center)" 11 "distance (positive values are front, negative values rear from ego center)" 10 "distance (positive values are front, negative values rear from ego center)" 9 "distance (positive values are front, negative values rear from ego center)" 8 "distance (positive values are front, negative values rear from ego center)" 7 "distance (positive values are front, negative values rear from ego center)" 6 "distance (positive values are front, negative values rear from ego center)" 5 "distance (positive values are front, negative values rear from ego center)" 4 "distance (positive values are front, negative values rear from ego center)" 3 "distance (positive values are front, negative values rear from ego center)" 2 "distance (positive values are front, negative values rear from ego center)" 1 "distance (positive values are front, negative values rear from ego center)" 0 "distance (positive values are front, negative values rear from ego center)" ;
VAL_ 547 AdasHmiNeighboringObj2YOut 255 "distance right from ego center" 254 "distance right from ego center" 253 "distance right from ego center" 252 "distance right from ego center" 251 "distance right from ego center" 250 "distance right from ego center" 249 "distance right from ego center" 248 "distance right from ego center" 247 "distance right from ego center" 246 "distance right from ego center" 245 "distance right from ego center" 244 "distance right from ego center" 243 "distance right from ego center" 242 "distance right from ego center" 241 "distance right from ego center" 240 "distance right from ego center" 239 "distance right from ego center" 238 "distance right from ego center" 237 "distance right from ego center" 236 "distance right from ego center" 235 "distance right from ego center" 234 "distance right from ego center" 233 "distance right from ego center" 232 "distance right from ego center" 231 "distance right from ego center" 230 "distance right from ego center" 229 "distance right from ego center" 228 "distance right from ego center" 227 "distance right from ego center" 226 "distance right from ego center" 225 "distance right from ego center" 224 "distance right from ego center" 223 "distance right from ego center" 222 "distance right from ego center" 221 "distance right from ego center" 220 "distance right from ego center" 219 "distance right from ego center" 218 "distance right from ego center" 217 "distance right from ego center" 216 "distance right from ego center" 215 "distance right from ego center" 214 "distance right from ego center" 213 "distance right from ego center" 212 "distance right from ego center" 211 "distance right from ego center" 210 "distance right from ego center" 209 "distance right from ego center" 208 "distance right from ego center" 207 "distance right from ego center" 206 "distance right from ego center" 205 "distance right from ego center" 204 "distance right from ego center" 203 "distance right from ego center" 202 "distance right from ego center" 201 "distance right from ego center" 200 "distance right from ego center" 199 "distance right from ego center" 198 "distance right from ego center" 197 "distance right from ego center" 196 "distance right from ego center" 195 "distance right from ego center" 194 "distance right from ego center" 193 "distance right from ego center" 192 "distance right from ego center" 191 "distance right from ego center" 190 "distance right from ego center" 189 "distance right from ego center" 188 "distance right from ego center" 187 "distance right from ego center" 186 "distance right from ego center" 185 "distance right from ego center" 184 "distance right from ego center" 183 "distance right from ego center" 182 "distance right from ego center" 181 "distance right from ego center" 180 "distance right from ego center" 179 "distance right from ego center" 178 "distance right from ego center" 177 "distance right from ego center" 176 "distance right from ego center" 175 "distance right from ego center" 174 "distance right from ego center" 173 "distance right from ego center" 172 "distance right from ego center" 171 "distance right from ego center" 170 "distance right from ego center" 169 "distance right from ego center" 168 "distance right from ego center" 167 "distance right from ego center" 166 "distance right from ego center" 165 "distance right from ego center" 164 "distance right from ego center" 163 "distance right from ego center" 162 "distance right from ego center" 161 "distance right from ego center" 160 "distance right from ego center" 159 "distance right from ego center" 158 "distance right from ego center" 157 "distance right from ego center" 156 "distance right from ego center" 155 "distance right from ego center" 154 "distance right from ego center" 153 "distance right from ego center" 152 "distance right from ego center" 151 "distance right from ego center" 150 "distance right from ego center" 149 "distance right from ego center" 148 "distance right from ego center" 147 "distance right from ego center" 146 "distance right from ego center" 145 "distance right from ego center" 144 "distance right from ego center" 143 "distance right from ego center" 142 "distance right from ego center" 141 "distance right from ego center" 140 "distance right from ego center" 139 "distance right from ego center" 138 "distance right from ego center" 137 "distance right from ego center" 136 "distance right from ego center" 135 "distance right from ego center" 134 "distance right from ego center" 133 "distance right from ego center" 132 "distance right from ego center" 131 "distance right from ego center" 130 "distance right from ego center" 129 "distance right from ego center" 128 "distance right from ego center" 127 "distance left from ego center" 126 "distance left from ego center" 125 "distance left from ego center" 124 "distance left from ego center" 123 "distance left from ego center" 122 "distance left from ego center" 121 "distance left from ego center" 120 "distance left from ego center" 119 "distance left from ego center" 118 "distance left from ego center" 117 "distance left from ego center" 116 "distance left from ego center" 115 "distance left from ego center" 114 "distance left from ego center" 113 "distance left from ego center" 112 "distance left from ego center" 111 "distance left from ego center" 110 "distance left from ego center" 109 "distance left from ego center" 108 "distance left from ego center" 107 "distance left from ego center" 106 "distance left from ego center" 105 "distance left from ego center" 104 "distance left from ego center" 103 "distance left from ego center" 102 "distance left from ego center" 101 "distance left from ego center" 100 "distance left from ego center" 99 "distance left from ego center" 98 "distance left from ego center" 97 "distance left from ego center" 96 "distance left from ego center" 95 "distance left from ego center" 94 "distance left from ego center" 93 "distance left from ego center" 92 "distance left from ego center" 91 "distance left from ego center" 90 "distance left from ego center" 89 "distance left from ego center" 88 "distance left from ego center" 87 "distance left from ego center" 86 "distance left from ego center" 85 "distance left from ego center" 84 "distance left from ego center" 83 "distance left from ego center" 82 "distance left from ego center" 81 "distance left from ego center" 80 "distance left from ego center" 79 "distance left from ego center" 78 "distance left from ego center" 77 "distance left from ego center" 76 "distance left from ego center" 75 "distance left from ego center" 74 "distance left from ego center" 73 "distance left from ego center" 72 "distance left from ego center" 71 "distance left from ego center" 70 "distance left from ego center" 69 "distance left from ego center" 68 "distance left from ego center" 67 "distance left from ego center" 66 "distance left from ego center" 65 "distance left from ego center" 64 "distance left from ego center" 63 "distance left from ego center" 62 "distance left from ego center" 61 "distance left from ego center" 60 "distance left from ego center" 59 "distance left from ego center" 58 "distance left from ego center" 57 "distance left from ego center" 56 "distance left from ego center" 55 "distance left from ego center" 54 "distance left from ego center" 53 "distance left from ego center" 52 "distance left from ego center" 51 "distance left from ego center" 50 "distance left from ego center" 49 "distance left from ego center" 48 "distance left from ego center" 47 "distance left from ego center" 46 "distance left from ego center" 45 "distance left from ego center" 44 "distance left from ego center" 43 "distance left from ego center" 42 "distance left from ego center" 41 "distance left from ego center" 40 "distance left from ego center" 39 "distance left from ego center" 38 "distance left from ego center" 37 "distance left from ego center" 36 "distance left from ego center" 35 "distance left from ego center" 34 "distance left from ego center" 33 "distance left from ego center" 32 "distance left from ego center" 31 "distance left from ego center" 30 "distance left from ego center" 29 "distance left from ego center" 28 "distance left from ego center" 27 "distance left from ego center" 26 "distance left from ego center" 25 "distance left from ego center" 24 "distance left from ego center" 23 "distance left from ego center" 22 "distance left from ego center" 21 "distance left from ego center" 20 "distance left from ego center" 19 "distance left from ego center" 18 "distance left from ego center" 17 "distance left from ego center" 16 "distance left from ego center" 15 "distance left from ego center" 14 "distance left from ego center" 13 "distance left from ego center" 12 "distance left from ego center" 11 "distance left from ego center" 10 "distance left from ego center" 9 "distance left from ego center" 8 "distance left from ego center" 7 "distance left from ego center" 6 "distance left from ego center" 5 "distance left from ego center" 4 "distance left from ego center" 3 "distance left from ego center" 2 "distance left from ego center" 1 "distance left from ego center" 0 "distance left from ego center" ;
VAL_ 547 AdasHmiNeighboringObj3ObjTyp 7 "reserved" 6 "three-wheeler 三轮车" 5 "bus 公共汽车" 4 "pedestrian 行人" 3 "motorbike/Bicycle 二轮车" 2 "truck 卡车" 1 "passenger car 小轿车" 0 "Object not present" ;
VAL_ 547 AdasHmiNeighboringObj3XOut 255 "distance (positive values are front, negative values rear from ego center)" 254 "distance (positive values are front, negative values rear from ego center)" 253 "distance (positive values are front, negative values rear from ego center)" 252 "distance (positive values are front, negative values rear from ego center)" 251 "distance (positive values are front, negative values rear from ego center)" 250 "distance (positive values are front, negative values rear from ego center)" 249 "distance (positive values are front, negative values rear from ego center)" 248 "distance (positive values are front, negative values rear from ego center)" 247 "distance (positive values are front, negative values rear from ego center)" 246 "distance (positive values are front, negative values rear from ego center)" 245 "distance (positive values are front, negative values rear from ego center)" 244 "distance (positive values are front, negative values rear from ego center)" 243 "distance (positive values are front, negative values rear from ego center)" 242 "distance (positive values are front, negative values rear from ego center)" 241 "distance (positive values are front, negative values rear from ego center)" 240 "distance (positive values are front, negative values rear from ego center)" 239 "distance (positive values are front, negative values rear from ego center)" 238 "distance (positive values are front, negative values rear from ego center)" 237 "distance (positive values are front, negative values rear from ego center)" 236 "distance (positive values are front, negative values rear from ego center)" 235 "distance (positive values are front, negative values rear from ego center)" 234 "distance (positive values are front, negative values rear from ego center)" 233 "distance (positive values are front, negative values rear from ego center)" 232 "distance (positive values are front, negative values rear from ego center)" 231 "distance (positive values are front, negative values rear from ego center)" 230 "distance (positive values are front, negative values rear from ego center)" 229 "distance (positive values are front, negative values rear from ego center)" 228 "distance (positive values are front, negative values rear from ego center)" 227 "distance (positive values are front, negative values rear from ego center)" 226 "distance (positive values are front, negative values rear from ego center)" 225 "distance (positive values are front, negative values rear from ego center)" 224 "distance (positive values are front, negative values rear from ego center)" 223 "distance (positive values are front, negative values rear from ego center)" 222 "distance (positive values are front, negative values rear from ego center)" 221 "distance (positive values are front, negative values rear from ego center)" 220 "distance (positive values are front, negative values rear from ego center)" 219 "distance (positive values are front, negative values rear from ego center)" 218 "distance (positive values are front, negative values rear from ego center)" 217 "distance (positive values are front, negative values rear from ego center)" 216 "distance (positive values are front, negative values rear from ego center)" 215 "distance (positive values are front, negative values rear from ego center)" 214 "distance (positive values are front, negative values rear from ego center)" 213 "distance (positive values are front, negative values rear from ego center)" 212 "distance (positive values are front, negative values rear from ego center)" 211 "distance (positive values are front, negative values rear from ego center)" 210 "distance (positive values are front, negative values rear from ego center)" 209 "distance (positive values are front, negative values rear from ego center)" 208 "distance (positive values are front, negative values rear from ego center)" 207 "distance (positive values are front, negative values rear from ego center)" 206 "distance (positive values are front, negative values rear from ego center)" 205 "distance (positive values are front, negative values rear from ego center)" 204 "distance (positive values are front, negative values rear from ego center)" 203 "distance (positive values are front, negative values rear from ego center)" 202 "distance (positive values are front, negative values rear from ego center)" 201 "distance (positive values are front, negative values rear from ego center)" 200 "distance (positive values are front, negative values rear from ego center)" 199 "distance (positive values are front, negative values rear from ego center)" 198 "distance (positive values are front, negative values rear from ego center)" 197 "distance (positive values are front, negative values rear from ego center)" 196 "distance (positive values are front, negative values rear from ego center)" 195 "distance (positive values are front, negative values rear from ego center)" 194 "distance (positive values are front, negative values rear from ego center)" 193 "distance (positive values are front, negative values rear from ego center)" 192 "distance (positive values are front, negative values rear from ego center)" 191 "distance (positive values are front, negative values rear from ego center)" 190 "distance (positive values are front, negative values rear from ego center)" 189 "distance (positive values are front, negative values rear from ego center)" 188 "distance (positive values are front, negative values rear from ego center)" 187 "distance (positive values are front, negative values rear from ego center)" 186 "distance (positive values are front, negative values rear from ego center)" 185 "distance (positive values are front, negative values rear from ego center)" 184 "distance (positive values are front, negative values rear from ego center)" 183 "distance (positive values are front, negative values rear from ego center)" 182 "distance (positive values are front, negative values rear from ego center)" 181 "distance (positive values are front, negative values rear from ego center)" 180 "distance (positive values are front, negative values rear from ego center)" 179 "distance (positive values are front, negative values rear from ego center)" 178 "distance (positive values are front, negative values rear from ego center)" 177 "distance (positive values are front, negative values rear from ego center)" 176 "distance (positive values are front, negative values rear from ego center)" 175 "distance (positive values are front, negative values rear from ego center)" 174 "distance (positive values are front, negative values rear from ego center)" 173 "distance (positive values are front, negative values rear from ego center)" 172 "distance (positive values are front, negative values rear from ego center)" 171 "distance (positive values are front, negative values rear from ego center)" 170 "distance (positive values are front, negative values rear from ego center)" 169 "distance (positive values are front, negative values rear from ego center)" 168 "distance (positive values are front, negative values rear from ego center)" 167 "distance (positive values are front, negative values rear from ego center)" 166 "distance (positive values are front, negative values rear from ego center)" 165 "distance (positive values are front, negative values rear from ego center)" 164 "distance (positive values are front, negative values rear from ego center)" 163 "distance (positive values are front, negative values rear from ego center)" 162 "distance (positive values are front, negative values rear from ego center)" 161 "distance (positive values are front, negative values rear from ego center)" 160 "distance (positive values are front, negative values rear from ego center)" 159 "distance (positive values are front, negative values rear from ego center)" 158 "distance (positive values are front, negative values rear from ego center)" 157 "distance (positive values are front, negative values rear from ego center)" 156 "distance (positive values are front, negative values rear from ego center)" 155 "distance (positive values are front, negative values rear from ego center)" 154 "distance (positive values are front, negative values rear from ego center)" 153 "distance (positive values are front, negative values rear from ego center)" 152 "distance (positive values are front, negative values rear from ego center)" 151 "distance (positive values are front, negative values rear from ego center)" 150 "distance (positive values are front, negative values rear from ego center)" 149 "distance (positive values are front, negative values rear from ego center)" 148 "distance (positive values are front, negative values rear from ego center)" 147 "distance (positive values are front, negative values rear from ego center)" 146 "distance (positive values are front, negative values rear from ego center)" 145 "distance (positive values are front, negative values rear from ego center)" 144 "distance (positive values are front, negative values rear from ego center)" 143 "distance (positive values are front, negative values rear from ego center)" 142 "distance (positive values are front, negative values rear from ego center)" 141 "distance (positive values are front, negative values rear from ego center)" 140 "distance (positive values are front, negative values rear from ego center)" 139 "distance (positive values are front, negative values rear from ego center)" 138 "distance (positive values are front, negative values rear from ego center)" 137 "distance (positive values are front, negative values rear from ego center)" 136 "distance (positive values are front, negative values rear from ego center)" 135 "distance (positive values are front, negative values rear from ego center)" 134 "distance (positive values are front, negative values rear from ego center)" 133 "distance (positive values are front, negative values rear from ego center)" 132 "distance (positive values are front, negative values rear from ego center)" 131 "distance (positive values are front, negative values rear from ego center)" 130 "distance (positive values are front, negative values rear from ego center)" 129 "distance (positive values are front, negative values rear from ego center)" 128 "distance (positive values are front, negative values rear from ego center)" 127 "distance (positive values are front, negative values rear from ego center)" 126 "distance (positive values are front, negative values rear from ego center)" 125 "distance (positive values are front, negative values rear from ego center)" 124 "distance (positive values are front, negative values rear from ego center)" 123 "distance (positive values are front, negative values rear from ego center)" 122 "distance (positive values are front, negative values rear from ego center)" 121 "distance (positive values are front, negative values rear from ego center)" 120 "distance (positive values are front, negative values rear from ego center)" 119 "distance (positive values are front, negative values rear from ego center)" 118 "distance (positive values are front, negative values rear from ego center)" 117 "distance (positive values are front, negative values rear from ego center)" 116 "distance (positive values are front, negative values rear from ego center)" 115 "distance (positive values are front, negative values rear from ego center)" 114 "distance (positive values are front, negative values rear from ego center)" 113 "distance (positive values are front, negative values rear from ego center)" 112 "distance (positive values are front, negative values rear from ego center)" 111 "distance (positive values are front, negative values rear from ego center)" 110 "distance (positive values are front, negative values rear from ego center)" 109 "distance (positive values are front, negative values rear from ego center)" 108 "distance (positive values are front, negative values rear from ego center)" 107 "distance (positive values are front, negative values rear from ego center)" 106 "distance (positive values are front, negative values rear from ego center)" 105 "distance (positive values are front, negative values rear from ego center)" 104 "distance (positive values are front, negative values rear from ego center)" 103 "distance (positive values are front, negative values rear from ego center)" 102 "distance (positive values are front, negative values rear from ego center)" 101 "distance (positive values are front, negative values rear from ego center)" 100 "distance (positive values are front, negative values rear from ego center)" 99 "distance (positive values are front, negative values rear from ego center)" 98 "distance (positive values are front, negative values rear from ego center)" 97 "distance (positive values are front, negative values rear from ego center)" 96 "distance (positive values are front, negative values rear from ego center)" 95 "distance (positive values are front, negative values rear from ego center)" 94 "distance (positive values are front, negative values rear from ego center)" 93 "distance (positive values are front, negative values rear from ego center)" 92 "distance (positive values are front, negative values rear from ego center)" 91 "distance (positive values are front, negative values rear from ego center)" 90 "distance (positive values are front, negative values rear from ego center)" 89 "distance (positive values are front, negative values rear from ego center)" 88 "distance (positive values are front, negative values rear from ego center)" 87 "distance (positive values are front, negative values rear from ego center)" 86 "distance (positive values are front, negative values rear from ego center)" 85 "distance (positive values are front, negative values rear from ego center)" 84 "distance (positive values are front, negative values rear from ego center)" 83 "distance (positive values are front, negative values rear from ego center)" 82 "distance (positive values are front, negative values rear from ego center)" 81 "distance (positive values are front, negative values rear from ego center)" 80 "distance (positive values are front, negative values rear from ego center)" 79 "distance (positive values are front, negative values rear from ego center)" 78 "distance (positive values are front, negative values rear from ego center)" 77 "distance (positive values are front, negative values rear from ego center)" 76 "distance (positive values are front, negative values rear from ego center)" 75 "distance (positive values are front, negative values rear from ego center)" 74 "distance (positive values are front, negative values rear from ego center)" 73 "distance (positive values are front, negative values rear from ego center)" 72 "distance (positive values are front, negative values rear from ego center)" 71 "distance (positive values are front, negative values rear from ego center)" 70 "distance (positive values are front, negative values rear from ego center)" 69 "distance (positive values are front, negative values rear from ego center)" 68 "distance (positive values are front, negative values rear from ego center)" 67 "distance (positive values are front, negative values rear from ego center)" 66 "distance (positive values are front, negative values rear from ego center)" 65 "distance (positive values are front, negative values rear from ego center)" 64 "distance (positive values are front, negative values rear from ego center)" 63 "distance (positive values are front, negative values rear from ego center)" 62 "distance (positive values are front, negative values rear from ego center)" 61 "distance (positive values are front, negative values rear from ego center)" 60 "distance (positive values are front, negative values rear from ego center)" 59 "distance (positive values are front, negative values rear from ego center)" 58 "distance (positive values are front, negative values rear from ego center)" 57 "distance (positive values are front, negative values rear from ego center)" 56 "distance (positive values are front, negative values rear from ego center)" 55 "distance (positive values are front, negative values rear from ego center)" 54 "distance (positive values are front, negative values rear from ego center)" 53 "distance (positive values are front, negative values rear from ego center)" 52 "distance (positive values are front, negative values rear from ego center)" 51 "distance (positive values are front, negative values rear from ego center)" 50 "distance (positive values are front, negative values rear from ego center)" 49 "distance (positive values are front, negative values rear from ego center)" 48 "distance (positive values are front, negative values rear from ego center)" 47 "distance (positive values are front, negative values rear from ego center)" 46 "distance (positive values are front, negative values rear from ego center)" 45 "distance (positive values are front, negative values rear from ego center)" 44 "distance (positive values are front, negative values rear from ego center)" 43 "distance (positive values are front, negative values rear from ego center)" 42 "distance (positive values are front, negative values rear from ego center)" 41 "distance (positive values are front, negative values rear from ego center)" 40 "distance (positive values are front, negative values rear from ego center)" 39 "distance (positive values are front, negative values rear from ego center)" 38 "distance (positive values are front, negative values rear from ego center)" 37 "distance (positive values are front, negative values rear from ego center)" 36 "distance (positive values are front, negative values rear from ego center)" 35 "distance (positive values are front, negative values rear from ego center)" 34 "distance (positive values are front, negative values rear from ego center)" 33 "distance (positive values are front, negative values rear from ego center)" 32 "distance (positive values are front, negative values rear from ego center)" 31 "distance (positive values are front, negative values rear from ego center)" 30 "distance (positive values are front, negative values rear from ego center)" 29 "distance (positive values are front, negative values rear from ego center)" 28 "distance (positive values are front, negative values rear from ego center)" 27 "distance (positive values are front, negative values rear from ego center)" 26 "distance (positive values are front, negative values rear from ego center)" 25 "distance (positive values are front, negative values rear from ego center)" 24 "distance (positive values are front, negative values rear from ego center)" 23 "distance (positive values are front, negative values rear from ego center)" 22 "distance (positive values are front, negative values rear from ego center)" 21 "distance (positive values are front, negative values rear from ego center)" 20 "distance (positive values are front, negative values rear from ego center)" 19 "distance (positive values are front, negative values rear from ego center)" 18 "distance (positive values are front, negative values rear from ego center)" 17 "distance (positive values are front, negative values rear from ego center)" 16 "distance (positive values are front, negative values rear from ego center)" 15 "distance (positive values are front, negative values rear from ego center)" 14 "distance (positive values are front, negative values rear from ego center)" 13 "distance (positive values are front, negative values rear from ego center)" 12 "distance (positive values are front, negative values rear from ego center)" 11 "distance (positive values are front, negative values rear from ego center)" 10 "distance (positive values are front, negative values rear from ego center)" 9 "distance (positive values are front, negative values rear from ego center)" 8 "distance (positive values are front, negative values rear from ego center)" 7 "distance (positive values are front, negative values rear from ego center)" 6 "distance (positive values are front, negative values rear from ego center)" 5 "distance (positive values are front, negative values rear from ego center)" 4 "distance (positive values are front, negative values rear from ego center)" 3 "distance (positive values are front, negative values rear from ego center)" 2 "distance (positive values are front, negative values rear from ego center)" 1 "distance (positive values are front, negative values rear from ego center)" 0 "distance (positive values are front, negative values rear from ego center)" ;
VAL_ 291 PdcuFrntAxleTrqMinLimVld 1 "Valid" 0 "Invalid" ;
VAL_ 291 PdcuReAxleTrqReqVld 1 "Valid" 0 "Invalid" ;
VAL_ 291 PdcuReAxleTrqActVld 1 "Valid" 0 "Invalid" ;
VAL_ 292 PdcuReAxleTrqMaxLimVld 1 "Valid" 0 "Invalid" ;
VAL_ 292 PdcuReAxleTrqMinLimVld 1 "Valid" 0 "Invalid" ;
VAL_ 292 PdcuWhelTrqMaxLimVld 1 "Valid" 0 "Invalid" ;
VAL_ 293 PdcuWhelTrqMinLimVld 1 "Valid" 0 "Invalid" ;
VAL_ 293 PdcuWhelTrqReqVld 1 "Valid" 0 "Invalid" ;
VAL_ 293 PdcuWhelTrqActVld 1 "Valid" 0 "Invalid" ;
VAL_ 306 WCBS_St_FrntAxleTrqIntv 1 "Active" 0 "Inactive" ;
VAL_ 306 WCBS_N_FrntAxleFastReductionTrqReq 16383 "Invalid" ;
VAL_ 306 WCBS_St_FrntAxleDTCIntv 1 "Active" 0 "Inactive" ;
VAL_ 306 WCBS_N_FrntAxleDTCTrqReq 16383 "Invalid" ;
VAL_ 306 WCBS_RPAavailable 1 "Available" 0 "Not Available" ;
VAL_ 306 WCBS_MEBavailable 1 "Available" 0 "Not Available" ;
VAL_ 306 WCBS_APLCSts 7 "Reserved" 6 "Reserved" 5 "Reserved" 4 "Reserved" 3 "ActiveHPA" 2 "Active RPA" 1 "Active APAMRA" 0 "Not Active" ;
VAL_ 306 WCBS_ActvIndcn_MEB 1 "Active" 0 "Not Active" ;
VAL_ 306 WCBS_APLCFailureSts 7 "Reserved" 6 "Message Error" 5 "Error" 4 "RPA trigger without secure" 3 "too high speed" 2 "Unexpected EPB Action" 1 "RPA too high slope" 0 "No Error" ;
VAL_ 306 WCBS_BrakeHld 1 "True 保压中" 0 "False 未保压" ;
VAL_ 306 WCBS_ADASL12AvlSts 1 "Available" 0 "Not Available" ;
VAL_ 306 WCBS_LgtReqModeACtiveSts 3 "Reserved" 2 "Active_l3" 1 "Active_l12" 0 "Not active" ;
VAL_ 306 WCBS_ADLCFailureSts 7 "Reserved" 6 "Reserved" 5 "Reserved" 4 "Reserved" 3 "Over speed" 2 "Error" 1 "Message Error" 0 "No Error" ;
VAL_ 306 WCBS_APAavailable 1 "Available" 0 "Not Available" ;
VAL_ 306 WCBS_OMPavailable 1 "Available" 0 "Not Available" ;
VAL_ 307 WCBS_St_ReAxleTrqIntv 1 "Active" 0 "Inactive" ;
VAL_ 307 WCBS_N_ReAxleFastReductionTrqReq 16383 "Invalid" ;
VAL_ 307 WCBS_St_ReAxleDTCIntv 1 "Active" 0 "Inactive" ;
VAL_ 307 WCBS_N_ReAxleDTCTrqReq 16383 "Invalid" ;
VAL_ 337 TM2CrtTqVld 3 "Reserved" 2 "Invalid" 1 "Valid" 0 "Initializing" ;
VAL_ 337 TM2CrtRotDir 3 "Reserved" 2 "反转(倒车模式)" 1 "正转(前进模式)" 0 "待机状态" ;
VAL_ 337 TM2CrtSpd 65535 "Invalid" ;
VAL_ 337 TM2CrtTq 65535 "Invalid" ;
VAL_ 337 TM2CrtSpdSigVld 3 "Reserved" 2 "Invalid" 1 "Valid" 0 "Initializing" ;
VAL_ 337 TM2ElockSt 6 "分离中" 5 "锁止完成" 4 "锁止中（需干预）" 3 "锁止中" 2 "拒绝锁止" 1 "等待满足锁止条件" 0 "分离完成" ;
VAL_ 337 TM2ELockMod 8 "故障状态" 7 "分离中状态" 6 "超速警报" 5 "锁止状态" 4 "等待干预状态" 3 "锁止中状态" 2 "拒绝锁止" 1 "分离状态" ;
VAL_ 545 TM2MaxTqPeak 65535 "Invalid" ;
VAL_ 545 TM2MinTqPeak 65535 "Invalid" ;
VAL_ 545 TM2MaxTqCon 65535 "Invalid" ;
VAL_ 545 TM2MinTqCon 65535 "Invalid" ;
VAL_ 336 TM1CrtTqVld 3 "Reserved" 2 "Invalid" 1 "Valid" 0 "Initializing" ;
VAL_ 336 TM1CrtRotDir 3 "Reserved" 2 "反转(倒车模式)" 1 "正转(前进模式)" 0 "待机状态" ;
VAL_ 336 TM1CrtSpd 65535 "Invalid" ;
VAL_ 336 TM1CrtTq 65535 "Invalid" ;
VAL_ 336 TM1CrtSpdSigVld 3 "Reserved" 2 "Invalid" 1 "Valid" 0 "Initializing" ;
VAL_ 551 TM1MaxTqPeak 65535 "Invalid" ;
VAL_ 551 TM1MinTqPeak 65535 "Invalid" ;
VAL_ 551 TM1MaxTqCon 65535 "Invalid" ;
VAL_ 551 TM1MinTqCon 65535 "Invalid" ;
VAL_ 325 PdcuPTSupportAcc 1 "error" 0 "no error" ;
VAL_ 325 PdcuPTCancelReq 1 "request" 0 "no request" ;
VAL_ 325 PDCU_GearUnderCtrlSts 7 "Reserved 保留" 6 "Reserved 保留" 5 "Reserved 保留" 4 "Reserved 保留" 3 "Failed  失败" 2 "Active For Control 激活" 1 "Available For Control 可用" 0 "Inhibit 禁止" ;
VAL_ 322 EPS2_St_Calibrated 1 "Calibrated" 0 "Not calibrated" ;
VAL_ 322 EPS2_LKAorESSFuncResq 3 "RESERVED" 2 "ESS Torque Response" 1 "LKA Torque Response" 0 "NO Response" ;
VAL_ 322 EPS2_F_SteeringAngle 1 "Invalid" 0 "Valid" ;
VAL_ 322 EPS2_InhibitCode 15 "Reserved" 14 "Reserved" 13 "Reserved" 12 "ADASExcessAngleDeviation" 11 "ADASAbnormalCANInput" 10 "ADASDriverInterference" 9 "ADASOverspeed" 8 "Reserved" 7 "Reserved" 6 "Reserved" 5 "APAEPSfailure" 4 "APAExcessAngleDeviation" 3 "APAAbnormalCANInput" 2 "APADriverInterference" 1 "APAOverspeed" 0 "NormalOperation" ;
VAL_ 322 EPS2_GapFeedback 4 "reserved" 3 "20 Gap" 2 "5 timesGap" 1 "5 Gap" 0 "NO" ;
VAL_ 322 EPS2_N_SteeringAngle 65535 "Invalid" ;
VAL_ 322 EPS2_N_RotationSpeed 4095 "Invalid" ;
VAL_ 322 EPS2_N_ESSRotationSpeedFB 4095 "Invalid" ;
